VERSION ""

NS_ :

BS_:

BU_: MPAD CVADAS ADCAM ORC EVCU2 EPS ECM CVPAM CADM BSM2 BSM

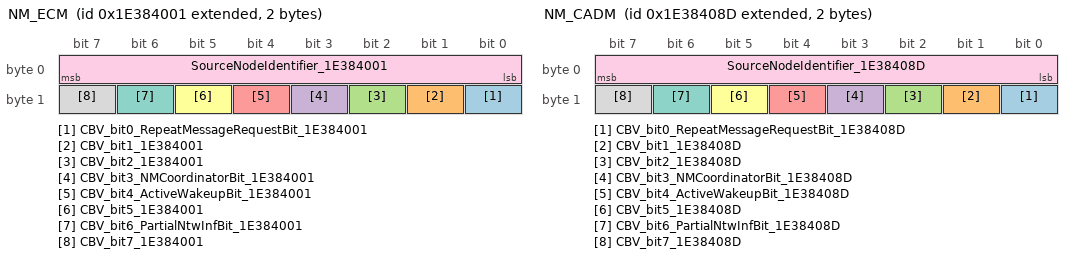
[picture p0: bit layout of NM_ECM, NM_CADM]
BO_ 2654486529 NM_ECM: 2 ECM
 SG_ CBV_bit0_RepeatMessageRequestBit_1E384001 : 8|1@0+ (1,0) [0|1] "" CVADAS,ADCAM,EVCU2,BSM2,CVPAM,CADM,BSM,ORC,EPS
 SG_ CBV_bit1_1E384001 : 9|1@0+ (1,0) [0|1] "" CVADAS,ADCAM,EVCU2,BSM2,CVPAM,CADM,BSM,ORC,EPS
 SG_ CBV_bit2_1E384001 : 10|1@0+ (1,0) [0|1] "" CVADAS,ADCAM,EVCU2,BSM2,CVPAM,CADM,BSM,ORC,EPS
 SG_ CBV_bit3_NMCoordinatorBit_1E384001 : 11|1@0+ (1,0) [0|1] "" CVADAS,ADCAM,EVCU2,BSM2,CVPAM,CADM,BSM,ORC,EPS
 SG_ CBV_bit4_ActiveWakeupBit_1E384001 : 12|1@0+ (1,0) [0|1] "" CVADAS,ADCAM,EVCU2,BSM2,CVPAM,CADM,BSM,ORC,EPS
 SG_ CBV_bit5_1E384001 : 13|1@0+ (1,0) [0|1] "" CVADAS,ADCAM,EVCU2,BSM2,CVPAM,CADM,BSM,ORC,EPS
 SG_ CBV_bit6_PartialNtwInfBit_1E384001 : 14|1@0+ (1,0) [0|1] "" CVADAS,ADCAM,EVCU2,BSM2,CVPAM,CADM,BSM,ORC,EPS
 SG_ CBV_bit7_1E384001 : 15|1@0+ (1,0) [0|1] "" CVADAS,ADCAM,EVCU2,BSM2,CVPAM,CADM,BSM,ORC,EPS
 SG_ SourceNodeIdentifier_1E384001 : 7|8@0+ (1,0) [0|255] "-"  CVADAS,ADCAM,EVCU2,BSM2,CVPAM,CADM,BSM,ORC,EPS

BO_ 2654486669 NM_CADM: 2 CADM
 SG_ CBV_bit0_RepeatMessageRequestBit_1E38408D : 8|1@0+ (1,0) [0|1] "" CVADAS,EVCU2,BSM2,CVPAM,BSM,ORC,EPS,ECM
 SG_ CBV_bit1_1E38408D : 9|1@0+ (1,0) [0|1] "" CVADAS,EVCU2,BSM2,CVPAM,BSM,ORC,EPS,ECM
 SG_ CBV_bit2_1E38408D : 10|1@0+ (1,0) [0|1] "" CVADAS,EVCU2,BSM2,CVPAM,BSM,ORC,EPS,ECM
 SG_ CBV_bit3_NMCoordinatorBit_1E38408D : 11|1@0+ (1,0) [0|1] "" CVADAS,EVCU2,BSM2,CVPAM,BSM,ORC,EPS,ECM
 SG_ CBV_bit4_ActiveWakeupBit_1E38408D : 12|1@0+ (1,0) [0|1] "" CVADAS,EVCU2,BSM2,CVPAM,BSM,ORC,EPS,ECM
 SG_ CBV_bit5_1E38408D : 13|1@0+ (1,0) [0|1] "" CVADAS,EVCU2,BSM2,CVPAM,BSM,ORC,EPS,ECM
 SG_ CBV_bit6_PartialNtwInfBit_1E38408D : 14|1@0+ (1,0) [0|1] "" CVADAS,EVCU2,BSM2,CVPAM,BSM,ORC,EPS,ECM
 SG_ CBV_bit7_1E38408D : 15|1@0+ (1,0) [0|1] "" CVADAS,EVCU2,BSM2,CVPAM,BSM,ORC,EPS,ECM
 SG_ SourceNodeIdentifier_1E38408D : 7|8@0+ (1,0) [0|255] "-"  CVADAS,EVCU2,BSM2,CVPAM,BSM,ORC,EPS,ECM

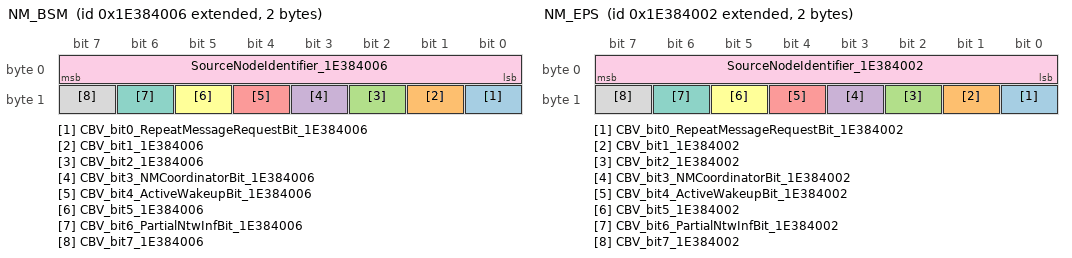
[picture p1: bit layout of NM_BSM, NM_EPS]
BO_ 2654486534 NM_BSM: 2 BSM
 SG_ CBV_bit0_RepeatMessageRequestBit_1E384006 : 8|1@0+ (1,0) [0|1] "" CVADAS,ADCAM,MPAD,EVCU2,BSM2,CVPAM,CADM,ORC,EPS,ECM
 SG_ CBV_bit1_1E384006 : 9|1@0+ (1,0) [0|1] "" CVADAS,ADCAM,MPAD,EVCU2,BSM2,CVPAM,CADM,ORC,EPS,ECM
 SG_ CBV_bit2_1E384006 : 10|1@0+ (1,0) [0|1] "" CVADAS,ADCAM,MPAD,EVCU2,BSM2,CVPAM,CADM,ORC,EPS,ECM
 SG_ CBV_bit3_NMCoordinatorBit_1E384006 : 11|1@0+ (1,0) [0|1] "" CVADAS,ADCAM,MPAD,EVCU2,BSM2,CVPAM,CADM,ORC,EPS,ECM
 SG_ CBV_bit4_ActiveWakeupBit_1E384006 : 12|1@0+ (1,0) [0|1] "" CVADAS,ADCAM,MPAD,EVCU2,BSM2,CVPAM,CADM,ORC,EPS,ECM
 SG_ CBV_bit5_1E384006 : 13|1@0+ (1,0) [0|1] "" CVADAS,ADCAM,MPAD,EVCU2,BSM2,CVPAM,CADM,ORC,EPS,ECM
 SG_ CBV_bit6_PartialNtwInfBit_1E384006 : 14|1@0+ (1,0) [0|1] "" CVADAS,ADCAM,MPAD,EVCU2,BSM2,CVPAM,CADM,ORC,EPS,ECM
 SG_ CBV_bit7_1E384006 : 15|1@0+ (1,0) [0|1] "" CVADAS,ADCAM,MPAD,EVCU2,BSM2,CVPAM,CADM,ORC,EPS,ECM
 SG_ SourceNodeIdentifier_1E384006 : 7|8@0+ (1,0) [0|255] "-"  CVADAS,ADCAM,MPAD,EVCU2,BSM2,CVPAM,CADM,ORC,EPS,ECM

BO_ 262 ENGINE_FD_2: 64 ECM
 SG_ PowertrainPrplsnActv : 181|1@0+ (1,0) [0|1] "" ADCAM,CADM,BSM
 SG_ MessageCounter_ENGINE2 : 435|4@0+ (1,0) [0|15] "-"  CVADAS,ADCAM,CVPAM,CADM,BSM,EPS
 SG_ LV12PwrFreeRq_W : 176|1@0+ (1,0) [0|1] "-"  Vector__XXX
 SG_ GasPedalPositionFailSts_W : 169|1@0+ (1,0) [0|1] "-"  ADCAM,CADM,BSM
 SG_ GasPedalPosition_W : 143|8@0+ (0.392,0) [0|99.568] "%"  ADCAM,BSM
 SG_ ESS_ENG_ST_W : 175|4@0+ (1,0) [0|15] "-"  CVADAS,ADCAM,CADM,BSM,EPS
 SG_ EngineSts_W : 87|2@0+ (1,0) [0|3] "-"  CVADAS,ADCAM,CVPAM,CADM,BSM,EPS
 SG_ EngineSpeed_W : 21|14@0+ (1,0) [0|16382] "1/min"  ADCAM,CADM,BSM,EPS
 SG_ ECM_LHOM_W : 188|1@0+ (1,0) [0|1] "-"  ADCAM,CADM
 SG_ CRC_ENGINE2 : 447|8@0+ (1,0) [0|255] "-"  CVADAS,ADCAM,CVPAM,CADM,BSM,EPS

BO_ 258 BRAKE_FD_2: 64 BSM
 SG_ YawRateFailSts_BSM : 87|1@0+ (1,0) [0|1] "-"  CVADAS,ADCAM,MPAD,CVPAM,CADM,EPS
 SG_ YawRate_BSM : 67|12@0+ (0.08,-163.84) [-163.84|163.68] "deg/s"  CVADAS,ADCAM,MPAD,CVPAM,CADM,EPS
 SG_ VehicleSpeedVSOSig : 4|13@0+ (0.0625,0) [0|511.875] "Km/h"  CVADAS,ADCAM,MPAD,EVCU2,BSM2,CVPAM,CADM,EPS,ECM
 SG_ TorqueRequest : 98|11@0+ (1,-500) [-500|1546] "-"  Vector__XXX
 SG_ TorqueReduct : 158|1@0+ (1,0) [0|1] "-"  Vector__XXX
 SG_ TorqueIncrease : 175|1@0+ (1,0) [0|1] "-"  Vector__XXX
 SG_ Slope : 135|8@0+ (1,-100) [-100|154] "%"  CVADAS,CVPAM,CADM
 SG_ PrefillActive : 86|1@0+ (1,0) [0|1] "-"  ADCAM,MPAD,CADM
 SG_ MessageCounter_BRAKE2 : 435|4@0+ (1,0) [0|15] "-"  CVADAS,ADCAM,EVCU2,BSM2,CVPAM,CADM,EPS,ECM
 SG_ LongAccelerationFailSts_BSM : 69|1@0+ (1,0) [0|1] "-"  CVADAS,ADCAM,MPAD,CVPAM,CADM
 SG_ LongAcceleration_BSM : 35|12@0+ (0.02,-40.96) [-40.96|40.92] "m/s^2"  CVADAS,ADCAM,MPAD,CVPAM,CADM,EPS
 SG_ LatAccelerationFailSts_BSM : 68|1@0+ (1,0) [0|1] "-"  CVADAS,ADCAM,MPAD,CVPAM,CADM
 SG_ LatAcceleration_BSM : 19|12@0+ (0.02,-40.96) [-40.96|40.92] "m/s^2"  CVADAS,ADCAM,MPAD,CVPAM,CADM,EPS
 SG_ InternalError_BSM : 191|1@0+ (1,0) [0|1] "-"  ADCAM,MPAD,CADM
 SG_ ESP_Sys_Stat : 71|2@0+ (1,0) [0|3] "-"  Vector__XXX
 SG_ ESCActive : 84|1@0+ (1,0) [0|1] "-"  MPAD,EVCU2,CVPAM,CADM
 SG_ CRC_BRAKE2 : 447|8@0+ (1,0) [0|255] "-"  CVADAS,ADCAM,EVCU2,BSM2,CVPAM,CADM,EPS,ECM
 SG_ BrakePedalPressure : 386|11@0+ (0.1,0) [0|200] "bar"  EVCU2,ECM
 SG_ BrakeInterventionSts : 103|1@0+ (1,0) [0|1] "-"  ADCAM,MPAD,BSM2,CADM
 SG_ BrakeBoostStat : 439|4@0+ (1,0) [0|14] "-"  Vector__XXX
 SG_ BrakeBoostPressure : 370|11@0+ (0.1,0) [0|200] "bar"  EVCU2,ECM
 SG_ Brake_MaxRegen_Ready : 359|2@0+ (1,0) [0|2] "-"  EVCU2
 SG_ ABSActive : 83|1@0+ (1,0) [0|1] "-"  MPAD,EVCU2,CVPAM,CADM,ECM
 SG_ WheelRPM_FR : 295|16@0+ (0.001953125,0) [0|127.9961] "Rev/s"  EVCU2,EPS
 SG_ WheelRPM_FL : 279|16@0+ (0.001953125,0) [0|127.9961] "Rev/s"  EVCU2,EPS
 SG_ Brk_Stat : 343|2@0+ (1,0) [0|2] "-"  CVADAS,ADCAM,MPAD,EVCU2,CVPAM,CADM,ECM
 SG_ PPPA_Engine_Torque_Enabled_BSM : 5|1@0+ (1,0) [0|1] "" Vector__XXX
 SG_ ParkingGearShiftReq_BSM : 22|3@0+ (1,0) [0|6] "" CVADAS,CVPAM
 SG_ ParkingInterventionSts : 7|2@0+ (1,0) [0|3] "" CVADAS,CVPAM
 SG_ BSM_ESASystemSts : 239|3@0+ (1,0) [0|6] "" CADM,EPS

BO_ 2654486530 NM_EPS: 2 EPS
 SG_ CBV_bit0_RepeatMessageRequestBit_1E384002 : 8|1@0+ (1,0) [0|1] "" CVADAS,ADCAM,MPAD,EVCU2,BSM2,CVPAM,CADM,BSM,ORC,ECM
 SG_ CBV_bit1_1E384002 : 9|1@0+ (1,0) [0|1] "" CVADAS,ADCAM,MPAD,EVCU2,BSM2,CVPAM,CADM,BSM,ORC,ECM
 SG_ CBV_bit2_1E384002 : 10|1@0+ (1,0) [0|1] "" CVADAS,ADCAM,MPAD,EVCU2,BSM2,CVPAM,CADM,BSM,ORC,ECM
 SG_ CBV_bit3_NMCoordinatorBit_1E384002 : 11|1@0+ (1,0) [0|1] "" CVADAS,ADCAM,MPAD,EVCU2,BSM2,CVPAM,CADM,BSM,ORC,ECM
 SG_ CBV_bit4_ActiveWakeupBit_1E384002 : 12|1@0+ (1,0) [0|1] "" CVADAS,ADCAM,MPAD,EVCU2,BSM2,CVPAM,CADM,BSM,ORC,ECM
 SG_ CBV_bit5_1E384002 : 13|1@0+ (1,0) [0|1] "" CVADAS,ADCAM,MPAD,EVCU2,BSM2,CVPAM,CADM,BSM,ORC,ECM
 SG_ CBV_bit6_PartialNtwInfBit_1E384002 : 14|1@0+ (1,0) [0|1] "" CVADAS,ADCAM,MPAD,EVCU2,BSM2,CVPAM,CADM,BSM,ORC,ECM
 SG_ CBV_bit7_1E384002 : 15|1@0+ (1,0) [0|1] "" CVADAS,ADCAM,MPAD,EVCU2,BSM2,CVPAM,CADM,BSM,ORC,ECM
 SG_ SourceNodeIdentifier_1E384002 : 7|8@0+ (1,0) [0|255] "-"  CVADAS,ADCAM,MPAD,EVCU2,BSM2,CVPAM,CADM,BSM,ORC,ECM

BO_ 524 BRAKE2_FD_2: 32 BSM2
 SG_ VehicleStandStillSts_B2 : 47|2@0+ (1,0) [0|2] "" MPAD,CADM,BSM
 SG_ BSM2_OpStat : 50|3@0+ (1,0) [0|5] "" MPAD,CADM,BSM
 SG_ Brake_OpStat_Sec : 53|3@0+ (1,0) [0|5] "" MPAD,CADM
 SG_ MessageCounter_BRAKE2_2 : 179|4@0+ (1,0) [0|15] "-"  MPAD,CADM,BSM,ORC
 SG_ CRC_BRAKE2_2 : 191|8@0+ (1,0) [0|255] "-"  MPAD,CADM,BSM,ORC
 SG_ BrkTrq_B2 : 6|15@0+ (3,0) [0|98301] "Nm"  MPAD,CADM
 SG_ BSM2_HEALTH_CHECK : 63|8@0+ (1,0) [0|255] "" BSM
 SG_ AEB_Type_Brk_B2 : 43|4@0+ (1,0) [0|15] "" MPAD,CADM

BO_ 257 BRAKE2_FD_1: 64 BSM2
 SG_ VehicleSpeedVSOSig_B2 : 36|13@0+ (0.0625,0) [0|511.875] "Km/h"  CVADAS,MPAD,CVPAM,CADM,EPS
 SG_ RHFWheelSpeed_B2 : 68|13@0+ (0.0625,0) [0|511.875] "Km/h"  MPAD,CADM
 SG_ RHF_FastPulseCounter_B2 : 95|8@0+ (1,0) [0|255] "pulse"  MPAD,CADM
 SG_ LHFWheelSpeed_B2 : 52|13@0+ (0.0625,0) [0|511.875] "Km/h"  MPAD,CADM
 SG_ LHF_FastPulseCounter_B2 : 87|8@0+ (1,0) [0|255] "pulse"  MPAD,CADM
 SG_ RHF_WheelSensorFailSts_B2 : 69|1@0+ (1,0) [0|1] "" MPAD,CADM
 SG_ RHF_Spin_B2 : 55|2@0+ (1,0) [0|3] "" MPAD,CADM
 SG_ MessageCounter_BRAKE2_1 : 435|4@0+ (1,0) [0|15] "-"  CVADAS,CADM,ORC,EPS
 SG_ LHF_WheelSensorFailSts_B2 : 53|1@0+ (1,0) [0|1] "" MPAD,CADM
 SG_ LHF_Spin_B2 : 39|2@0+ (1,0) [0|3] "" MPAD,CADM
 SG_ Inlet_Pressure_Pos : 98|2@0+ (1,0) [0|2] "" MPAD,CADM
 SG_ CRC_BRAKE2_1 : 447|8@0+ (1,0) [0|255] "-"  CVADAS,CADM,ORC,EPS
 SG_ Brk_Stat_B2 : 71|2@0+ (1,0) [0|2] "" MPAD,CADM
 SG_ ABSActive_B2 : 37|1@0+ (1,0) [0|1] "" MPAD,CADM
 SG_ Rear_Diff_BSM_RQ_B2 : 156|2@0+ (1,0) [0|2] "-"  Vector__XXX
 SG_ R_DIFF_TRQ_RQ_B2 : 151|9@0+ (10,0) [0|5100] "Nm"  Vector__XXX
 SG_ Ft_RrTrqCoupling_ModeRq_B2 : 158|2@0+ (1,0) [0|3] "-"  Vector__XXX
 SG_ Ft_RrAxleCoupling_TrqRq_B2 : 143|8@0+ (12,0) [0|3060] "Nm"  Vector__XXX

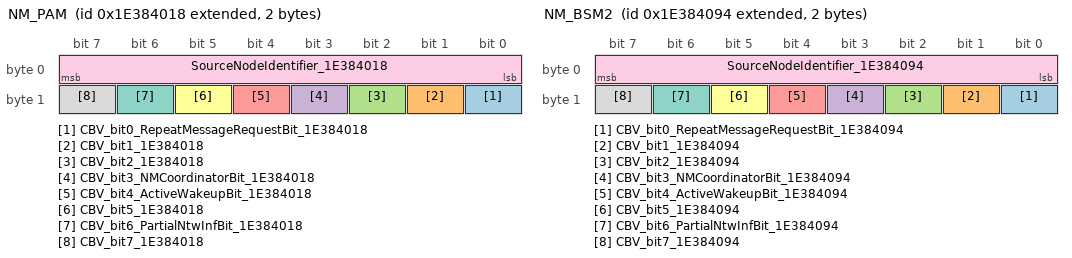
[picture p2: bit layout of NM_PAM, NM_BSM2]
BO_ 2654486552 NM_PAM: 2 CVADAS
 SG_ CBV_bit0_RepeatMessageRequestBit_1E384018 : 8|1@0+ (1,0) [0|1] "" ADCAM,MPAD,EVCU2,BSM2,CADM,BSM,ORC,EPS,ECM
 SG_ CBV_bit1_1E384018 : 9|1@0+ (1,0) [0|1] "" ADCAM,MPAD,EVCU2,BSM2,CADM,BSM,ORC,EPS,ECM
 SG_ CBV_bit2_1E384018 : 10|1@0+ (1,0) [0|1] "" ADCAM,MPAD,EVCU2,BSM2,CADM,BSM,ORC,EPS,ECM
 SG_ CBV_bit3_NMCoordinatorBit_1E384018 : 11|1@0+ (1,0) [0|1] "" ADCAM,MPAD,EVCU2,BSM2,CADM,BSM,ORC,EPS,ECM
 SG_ CBV_bit4_ActiveWakeupBit_1E384018 : 12|1@0+ (1,0) [0|1] "" ADCAM,MPAD,EVCU2,BSM2,CADM,BSM,ORC,EPS,ECM
 SG_ CBV_bit5_1E384018 : 13|1@0+ (1,0) [0|1] "" ADCAM,MPAD,EVCU2,BSM2,CADM,BSM,ORC,EPS,ECM
 SG_ CBV_bit6_PartialNtwInfBit_1E384018 : 14|1@0+ (1,0) [0|1] "" ADCAM,MPAD,EVCU2,BSM2,CADM,BSM,ORC,EPS,ECM
 SG_ CBV_bit7_1E384018 : 15|1@0+ (1,0) [0|1] "" ADCAM,MPAD,EVCU2,BSM2,CADM,BSM,ORC,EPS,ECM
 SG_ SourceNodeIdentifier_1E384018 : 7|8@0+ (1,0) [0|255] "-"  ADCAM,MPAD,EVCU2,BSM2,CADM,BSM,ORC,EPS,ECM

BO_ 2654486676 NM_BSM2: 2 BSM2
 SG_ CBV_bit0_RepeatMessageRequestBit_1E384094 : 8|1@0+ (1,0) [0|1] "" CVADAS,ADCAM,MPAD,EVCU2,CVPAM,CADM,BSM,ORC,EPS,ECM
 SG_ CBV_bit1_1E384094 : 9|1@0+ (1,0) [0|1] "" CVADAS,ADCAM,MPAD,EVCU2,CVPAM,CADM,BSM,ORC,EPS,ECM
 SG_ CBV_bit2_1E384094 : 10|1@0+ (1,0) [0|1] "" CVADAS,ADCAM,MPAD,EVCU2,CVPAM,CADM,BSM,ORC,EPS,ECM
 SG_ CBV_bit3_NMCoordinatorBit_1E384094 : 11|1@0+ (1,0) [0|1] "" CVADAS,ADCAM,MPAD,EVCU2,CVPAM,CADM,BSM,ORC,EPS,ECM
 SG_ CBV_bit4_ActiveWakeupBit_1E384094 : 12|1@0+ (1,0) [0|1] "" CVADAS,ADCAM,MPAD,EVCU2,CVPAM,CADM,BSM,ORC,EPS,ECM
 SG_ CBV_bit5_1E384094 : 13|1@0+ (1,0) [0|1] "" CVADAS,ADCAM,MPAD,EVCU2,CVPAM,CADM,BSM,ORC,EPS,ECM
 SG_ CBV_bit6_PartialNtwInfBit_1E384094 : 14|1@0+ (1,0) [0|1] "" CVADAS,ADCAM,MPAD,EVCU2,CVPAM,CADM,BSM,ORC,EPS,ECM
 SG_ CBV_bit7_1E384094 : 15|1@0+ (1,0) [0|1] "" CVADAS,ADCAM,MPAD,EVCU2,CVPAM,CADM,BSM,ORC,EPS,ECM
 SG_ SourceNodeIdentifier_1E384094 : 7|8@0+ (1,0) [0|255] "-"  CVADAS,ADCAM,MPAD,EVCU2,CVPAM,CADM,BSM,ORC,EPS,ECM

BO_ 727 CVPAM_FD_Data2: 64 CVADAS
 SG_ PA_SideSensor_RearRight_Dist : 49|10@0+ (1,0) [0|1022] "cm"  MPAD,CADM
 SG_ PA_SideSensor_RearRight_Conf : 102|2@0+ (1,0) [0|3] "" MPAD,CADM
 SG_ PA_SideSensor_RearLeft_Dist : 33|10@0+ (1,0) [0|1022] "cm"  MPAD,CADM
 SG_ PA_SideSensor_RearLeft_Conf : 100|2@0+ (1,0) [0|3] "" MPAD,CADM
 SG_ PA_SideSensor_FrontRight_Dist : 1|10@0+ (1,0) [0|1022] "cm"  MPAD,CADM
 SG_ PA_SideSensor_FrontRight_Conf : 55|2@0+ (1,0) [0|3] "" MPAD,CADM
 SG_ PA_SideSensor_FrontLeft_Dist : 17|10@0+ (1,0) [0|1022] "cm"  MPAD,CADM
 SG_ PA_SideSensor_FrontLeft_Conf : 98|2@0+ (1,0) [0|3] "" MPAD,CADM
 SG_ PA_Right_Sensor_Det_Health : 23|2@0+ (1,0) [0|2] "" MPAD,CADM
 SG_ PA_Line_RM_Style : 68|4@0+ (1,0) [0|7] "" MPAD,CADM
 SG_ PA_Line_RM_Heading : 96|9@0+ (0.5,-128) [-128|127.5] "deg"  MPAD,CADM
 SG_ PA_Line_RM_Color : 87|3@0+ (1,0) [0|4] "" MPAD,CADM
 SG_ PA_Line_LM_Style : 84|4@0+ (1,0) [0|7] "" MPAD,CADM
 SG_ PA_Line_LM_Heading : 112|9@0+ (0.5,-128) [-128|127.5] "deg"  MPAD,CADM
 SG_ PA_Line_LM_Color : 71|3@0+ (1,0) [0|4] "" MPAD,CADM
 SG_ PA_Left_Sensor_Det_Health : 7|2@0+ (1,0) [0|2] "" MPAD,CADM
 SG_ PA_Lane_Dection_Health : 39|2@0+ (1,0) [0|2] "" MPAD,CADM
 SG_ MessageCounter_CVPAM_FD_Data2 : 435|4@0+ (1,0) [0|15] "-"  MPAD,CADM
 SG_ MAC_CVPAM_FD_Data2 : 471|48@0+ (1,0) [0|0] "-"  MPAD,CADM
 SG_ CRC_CVPAM_FD_Data2 : 447|8@0+ (1,0) [0|255] "-"  MPAD,CADM
 SG_ Cntr_CVPAM_FD_Data2 : 455|16@0+ (1,0) [0|65535] "-"  MPAD,CADM
 SG_ PA_Line_RM_Heading_Conf : 37|4@0+ (1,0) [0|15] "" MPAD,CADM
 SG_ PA_Line_RM_Distance_Conf : 5|4@0+ (1,0) [0|15] "" MPAD,CADM
 SG_ PA_Line_RM_Distance : 64|9@0+ (1,0) [0|511] "cm"  MPAD,CADM
 SG_ PA_Line_LM_Heading_Conf : 53|4@0+ (1,0) [0|15] "" MPAD,CADM
 SG_ PA_Line_LM_Distance_Conf : 21|4@0+ (1,0) [0|15] "" MPAD,CADM
 SG_ PA_Line_LM_Distance : 80|9@0+ (1,0) [0|511] "cm"  MPAD,CADM
 SG_ Reserved_for_Functional_Safety_ : 431|12@0+ (0,0) [0|0] "" MPAD,CADM

BO_ 726 CVPAM_FD_Data: 64 CVADAS
 SG_ PA_Obj6_Type : 372|3@0+ (1,0) [0|7] "" MPAD,CADM
 SG_ PA_Obj6_Range_2 : 401|10@0+ (1,0) [0|1023] "cm"  MPAD,CADM
 SG_ PA_Obj6_Range : 81|10@0+ (1,0) [0|1023] "cm"  MPAD,CADM
 SG_ PA_Obj6_Conf : 115|2@0+ (1,0) [0|3] "" MPAD,CADM
 SG_ PA_Obj6_Angle_2 : 208|9@0+ (1,0) [0|511] "deg"  MPAD,CADM
 SG_ PA_Obj6_Angle : 304|9@0+ (1,0) [0|511] "deg"  MPAD,CADM
 SG_ PA_Obj5_Type : 375|3@0+ (1,0) [0|7] "" MPAD,CADM
 SG_ PA_Obj5_Range_2 : 385|10@0+ (1,0) [0|1023] "cm"  MPAD,CADM
 SG_ PA_Obj5_Range : 65|10@0+ (1,0) [0|1023] "cm"  MPAD,CADM
 SG_ PA_Obj5_Conf : 117|2@0+ (1,0) [0|3] "" MPAD,CADM
 SG_ PA_Obj5_Angle_2 : 192|9@0+ (1,0) [0|511] "deg"  MPAD,CADM
 SG_ PA_Obj5_Angle : 288|9@0+ (1,0) [0|511] "deg"  MPAD,CADM
 SG_ PA_Obj4_Type : 391|3@0+ (1,0) [0|7] "" MPAD,CADM
 SG_ PA_Obj4_Range_2 : 369|10@0+ (1,0) [0|1023] "cm"  MPAD,CADM
 SG_ PA_Obj4_Range : 49|10@0+ (1,0) [0|1023] "cm"  MPAD,CADM
 SG_ PA_Obj4_Conf : 119|2@0+ (1,0) [0|3] "" MPAD,CADM
 SG_ PA_Obj4_Angle_2 : 176|9@0+ (1,0) [0|511] "deg"  MPAD,CADM
 SG_ PA_Obj4_Angle : 272|9@0+ (1,0) [0|511] "deg"  MPAD,CADM
 SG_ PA_Obj3_Type : 388|3@0+ (1,0) [0|7] "" MPAD,CADM
 SG_ PA_Obj3_Range_2 : 353|10@0+ (1,0) [0|1023] "cm"  MPAD,CADM
 SG_ PA_Obj3_Range : 33|10@0+ (1,0) [0|1023] "cm"  MPAD,CADM
 SG_ PA_Obj3_Conf : 87|2@0+ (1,0) [0|3] "" MPAD,CADM
 SG_ PA_Obj3_Angle_2 : 160|9@0+ (1,0) [0|511] "deg"  MPAD,CADM
 SG_ PA_Obj3_Angle : 256|9@0+ (1,0) [0|511] "deg"  MPAD,CADM
 SG_ PA_Obj2_Type : 404|3@0+ (1,0) [0|7] "" MPAD,CADM
 SG_ PA_Obj2_Range_2 : 337|10@0+ (1,0) [0|1023] "cm"  MPAD,CADM
 SG_ PA_Obj2_Range : 17|10@0+ (1,0) [0|1023] "cm"  MPAD,CADM
 SG_ PA_Obj2_Conf : 71|2@0+ (1,0) [0|3] "" MPAD,CADM
 SG_ PA_Obj2_Angle_2 : 144|9@0+ (1,0) [0|511] "deg"  MPAD,CADM
 SG_ PA_Obj2_Angle : 240|9@0+ (1,0) [0|511] "deg"  MPAD,CADM
 SG_ PA_Obj1_Type : 407|3@0+ (1,0) [0|7] "" MPAD,CADM
 SG_ PA_Obj1_Range_2 : 321|10@0+ (1,0) [0|1023] "cm"  MPAD,CADM
 SG_ PA_Obj1_Range : 1|10@0+ (1,0) [0|1023] "cm"  MPAD,CADM
 SG_ PA_Obj1_Conf : 55|2@0+ (1,0) [0|3] "" MPAD,CADM
 SG_ PA_Obj1_Angle_2 : 128|9@0+ (1,0) [0|511] "deg"  MPAD,CADM
 SG_ PA_Obj1_Angle : 224|9@0+ (1,0) [0|511] "deg"  MPAD,CADM
 SG_ PA_Front_Sensor_Det_Health : 437|2@0+ (1,0) [0|2] "" MPAD,CADM
 SG_ MessageCounter_CVPAM_FD_Data : 435|4@0+ (1,0) [0|15] "-"  MPAD,CADM,EPS
 SG_ MAC_CVPAM_FD_Data : 471|48@0+ (1,0) [0|0] "-"  MPAD,CADM
 SG_ CRC_CVPAM_FD_Data : 447|8@0+ (1,0) [0|255] "-"  MPAD,CADM,EPS
 SG_ Cntr_CVPAM_FD_Data : 455|16@0+ (1,0) [0|65535] "-"  MPAD,CADM
 SG_ Reserved_for_functional_safety_2D6 : 417|12@0+ (0,0) [0|0] "" MPAD,CADM

BO_ 1156 BRAKE2_FD_3: 32 BSM2
 SG_ RollsModeAct_B2 : 6|1@0+ (1,0) [0|1] "" MPAD,CADM
 SG_ MessageCounter_BRAKE2_3 : 179|4@0+ (1,0) [0|15] "-"  CADM,ORC
 SG_ CRC_BRAKE2_3 : 191|8@0+ (1,0) [0|255] "-"  CADM,ORC
 SG_ BSM2_FaultSts : 5|1@0+ (1,0) [0|1] "" CADM
 SG_ ABSFailSts_B2 : 7|1@0+ (1,0) [0|1] "" MPAD,CADM

BO_ 280 ADAS_FD_INFO: 32 ADCAM
 SG_ Object_Dist : 127|8@0+ (1,0) [0|255] "m"  EVCU2,BSM,ORC,ECM
 SG_ MessageCounter_ADAS_FD_INFO : 179|4@0+ (1,0) [0|15] "-"  CVADAS,EVCU2,BSM2,CVPAM,BSM,ORC,EPS,ECM
 SG_ CRC_ADAS_FD_INFO : 191|8@0+ (1,0) [0|255] "-"  CVADAS,EVCU2,BSM2,CVPAM,BSM,ORC,EPS,ECM
 SG_ ACC_DsrSpeedKPH : 119|8@0+ (1,0) [0|255] "km/h"  EVCU2,ECM
 SG_ Intervention : 163|12@0+ (0.01,-16) [-16|24.95] "m/s2"  BSM2,BSM,ORC
 SG_ HIS_Req : 89|1@0+ (1,0) [0|1] "-"  BSM2,BSM,ORC
 SG_ GrMax_Rq_ACC : 150|4@0+ (1,0) [0|15] "-"  BSM
 SG_ CIPV_Fused : 101|1@0+ (1,0) [0|1] "-"  ORC
 SG_ Brake_Jerk_Req : 100|1@0+ (1,0) [0|1] "-"  BSM2,BSM
 SG_ ACC_Engine_Torque_Enabled : 111|1@0+ (1,0) [0|1] "-"  BSM
 SG_ ACC_Drive_Cmd : 151|1@0+ (1,0) [0|1] "-"  BSM
 SG_ Prefill_Req : 91|1@0+ (1,0) [0|1] "-"  BSM2,BSM
 SG_ PEB_SystemSts : 90|1@0+ (1,0) [0|1] "-"  ORC
 SG_ MRM_STATUS : 23|3@0+ (1,0) [0|6] "" EVCU2,BSM,ORC
 SG_ LANE_CHANGE_SIDE : 95|2@0+ (1,0) [0|2] "" ORC
 SG_ HAS_Status : 106|2@0+ (1,0) [0|3] "" CVADAS,BSM2,CVPAM,BSM,EPS
 SG_ HAS_OpStat_Prim : 4|3@0+ (1,0) [0|5] "" ORC
 SG_ HAS_LAT_CTRL_RequestSts : 110|2@0+ (1,0) [0|3] "-"  EPS
 SG_ ESCALATION_TYPE : 12|3@0+ (1,0) [0|4] "" ORC
 SG_ DDD_SystemSts : 103|1@0+ (1,0) [0|1] "-"  ORC
 SG_ DDD_Setting_Avail : 102|1@0+ (1,0) [0|1] "-"  Vector__XXX
 SG_ CADM_OpStat : 7|3@0+ (1,0) [0|5] "" Vector__XXX
 SG_ AEB_Type : 167|4@0+ (1,0) [0|14] "-"  BSM2,BSM,ORC
 SG_ AEB_Systemsts : 99|2@0+ (1,0) [0|2] "-"  ORC
 SG_ AEB_Sensitivity_Setting : 1|2@0+ (1,0) [0|2] "" Vector__XXX
 SG_ ACC_Systemsts : 183|4@0+ (1,0) [0|14] "-"  CVADAS,EVCU2,BSM2,CVPAM,BSM,ORC
 SG_ ACC_StopStart : 97|2@0+ (1,0) [0|2] "-"  ECM
 SG_ SteeringVibration_Type : 67|4@0+ (1,0) [0|14] "-"  EPS
 SG_ SteeringVibration_Rq : 135|1@0+ (1,0) [0|1] "-"  EPS
 SG_ LKA_LAT_CTRL_RequestSts : 108|2@0+ (1,0) [0|3] "-"  EPS
 SG_ LANE_CHANGE_STATUS : 71|4@0+ (1,0) [0|14] "" ORC
 SG_ LC_Jerk : 104|1@0+ (1,0) [0|1] "-"  BSM
 SG_ CADM2_EPSSEC_FAIL : 8|1@0+ (1,0) [0|1] "" EPS
 SG_ TorqueOverlaySteeringReq : 130|11@0+ (0.0048828125,-5) [-5|4.995117188] "-"  ORC,EPS
 SG_ ESASystemSts : 31|3@0+ (1,0) [0|6] "-"  BSM,EPS
 SG_ ESA_TorqueOverlaySteeringReq : 39|32@0+ (0.0048828125,-5) [-5|20971514.9951172] "-"  EPS
 SG_ ESA_LAT_CTRL_RequestSts : 28|2@0+ (1,0) [0|2] "-"  EPS
 SG_ ESA_LaneClear_Status : 26|3@0+ (1,0) [0|6] "-"  BSM
 SG_ ESA_FailSts : 17|1@0+ (1,0) [0|1] "-"  BSM,EPS

BO_TX_BU_ 2654486552 : CVADAS,CVPAM;
BO_TX_BU_ 727 : CVADAS,CVPAM;
BO_TX_BU_ 726 : CVADAS,CVPAM;
BO_TX_BU_ 280 : ADCAM,MPAD,CADM;
CM_ SG_ 280 Object_Dist "It indicates the distance to the recognized object";
CM_ SG_ 280 MessageCounter_ADAS_FD_INFO "This signal is a counter used for safety checks strategies. This counter is incremented of 1 (one) unit at each frame transmission.";
CM_ SG_ 280 CRC_ADAS_FD_INFO "CRC according to SAE J1850 standard at each frame transmission.";
CM_ SG_ 280 ACC_DsrSpeedKPH "Desired speed in kilometers per hour";
CM_ SG_ 262 PowertrainPrplsnActv "Powertrain Propulsion Status.";
CM_ SG_ 262 MessageCounter_ENGINE2 "This signal is a counter used for safety checks strategies. This counter is incremented of 1 (one) unit at each frame transmission.";
CM_ SG_ 262 LV12PwrFreeRq_W "-";
CM_ SG_ 262 GasPedalPositionFailSts_W "-";
CM_ SG_ 262 GasPedalPosition_W "-";
CM_ SG_ 262 ESS_ENG_ST_W "ESS Engine State";
CM_ SG_ 262 EngineSts_W "-";
CM_ SG_ 262 EngineSpeed_W "It gives information on C-CAN network about  engine speed";
CM_ SG_ 262 ECM_LHOM_W "-";
CM_ SG_ 262 CRC_ENGINE2 "CRC according to SAE J1850 standard at each frame transmission.";
CM_ SG_ 258 YawRateFailSts_BSM "This signal indicates the Status of Yaw Rate Signal";
CM_ SG_ 258 YawRate_BSM "This signal indicates the Yaw Rate Value";
CM_ SG_ 258 VehicleSpeedVSOSig "It is the average vehicle speed calculated.";
CM_ SG_ 258 TorqueRequest "[NOTE FOR MASERATI PROGRAMS ONLY] ICE & MHEV BSG: signal is referred to flywheel torque - Unit: Nm; MHEV P1R & BEV: signal is referred to wheel torque - Unit: daNm";
CM_ SG_ 258 TorqueReduct "0";
CM_ SG_ 258 TorqueIncrease "0";
CM_ SG_ 258 Slope "Slope value detected by BSM";
CM_ SG_ 258 PrefillActive "This signal indicates the prefill function status.";
CM_ SG_ 258 MessageCounter_BRAKE2 "This signal is a counter used for safety checks strategies. This counter is incremented of 1 (one) unit at each frame transmission.";
CM_ SG_ 258 LongAccelerationFailSts_BSM "This signal indicates the status of Longitudinal acceleration signal";
CM_ SG_ 258 LongAcceleration_BSM "This signal indicates the Longitudinal Acceleration Value";
CM_ SG_ 258 LatAccelerationFailSts_BSM "This signal indicates the status of Lateral Acceleration Signal";
CM_ SG_ 258 LatAcceleration_BSM "This signal indicates the Lateral Acceleration Value";
CM_ SG_ 258 InternalError_BSM "This signal indicates if an internal error has been processed";
CM_ SG_ 258 ESP_Sys_Stat "0";
CM_ SG_ 258 ESCActive "This signal is set to Active when the brake intervention by ESC is active.";
CM_ SG_ 258 CRC_BRAKE2 "CRC according to SAE J1850 standard at each frame transmission.";
CM_ SG_ 258 BrakePedalPressure "Pressure Information from Brake Pedal Simulator Pressure Sensor";
CM_ SG_ 258 BrakeInterventionSts "This signal is ?active? when the brake intervention is due to BSM events and ?not active? when the brake intervention is due to the driver";
CM_ SG_ 258 BrakeBoostStat "eBoost System Status INIT, eBOOST, PUSH-THROUGH, SNA";
CM_ SG_ 258 BrakeBoostPressure "Pressure Information from Brake Booster Pressure Sensor";
CM_ SG_ 258 Brake_MaxRegen_Ready "maximum Brake regen ready";
CM_ SG_ 258 ABSActive "This signal is set to Active when the ABS functionality is active.";
CM_ SG_ 280 Intervention "Request to set target acceleration/deceleration for any feature";
CM_ SG_ 280 HIS_Req "Used to command Stop during Stop and Go ACC and FSFCW+";
CM_ SG_ 280 GrMax_Rq_ACC "Used to request Max Gear from TCM";
CM_ SG_ 280 CIPV_Fused "Closest in-path vehicle is fused True = 1";
CM_ SG_ 280 Brake_Jerk_Req "Request from DASM to perform Jerk Warning";
CM_ SG_ 280 ACC_Engine_Torque_Enabled "An enable bit that Torque commands should be followed";
CM_ SG_ 280 ACC_Drive_Cmd "ACC Drive Command";
CM_ SG_ 524 VehicleStandStillSts_B2 "VehicleStandStillSts_B2";
CM_ SG_ 524 BSM2_OpStat "Capability of the secondary brake control module to provide deceleration and/or stability control";
CM_ SG_ 524 Brake_OpStat_Sec "Capability of the Braking system to perform deceleration and/or stability control as reported by the secondary actuator.";
CM_ SG_ 257 VehicleSpeedVSOSig_B2 "VehicleSpeedVSOSig_B2";
CM_ SG_ 257 RHFWheelSpeed_B2 "RHFWheelSpeed_B2";
CM_ SG_ 257 RHF_FastPulseCounter_B2 "RHF_FastPulseCounter_B2";
CM_ SG_ 257 LHFWheelSpeed_B2 "LHFWheelSpeed_B2";
CM_ SG_ 257 LHF_FastPulseCounter_B2 "LHF_FastPulseCounter_B2";
CM_ SG_ 258 WheelRPM_FR "Wheel RPM front right";
CM_ SG_ 258 WheelRPM_FL "Wheel RPM front left";
CM_ SG_ 258 Brk_Stat "Brake state";
CM_ SG_ 280 Prefill_Req "Prefill command of Brake System by DASM";
CM_ SG_ 280 PEB_SystemSts "PEB System Status";
CM_ SG_ 280 MRM_STATUS "Status of the minimum risk maneuver to handle system faults or driver abuse as understood by primary controller";
CM_ SG_ 280 LANE_CHANGE_SIDE "Direction of the currently in-progress lane change from a vehicle perspective";
CM_ SG_ 280 HAS_Status "Highway Assist System Status as reported by the main controller";
CM_ SG_ 280 HAS_OpStat_Prim "Capability of the primary controller to perform sensing, computing, and actuation";
CM_ SG_ 280 HAS_LAT_CTRL_RequestSts "HAS_LAT_CTRL_RequestSts";
CM_ SG_ 280 ESCALATION_TYPE "Type of HMI escalation to be provided to driver from primary controller";
CM_ SG_ 280 DDD_SystemSts "DDD System Status";
CM_ SG_ 280 DDD_Setting_Avail "DDD_Setting Av Status";
CM_ SG_ 280 CADM_OpStat "Capability of primary controller to sense and compute a valid trajectory path based on external data dependencies and internal failures";
CM_ SG_ 280 AEB_Type "AEB Type";
CM_ SG_ 280 AEB_Systemsts "AEB System Status";
CM_ SG_ 280 AEB_Sensitivity_Setting "AEB sensitivity status";
CM_ SG_ 280 ACC_Systemsts "ACC System Status";
CM_ SG_ 280 ACC_StopStart "Allows StopStart when ACC is engaged";
CM_ SG_ 258 PPPA_Engine_Torque_Enabled_BSM "Whether or not PPPA is requesting engine torque";
CM_ SG_ 258 ParkingGearShiftReq_BSM "CVPAM Request to autonomously shift gears";
CM_ SG_ 727 PA_SideSensor_RearRight_Dist "PA SideSensor RearRight Dist";
CM_ SG_ 727 PA_SideSensor_RearRight_Conf "PA SideSensor RearRight Conf";
CM_ SG_ 727 PA_SideSensor_RearLeft_Dist "PA SideSensor RearLeft Dist";
CM_ SG_ 727 PA_SideSensor_RearLeft_Conf "PA SideSensor RearLeft Conf";
CM_ SG_ 727 PA_SideSensor_FrontRight_Dist "PA SideSensor FrontRight Dist";
CM_ SG_ 727 PA_SideSensor_FrontRight_Conf "PA SideSensor FrontRight Conf";
CM_ SG_ 727 PA_SideSensor_FrontLeft_Dist "PA SideSensor FrontLeft Dist";
CM_ SG_ 727 PA_SideSensor_FrontLeft_Conf "PA SideSensor FrontLeft Conf";
CM_ SG_ 727 PA_Right_Sensor_Det_Health "PA Right Sensor Det Health";
CM_ SG_ 727 PA_Line_RM_Style "PA Line RM Style";
CM_ SG_ 727 PA_Line_RM_Heading "PA Line RM Heading";
CM_ SG_ 727 PA_Line_RM_Color "PA Line RM Color";
CM_ SG_ 727 PA_Line_LM_Style "PA Line LM Style";
CM_ SG_ 727 PA_Line_LM_Heading "PA Line LM Heading";
CM_ SG_ 727 PA_Line_LM_Color "PA Line LM Color";
CM_ SG_ 727 PA_Left_Sensor_Det_Health "PA Left Sensor Det Health";
CM_ SG_ 727 PA_Lane_Dection_Health "PA Lane Dection Health";
CM_ SG_ 727 MessageCounter_CVPAM_FD_Data2 "This signal is a counter used for safety checks strategies. This counter is incremented of 1 (one) unit at each frame transmission.";
CM_ SG_ 727 MAC_CVPAM_FD_Data2 "-";
CM_ SG_ 727 CRC_CVPAM_FD_Data2 "CRC according to SAE J1850 standard at each frame transmission.";
CM_ SG_ 726 PA_Obj6_Type "PA Obj5 Type";
CM_ SG_ 726 PA_Obj6_Range_2 "PA Obj6 Range_2";
CM_ SG_ 726 PA_Obj6_Range "PA Obj6 Range";
CM_ SG_ 726 PA_Obj6_Conf "PA Obj6 Conf";
CM_ SG_ 726 PA_Obj6_Angle_2 "PA Obj6 Angle_2";
CM_ SG_ 726 PA_Obj6_Angle "PA Obj6 Angle";
CM_ SG_ 726 PA_Obj5_Type "PA Obj5 Type";
CM_ SG_ 726 PA_Obj5_Range_2 "PA Obj5 Range_2";
CM_ SG_ 726 PA_Obj5_Range "PA Obj5 Range";
CM_ SG_ 726 PA_Obj5_Conf "PA Obj5 Conf";
CM_ SG_ 726 PA_Obj5_Angle_2 "PA Obj5 Angle_2";
CM_ SG_ 726 PA_Obj5_Angle "PA Obj5 Angle";
CM_ SG_ 726 PA_Obj4_Type "PA Obj4 Type";
CM_ SG_ 726 PA_Obj4_Range_2 "PA Obj4 Range_2";
CM_ SG_ 726 PA_Obj4_Range "PA Obj4 Range";
CM_ SG_ 726 PA_Obj4_Conf "PA Obj4 Conf";
CM_ SG_ 726 PA_Obj4_Angle_2 "PA Obj4 Angle_2";
CM_ SG_ 726 PA_Obj4_Angle "PA Obj4 Angle";
CM_ SG_ 726 PA_Obj3_Type "PA Obj3 Type";
CM_ SG_ 726 PA_Obj3_Range_2 "PA Obj3 Range_2";
CM_ SG_ 726 PA_Obj3_Range "PA Obj3 Range";
CM_ SG_ 726 PA_Obj3_Conf "PA Obj3 Conf";
CM_ SG_ 726 PA_Obj3_Angle_2 "PA Obj3 Angle_2";
CM_ SG_ 726 PA_Obj3_Angle "PA Obj3 Angle";
CM_ SG_ 726 PA_Obj2_Type "PA Obj2 Type";
CM_ SG_ 726 PA_Obj2_Range_2 "PA Obj2 Range_2";
CM_ SG_ 726 PA_Obj2_Range "PA Obj2 Range";
CM_ SG_ 726 PA_Obj2_Conf "PA Obj2 Conf";
CM_ SG_ 726 PA_Obj2_Angle_2 "PA Obj2 Angle_2";
CM_ SG_ 726 PA_Obj2_Angle "PA Obj2 Angle";
CM_ SG_ 726 PA_Obj1_Type "PA Obj1 Type";
CM_ SG_ 726 PA_Obj1_Range_2 "PA Obj1 Range_2";
CM_ SG_ 726 PA_Obj1_Range "PA Obj1 Range";
CM_ SG_ 726 PA_Obj1_Conf "PA Obj1 Conf";
CM_ SG_ 726 PA_Obj1_Angle_2 "PA Obj1 Angle_2";
CM_ SG_ 726 PA_Obj1_Angle "PA Obj1 Angle";
CM_ SG_ 726 PA_Front_Sensor_Det_Health "PA Front Sensor Det Health";
CM_ SG_ 726 MessageCounter_CVPAM_FD_Data "This signal is a counter used for safety checks strategies. This counter is incremented of 1 (one) unit at each frame transmission.";
CM_ SG_ 726 MAC_CVPAM_FD_Data "-";
CM_ SG_ 726 CRC_CVPAM_FD_Data "CRC according to SAE J1850 standard at each frame transmission.";
CM_ SG_ 1156 RollsModeAct_B2 "RollsModeAct_B2";
CM_ SG_ 1156 MessageCounter_BRAKE2_3 "This signal is a counter used for safety checks strategies. This counter is incremented of 1 (one) unit at each frame transmission.";
CM_ SG_ 1156 CRC_BRAKE2_3 "CRC according to SAE J1850 standard at each frame transmission.";
CM_ SG_ 1156 BSM2_FaultSts "BSM2 FaultSts";
CM_ SG_ 1156 ABSFailSts_B2 "ABSFailSts_B2";
CM_ SG_ 524 MessageCounter_BRAKE2_2 "This signal is a counter used for safety checks strategies. This counter is incremented of 1 (one) unit at each frame transmission.";
CM_ SG_ 524 CRC_BRAKE2_2 "CRC according to SAE J1850 standard at each frame transmission.";
CM_ SG_ 524 BrkTrq_B2 "BrkTrq_B2";
CM_ SG_ 257 RHF_WheelSensorFailSts_B2 "RHF_WheelSensorFailSts_B2";
CM_ SG_ 257 RHF_Spin_B2 "RHF_Spin_B2";
CM_ SG_ 257 MessageCounter_BRAKE2_1 "This signal is a counter used for safety checks strategies. This counter is incremented of 1 (one) unit at each frame transmission.";
CM_ SG_ 257 LHF_WheelSensorFailSts_B2 "LHF_WheelSensorFailSts_B2";
CM_ SG_ 257 LHF_Spin_B2 "LHF_Spin_B2";
CM_ SG_ 257 Inlet_Pressure_Pos "Inlet Pressure Pos Indicates if the secondary brake control module detects upstream brake pressure";
CM_ SG_ 257 CRC_BRAKE2_1 "CRC according to SAE J1850 standard at each frame transmission.";
CM_ SG_ 257 Brk_Stat_B2 "Signifies a general braking event (both autonomous and driver requested) with the secondary brake control module";
CM_ SG_ 257 ABSActive_B2 "ABSActive_B2";
CM_ SG_ 280 SteeringVibration_Type "Type of Steering Wheel Vibration Request";
CM_ SG_ 280 SteeringVibration_Rq "Request to activate Steering Wheel Vibration";
CM_ SG_ 280 LKA_LAT_CTRL_RequestSts "LKA_LAT_CTRL_RequestSts";
CM_ SG_ 280 LANE_CHANGE_STATUS "Status of assisted lane change maneuver";
CM_ SG_ 280 LC_Jerk "Lane Centering request for brake jerk";
CM_ SG_ 524 BSM2_HEALTH_CHECK "BSM2_HEALTH_CHECK";
CM_ SG_ 258 ParkingInterventionSts "Current status of BSM during Autonomous Parking Maneuver";
CM_ SG_ 524 AEB_Type_Brk_B2 "AEB_Type_Brk_B2";
CM_ SG_ 280 CADM2_EPSSEC_FAIL "CADM2 detection of failure to communicate to EPS";
CM_ SG_ 257 Rear_Diff_BSM_RQ_B2 "ESP Requested Rear Differential State";
CM_ SG_ 257 R_DIFF_TRQ_RQ_B2 "Desired Torque for Rear Diff.";
CM_ SG_ 257 Ft_RrTrqCoupling_ModeRq_B2 "ESP Requested Center Differential State";
CM_ SG_ 257 Ft_RrAxleCoupling_TrqRq_B2 "Desired Torque for Center Diff";
CM_ SG_ 280 TorqueOverlaySteeringReq "TorqueOverlaySteeringReq";
CM_ SG_ 258 BSM_ESASystemSts "Brake System ESA Status";
CM_ SG_ 280 ESASystemSts "ESA System Status";
CM_ SG_ 280 ESA_TorqueOverlaySteeringReq "ESA Steering Torque Overlay Request";
CM_ SG_ 280 ESA_LAT_CTRL_RequestSts "ESA Lateral Control Request Status";
CM_ SG_ 280 ESA_LaneClear_Status "Lane Clear Information";
CM_ SG_ 280 ESA_FailSts "ESA Failure Status";
CM_ SG_ 727 PA_Line_RM_Heading_Conf "PA Line RM Heading Conf";
CM_ SG_ 727 PA_Line_RM_Distance_Conf "PA Line RM Distance Conf";
CM_ SG_ 727 PA_Line_RM_Distance "PA Line RM Distance";
CM_ SG_ 727 PA_Line_LM_Heading_Conf "PA Line LM Heading Conf";
CM_ SG_ 727 PA_Line_LM_Distance_Conf "PA Line LM Distance Conf";
CM_ SG_ 727 PA_Line_LM_Distance "PA Line LM Distance";
CM_ SG_ 2654486529 CBV_bit0_RepeatMessageRequestBit_1E384001 "Repeat Message Request Bit";
CM_ SG_ 2654486529 CBV_bit3_NMCoordinatorBit_1E384001 "NM Coordinator Sleep Bit";
CM_ SG_ 2654486529 CBV_bit4_ActiveWakeupBit_1E384001 "Active Wakeup Bit";
CM_ SG_ 2654486529 CBV_bit6_PartialNtwInfBit_1E384001 "Partial Network Information Bit (PNI)";
CM_ SG_ 2654486529 SourceNodeIdentifier_1E384001 "Source Node Identifier";
CM_ SG_ 2654486552 CBV_bit0_RepeatMessageRequestBit_1E384018 "Repeat Message Request Bit";
CM_ SG_ 2654486552 CBV_bit3_NMCoordinatorBit_1E384018 "NM Coordinator Sleep Bit";
CM_ SG_ 2654486552 CBV_bit4_ActiveWakeupBit_1E384018 "Active Wakeup Bit";
CM_ SG_ 2654486552 CBV_bit6_PartialNtwInfBit_1E384018 "Partial Network Information Bit (PNI)";
CM_ SG_ 2654486552 SourceNodeIdentifier_1E384018 "Source Node Identifier";
CM_ SG_ 2654486530 CBV_bit0_RepeatMessageRequestBit_1E384002 "Repeat Message Request Bit";
CM_ SG_ 2654486530 CBV_bit3_NMCoordinatorBit_1E384002 "NM Coordinator Sleep Bit";
CM_ SG_ 2654486530 CBV_bit4_ActiveWakeupBit_1E384002 "Active Wakeup Bit";
CM_ SG_ 2654486530 CBV_bit6_PartialNtwInfBit_1E384002 "Partial Network Information Bit (PNI)";
CM_ SG_ 2654486530 SourceNodeIdentifier_1E384002 "Source Node Identifier";
CM_ SG_ 2654486669 CBV_bit0_RepeatMessageRequestBit_1E38408D "Repeat Message Request Bit";
CM_ SG_ 2654486669 CBV_bit3_NMCoordinatorBit_1E38408D "NM Coordinator Sleep Bit";
CM_ SG_ 2654486669 CBV_bit4_ActiveWakeupBit_1E38408D "Active Wakeup Bit";
CM_ SG_ 2654486669 CBV_bit6_PartialNtwInfBit_1E38408D "Partial Network Information Bit (PNI)";
CM_ SG_ 2654486669 SourceNodeIdentifier_1E38408D "Source Node Identifier";
CM_ SG_ 2654486676 CBV_bit0_RepeatMessageRequestBit_1E384094 "Repeat Message Request Bit";
CM_ SG_ 2654486676 CBV_bit3_NMCoordinatorBit_1E384094 "NM Coordinator Sleep Bit";
CM_ SG_ 2654486676 CBV_bit4_ActiveWakeupBit_1E384094 "Active Wakeup Bit";
CM_ SG_ 2654486676 CBV_bit6_PartialNtwInfBit_1E384094 "Partial Network Information Bit (PNI)";
CM_ SG_ 2654486676 SourceNodeIdentifier_1E384094 "Source Node Identifier";
CM_ SG_ 2654486534 CBV_bit0_RepeatMessageRequestBit_1E384006 "Repeat Message Request Bit";
CM_ SG_ 2654486534 CBV_bit3_NMCoordinatorBit_1E384006 "NM Coordinator Sleep Bit";
CM_ SG_ 2654486534 CBV_bit4_ActiveWakeupBit_1E384006 "Active Wakeup Bit";
CM_ SG_ 2654486534 CBV_bit6_PartialNtwInfBit_1E384006 "Partial Network Information Bit (PNI)";
CM_ SG_ 2654486534 SourceNodeIdentifier_1E384006 "Source Node Identifier";
BA_DEF_ SG_ "GenSigTimeoutTime_MPAD" INT 0 65535;
BA_DEF_ SG_ "GenSigTimeoutTime_ADCAM" INT 0 65535;
BA_DEF_ SG_ "GenSigTimeoutTime_CVADAS" INT 0 65535;
BA_DEF_ SG_ "GenSigStartValue" INT 0 2147483647;
BA_DEF_ SG_ "GenSigInactiveValue" INT 0 2147483647;
BA_DEF_ SG_ "GenSigSendType" ENUM "NotUsed","OnWrite","OnWriteWithRepetition","OnChange","OnChangeWithRepetition","IfActive","IfActiveWithRepetition","NoSigSendType";
BA_DEF_ SG_ "SystemSignalLongSymbol" STRING ;
BA_DEF_ SG_ "GenSigTimeoutTime_BSM" INT 0 65535;
BA_DEF_ SG_ "GenSigTimeoutTime_BSM2" INT 0 65535;
BA_DEF_ SG_ "GenSigTimeoutTime_CADM" INT 0 65535;
BA_DEF_ SG_ "GenSigTimeoutTime_CVPAM" INT 0 65535;
BA_DEF_ SG_ "GenSigTimeoutTime_ECM" INT 0 65535;
BA_DEF_ SG_ "GenSigTimeoutTime_EPS" INT 0 65535;
BA_DEF_ SG_ "GenSigTimeoutTime_EVCU2" INT 0 65535;
BA_DEF_ SG_ "GenSigTimeoutTime_ORC" INT 0 65535;
BA_DEF_ BO_ "DiagRequest" ENUM "No","Yes";
BA_DEF_ BO_ "Type" ENUM "P","C","PE","COC","PE_Cntrl","E","E_Cntrl","OC","S","BAF","DC","EM","MM","ISO-TP","-";
BA_DEF_ BO_ "DiagResponse" ENUM "No","Yes";
BA_DEF_ BO_ "NmMessage" ENUM "No","Yes";
BA_DEF_ BO_ "GenMsgSendType" ENUM "Cyclic","NotUsed","NotUsed","NotUsed","NotUsed","NotUsed","NotUsed","NotUsed","NoMsgSendType";
BA_DEF_ BO_ "GenMsgNrOfRepetition" INT 0 255;
BA_DEF_ BO_ "GenMsgILSupport" ENUM "No","Yes";
BA_DEF_ BO_ "GenMsgStartDelayTime" INT 0 65535;
BA_DEF_ BO_ "GenMsgCycleTimeFast" INT 0 65535;
BA_DEF_ BO_ "GenMsgCycleTime" INT 0 65535;
BA_DEF_ BO_ "GenMsgDelayTime" INT 0 65535;
BA_DEF_ BO_ "NmAsrMessage" ENUM "No","Yes";
BA_DEF_ BO_ "DiagState" ENUM "No","Yes";
BA_DEF_ BO_ "DiagConnection" HEX 0 65535;
BA_DEF_ BO_ "VFrameFormat" ENUM "StandardCAN","ExtendedCAN","reserved","reserved","reserved","reserved","reserved","reserved","reserved","reserved","reserved","reserved","reserved","reserved","StandardCAN_FD","ExtendedCAN_FD";
BA_DEF_ BO_ "CANFD_BRS" ENUM "0","1";
BA_DEF_DEF_ "GenSigTimeoutTime_MPAD" 2500;
BA_DEF_DEF_ "GenSigTimeoutTime_ADCAM" 2500;
BA_DEF_DEF_ "GenSigTimeoutTime_CVADAS" 2500;
BA_DEF_DEF_ "GenSigStartValue" 0;
BA_DEF_DEF_ "GenSigInactiveValue" 0;
BA_DEF_DEF_ "GenSigSendType" "NoSigSendType";
BA_DEF_DEF_ "SystemSignalLongSymbol" "";
BA_DEF_DEF_ "GenSigTimeoutTime_BSM" 2500;
BA_DEF_DEF_ "GenSigTimeoutTime_BSM2" 2500;
BA_DEF_DEF_ "GenSigTimeoutTime_CADM" 2500;
BA_DEF_DEF_ "GenSigTimeoutTime_CVPAM" 2500;
BA_DEF_DEF_ "GenSigTimeoutTime_ECM" 2500;
BA_DEF_DEF_ "GenSigTimeoutTime_EPS" 2500;
BA_DEF_DEF_ "GenSigTimeoutTime_EVCU2" 2500;
BA_DEF_DEF_ "GenSigTimeoutTime_ORC" 2500;
BA_DEF_DEF_ "DiagRequest" "No";
BA_DEF_DEF_ "Type" "-";
BA_DEF_DEF_ "DiagResponse" "No";
BA_DEF_DEF_ "NmMessage" "No";
BA_DEF_DEF_ "GenMsgSendType" "NoMsgSendType";
BA_DEF_DEF_ "GenMsgNrOfRepetition" 0;
BA_DEF_DEF_ "GenMsgILSupport" "No";
BA_DEF_DEF_ "GenMsgStartDelayTime" 0;
BA_DEF_DEF_ "GenMsgCycleTimeFast" 0;
BA_DEF_DEF_ "GenMsgCycleTime" 0;
BA_DEF_DEF_ "GenMsgDelayTime" 0;
BA_DEF_DEF_ "NmAsrMessage" "No";
BA_DEF_DEF_ "DiagState" "No";
BA_DEF_DEF_ "DiagConnection" 0;
BA_DEF_DEF_ "VFrameFormat" "StandardCAN_FD";
BA_DEF_DEF_ "CANFD_BRS" "0";
BA_ "CANFD_BRS" BO_ 727 1;
BA_ "Type" BO_ 2654486552 8;
BA_ "NmMessage" BO_ 2654486552 1;
BA_ "NmAsrMessage" BO_ 2654486552 1;
BA_ "VFrameFormat" BO_ 2654486552 15;
BA_ "CANFD_BRS" BO_ 2654486552 1;
BA_ "Type" BO_ 2654486530 8;
BA_ "NmMessage" BO_ 2654486530 1;
BA_ "NmAsrMessage" BO_ 2654486530 1;
BA_ "VFrameFormat" BO_ 2654486530 15;
BA_ "CANFD_BRS" BO_ 2654486530 1;
BA_ "Type" BO_ 1156 3;
BA_ "GenMsgSendType" BO_ 1156 0;
BA_ "GenMsgNrOfRepetition" BO_ 1156 2;
BA_ "GenMsgILSupport" BO_ 1156 1;
BA_ "GenMsgCycleTimeFast" BO_ 1156 20;
BA_ "GenMsgCycleTime" BO_ 1156 500;
BA_ "GenMsgDelayTime" BO_ 1156 20;
BA_ "CANFD_BRS" BO_ 1156 1;
BA_ "Type" BO_ 2654486676 8;
BA_ "NmMessage" BO_ 2654486676 1;
BA_ "NmAsrMessage" BO_ 2654486676 1;
BA_ "VFrameFormat" BO_ 2654486676 15;
BA_ "CANFD_BRS" BO_ 2654486676 1;
BA_ "Type" BO_ 257 1;
BA_ "GenMsgSendType" BO_ 257 0;
BA_ "GenMsgILSupport" BO_ 257 1;
BA_ "GenMsgCycleTime" BO_ 257 10;
BA_ "CANFD_BRS" BO_ 257 1;
BA_ "Type" BO_ 524 1;
BA_ "GenMsgSendType" BO_ 524 0;
BA_ "GenMsgILSupport" BO_ 524 1;
BA_ "GenMsgCycleTime" BO_ 524 20;
BA_ "CANFD_BRS" BO_ 524 1;
BA_ "Type" BO_ 2654486534 8;
BA_ "NmMessage" BO_ 2654486534 1;
BA_ "NmAsrMessage" BO_ 2654486534 1;
BA_ "VFrameFormat" BO_ 2654486534 15;
BA_ "CANFD_BRS" BO_ 2654486534 1;
BA_ "Type" BO_ 258 1;
BA_ "GenMsgSendType" BO_ 258 0;
BA_ "GenMsgILSupport" BO_ 258 1;
BA_ "GenMsgCycleTime" BO_ 258 10;
BA_ "CANFD_BRS" BO_ 258 1;
BA_ "Type" BO_ 262 1;
BA_ "GenMsgSendType" BO_ 262 0;
BA_ "GenMsgILSupport" BO_ 262 1;
BA_ "GenMsgCycleTime" BO_ 262 10;
BA_ "CANFD_BRS" BO_ 262 1;
BA_ "Type" BO_ 2654486529 8;
BA_ "NmMessage" BO_ 2654486529 1;
BA_ "NmAsrMessage" BO_ 2654486529 1;
BA_ "VFrameFormat" BO_ 2654486529 15;
BA_ "CANFD_BRS" BO_ 2654486529 1;
BA_ "Type" BO_ 280 1;
BA_ "GenMsgSendType" BO_ 280 0;
BA_ "GenMsgILSupport" BO_ 280 1;
BA_ "GenMsgCycleTime" BO_ 280 10;
BA_ "CANFD_BRS" BO_ 280 1;
BA_ "Type" BO_ 2654486669 8;
BA_ "NmMessage" BO_ 2654486669 1;
BA_ "NmAsrMessage" BO_ 2654486669 1;
BA_ "VFrameFormat" BO_ 2654486669 15;
BA_ "CANFD_BRS" BO_ 2654486669 1;
BA_ "Type" BO_ 726 1;
BA_ "GenMsgSendType" BO_ 726 0;
BA_ "GenMsgILSupport" BO_ 726 1;
BA_ "GenMsgCycleTime" BO_ 726 40;
BA_ "CANFD_BRS" BO_ 726 1;
BA_ "Type" BO_ 727 1;
BA_ "GenMsgSendType" BO_ 727 0;
BA_ "GenMsgILSupport" BO_ 727 1;
BA_ "GenMsgCycleTime" BO_ 727 40;
BA_ "GenSigTimeoutTime_MPAD" SG_ 2654486534 CBV_bit0_RepeatMessageRequestBit_1E384006 0;
BA_ "GenSigTimeoutTime_ADCAM" SG_ 2654486534 CBV_bit0_RepeatMessageRequestBit_1E384006 0;
BA_ "GenSigTimeoutTime_CVADAS" SG_ 2654486534 CBV_bit0_RepeatMessageRequestBit_1E384006 0;
BA_ "GenSigTimeoutTime_MPAD" SG_ 2654486534 CBV_bit1_1E384006 0;
BA_ "GenSigTimeoutTime_ADCAM" SG_ 2654486534 CBV_bit1_1E384006 0;
BA_ "GenSigTimeoutTime_CVADAS" SG_ 2654486534 CBV_bit1_1E384006 0;
BA_ "GenSigTimeoutTime_MPAD" SG_ 2654486534 CBV_bit2_1E384006 0;
BA_ "GenSigTimeoutTime_ADCAM" SG_ 2654486534 CBV_bit2_1E384006 0;
BA_ "GenSigTimeoutTime_CVADAS" SG_ 2654486534 CBV_bit2_1E384006 0;
BA_ "GenSigTimeoutTime_MPAD" SG_ 2654486534 CBV_bit3_NMCoordinatorBit_1E384006 0;
BA_ "GenSigTimeoutTime_ADCAM" SG_ 2654486534 CBV_bit3_NMCoordinatorBit_1E384006 0;
BA_ "GenSigTimeoutTime_CVADAS" SG_ 2654486534 CBV_bit3_NMCoordinatorBit_1E384006 0;
BA_ "GenSigTimeoutTime_MPAD" SG_ 2654486534 CBV_bit4_ActiveWakeupBit_1E384006 0;
BA_ "GenSigTimeoutTime_ADCAM" SG_ 2654486534 CBV_bit4_ActiveWakeupBit_1E384006 0;
BA_ "GenSigTimeoutTime_CVADAS" SG_ 2654486534 CBV_bit4_ActiveWakeupBit_1E384006 0;
BA_ "GenSigTimeoutTime_MPAD" SG_ 2654486534 CBV_bit5_1E384006 0;
BA_ "GenSigTimeoutTime_ADCAM" SG_ 2654486534 CBV_bit5_1E384006 0;
BA_ "GenSigTimeoutTime_CVADAS" SG_ 2654486534 CBV_bit5_1E384006 0;
BA_ "GenSigTimeoutTime_MPAD" SG_ 2654486534 CBV_bit6_PartialNtwInfBit_1E384006 0;
BA_ "GenSigTimeoutTime_ADCAM" SG_ 2654486534 CBV_bit6_PartialNtwInfBit_1E384006 0;
BA_ "GenSigTimeoutTime_CVADAS" SG_ 2654486534 CBV_bit6_PartialNtwInfBit_1E384006 0;
BA_ "GenSigTimeoutTime_MPAD" SG_ 2654486534 CBV_bit7_1E384006 0;
BA_ "GenSigTimeoutTime_ADCAM" SG_ 2654486534 CBV_bit7_1E384006 0;
BA_ "GenSigTimeoutTime_CVADAS" SG_ 2654486534 CBV_bit7_1E384006 0;
BA_ "GenSigTimeoutTime_MPAD" SG_ 2654486534 SourceNodeIdentifier_1E384006 0;
BA_ "GenSigTimeoutTime_ADCAM" SG_ 2654486534 SourceNodeIdentifier_1E384006 0;
BA_ "GenSigTimeoutTime_CVADAS" SG_ 2654486534 SourceNodeIdentifier_1E384006 0;
BA_ "GenSigTimeoutTime_BSM" SG_ 2654486534 CBV_bit0_RepeatMessageRequestBit_1E384006 0;
BA_ "GenSigTimeoutTime_BSM2" SG_ 2654486534 CBV_bit0_RepeatMessageRequestBit_1E384006 0;
BA_ "GenSigTimeoutTime_CADM" SG_ 2654486534 CBV_bit0_RepeatMessageRequestBit_1E384006 0;
BA_ "GenSigTimeoutTime_CVPAM" SG_ 2654486534 CBV_bit0_RepeatMessageRequestBit_1E384006 0;
BA_ "GenSigTimeoutTime_ECM" SG_ 2654486534 CBV_bit0_RepeatMessageRequestBit_1E384006 0;
BA_ "GenSigTimeoutTime_EPS" SG_ 2654486534 CBV_bit0_RepeatMessageRequestBit_1E384006 0;
BA_ "GenSigTimeoutTime_EVCU2" SG_ 2654486534 CBV_bit0_RepeatMessageRequestBit_1E384006 0;
BA_ "GenSigTimeoutTime_ORC" SG_ 2654486534 CBV_bit0_RepeatMessageRequestBit_1E384006 0;
BA_ "GenSigTimeoutTime_BSM" SG_ 2654486534 CBV_bit1_1E384006 0;
BA_ "GenSigTimeoutTime_BSM2" SG_ 2654486534 CBV_bit1_1E384006 0;
BA_ "GenSigTimeoutTime_CADM" SG_ 2654486534 CBV_bit1_1E384006 0;
BA_ "GenSigTimeoutTime_CVPAM" SG_ 2654486534 CBV_bit1_1E384006 0;
BA_ "GenSigTimeoutTime_ECM" SG_ 2654486534 CBV_bit1_1E384006 0;
BA_ "GenSigTimeoutTime_EPS" SG_ 2654486534 CBV_bit1_1E384006 0;
BA_ "GenSigTimeoutTime_EVCU2" SG_ 2654486534 CBV_bit1_1E384006 0;
BA_ "GenSigTimeoutTime_ORC" SG_ 2654486534 CBV_bit1_1E384006 0;
BA_ "GenSigTimeoutTime_BSM" SG_ 2654486534 CBV_bit2_1E384006 0;
BA_ "GenSigTimeoutTime_BSM2" SG_ 2654486534 CBV_bit2_1E384006 0;
BA_ "GenSigTimeoutTime_CADM" SG_ 2654486534 CBV_bit2_1E384006 0;
BA_ "GenSigTimeoutTime_CVPAM" SG_ 2654486534 CBV_bit2_1E384006 0;
BA_ "GenSigTimeoutTime_ECM" SG_ 2654486534 CBV_bit2_1E384006 0;
BA_ "GenSigTimeoutTime_EPS" SG_ 2654486534 CBV_bit2_1E384006 0;
BA_ "GenSigTimeoutTime_EVCU2" SG_ 2654486534 CBV_bit2_1E384006 0;
BA_ "GenSigTimeoutTime_ORC" SG_ 2654486534 CBV_bit2_1E384006 0;
BA_ "GenSigTimeoutTime_BSM" SG_ 2654486534 CBV_bit3_NMCoordinatorBit_1E384006 0;
BA_ "GenSigTimeoutTime_BSM2" SG_ 2654486534 CBV_bit3_NMCoordinatorBit_1E384006 0;
BA_ "GenSigTimeoutTime_CADM" SG_ 2654486534 CBV_bit3_NMCoordinatorBit_1E384006 0;
BA_ "GenSigTimeoutTime_CVPAM" SG_ 2654486534 CBV_bit3_NMCoordinatorBit_1E384006 0;
BA_ "GenSigTimeoutTime_ECM" SG_ 2654486534 CBV_bit3_NMCoordinatorBit_1E384006 0;
BA_ "GenSigTimeoutTime_EPS" SG_ 2654486534 CBV_bit3_NMCoordinatorBit_1E384006 0;
BA_ "GenSigTimeoutTime_EVCU2" SG_ 2654486534 CBV_bit3_NMCoordinatorBit_1E384006 0;
BA_ "GenSigTimeoutTime_ORC" SG_ 2654486534 CBV_bit3_NMCoordinatorBit_1E384006 0;
BA_ "GenSigTimeoutTime_BSM" SG_ 2654486534 CBV_bit4_ActiveWakeupBit_1E384006 0;
BA_ "GenSigTimeoutTime_BSM2" SG_ 2654486534 CBV_bit4_ActiveWakeupBit_1E384006 0;
BA_ "GenSigTimeoutTime_CADM" SG_ 2654486534 CBV_bit4_ActiveWakeupBit_1E384006 0;
BA_ "GenSigTimeoutTime_CVPAM" SG_ 2654486534 CBV_bit4_ActiveWakeupBit_1E384006 0;
BA_ "GenSigTimeoutTime_ECM" SG_ 2654486534 CBV_bit4_ActiveWakeupBit_1E384006 0;
BA_ "GenSigTimeoutTime_EPS" SG_ 2654486534 CBV_bit4_ActiveWakeupBit_1E384006 0;
BA_ "GenSigTimeoutTime_EVCU2" SG_ 2654486534 CBV_bit4_ActiveWakeupBit_1E384006 0;
BA_ "GenSigTimeoutTime_ORC" SG_ 2654486534 CBV_bit4_ActiveWakeupBit_1E384006 0;
BA_ "GenSigTimeoutTime_BSM" SG_ 2654486534 CBV_bit5_1E384006 0;
BA_ "GenSigTimeoutTime_BSM2" SG_ 2654486534 CBV_bit5_1E384006 0;
BA_ "GenSigTimeoutTime_CADM" SG_ 2654486534 CBV_bit5_1E384006 0;
BA_ "GenSigTimeoutTime_CVPAM" SG_ 2654486534 CBV_bit5_1E384006 0;
BA_ "GenSigTimeoutTime_ECM" SG_ 2654486534 CBV_bit5_1E384006 0;
BA_ "GenSigTimeoutTime_EPS" SG_ 2654486534 CBV_bit5_1E384006 0;
BA_ "GenSigTimeoutTime_EVCU2" SG_ 2654486534 CBV_bit5_1E384006 0;
BA_ "GenSigTimeoutTime_ORC" SG_ 2654486534 CBV_bit5_1E384006 0;
BA_ "GenSigTimeoutTime_BSM" SG_ 2654486534 CBV_bit6_PartialNtwInfBit_1E384006 0;
BA_ "GenSigTimeoutTime_BSM2" SG_ 2654486534 CBV_bit6_PartialNtwInfBit_1E384006 0;
BA_ "GenSigTimeoutTime_CADM" SG_ 2654486534 CBV_bit6_PartialNtwInfBit_1E384006 0;
BA_ "GenSigTimeoutTime_CVPAM" SG_ 2654486534 CBV_bit6_PartialNtwInfBit_1E384006 0;
BA_ "GenSigTimeoutTime_ECM" SG_ 2654486534 CBV_bit6_PartialNtwInfBit_1E384006 0;
BA_ "GenSigTimeoutTime_EPS" SG_ 2654486534 CBV_bit6_PartialNtwInfBit_1E384006 0;
BA_ "GenSigTimeoutTime_EVCU2" SG_ 2654486534 CBV_bit6_PartialNtwInfBit_1E384006 0;
BA_ "GenSigTimeoutTime_ORC" SG_ 2654486534 CBV_bit6_PartialNtwInfBit_1E384006 0;
BA_ "GenSigTimeoutTime_BSM" SG_ 2654486534 CBV_bit7_1E384006 0;
BA_ "GenSigTimeoutTime_BSM2" SG_ 2654486534 CBV_bit7_1E384006 0;
BA_ "GenSigTimeoutTime_CADM" SG_ 2654486534 CBV_bit7_1E384006 0;
BA_ "GenSigTimeoutTime_CVPAM" SG_ 2654486534 CBV_bit7_1E384006 0;
BA_ "GenSigTimeoutTime_ECM" SG_ 2654486534 CBV_bit7_1E384006 0;
BA_ "GenSigTimeoutTime_EPS" SG_ 2654486534 CBV_bit7_1E384006 0;
BA_ "GenSigTimeoutTime_EVCU2" SG_ 2654486534 CBV_bit7_1E384006 0;
BA_ "GenSigTimeoutTime_ORC" SG_ 2654486534 CBV_bit7_1E384006 0;
BA_ "GenSigTimeoutTime_BSM" SG_ 2654486534 SourceNodeIdentifier_1E384006 0;
BA_ "GenSigTimeoutTime_BSM2" SG_ 2654486534 SourceNodeIdentifier_1E384006 0;
BA_ "GenSigTimeoutTime_CADM" SG_ 2654486534 SourceNodeIdentifier_1E384006 0;
BA_ "GenSigTimeoutTime_CVPAM" SG_ 2654486534 SourceNodeIdentifier_1E384006 0;
BA_ "GenSigTimeoutTime_ECM" SG_ 2654486534 SourceNodeIdentifier_1E384006 0;
BA_ "GenSigTimeoutTime_EPS" SG_ 2654486534 SourceNodeIdentifier_1E384006 0;
BA_ "GenSigTimeoutTime_EVCU2" SG_ 2654486534 SourceNodeIdentifier_1E384006 0;
BA_ "GenSigTimeoutTime_ORC" SG_ 2654486534 SourceNodeIdentifier_1E384006 0;
BA_ "GenSigTimeoutTime_CVADAS" SG_ 258 BSM_ESASystemSts 0;
BA_ "GenSigTimeoutTime_BSM" SG_ 258 BSM_ESASystemSts 0;
BA_ "GenSigTimeoutTime_BSM2" SG_ 258 BSM_ESASystemSts 0;
BA_ "GenSigTimeoutTime_ECM" SG_ 258 BSM_ESASystemSts 0;
BA_ "GenSigTimeoutTime_EVCU2" SG_ 258 BSM_ESASystemSts 0;
BA_ "GenSigTimeoutTime_ORC" SG_ 258 BSM_ESASystemSts 0;
BA_ "GenSigTimeoutTime_MPAD" SG_ 258 MessageCounter_BRAKE2 0;
BA_ "GenSigTimeoutTime_CVADAS" SG_ 258 MessageCounter_BRAKE2 0;
BA_ "GenSigTimeoutTime_ECM" SG_ 258 MessageCounter_BRAKE2 0;
BA_ "GenSigTimeoutTime_CVADAS" SG_ 258 PrefillActive 0;
BA_ "GenSigTimeoutTime_MPAD" SG_ 258 Slope 0;
BA_ "GenSigTimeoutTime_ADCAM" SG_ 258 Slope 0;
BA_ "GenSigTimeoutTime_CVADAS" SG_ 258 Slope 0;
BA_ "GenSigTimeoutTime_MPAD" SG_ 258 BrakePedalPressure 0;
BA_ "GenSigTimeoutTime_ADCAM" SG_ 258 BrakePedalPressure 0;
BA_ "GenSigTimeoutTime_CVADAS" SG_ 258 BrakePedalPressure 0;
BA_ "GenSigTimeoutTime_MPAD" SG_ 258 CRC_BRAKE2 0;
BA_ "GenSigTimeoutTime_CVADAS" SG_ 258 CRC_BRAKE2 0;
BA_ "GenSigTimeoutTime_ECM" SG_ 258 CRC_BRAKE2 0;
BA_ "GenSigTimeoutTime_ADCAM" SG_ 258 ESCActive 0;
BA_ "GenSigTimeoutTime_CVADAS" SG_ 258 ESCActive 0;
BA_ "GenSigTimeoutTime_MPAD" SG_ 258 ESP_Sys_Stat 0;
BA_ "GenSigTimeoutTime_ADCAM" SG_ 258 ESP_Sys_Stat 0;
BA_ "GenSigTimeoutTime_CVADAS" SG_ 258 ESP_Sys_Stat 0;
BA_ "GenSigTimeoutTime_CVADAS" SG_ 258 InternalError_BSM 0;
BA_ "GenSigTimeoutTime_MPAD" SG_ 258 WheelRPM_FR 0;
BA_ "GenSigTimeoutTime_ADCAM" SG_ 258 WheelRPM_FR 0;
BA_ "GenSigTimeoutTime_CVADAS" SG_ 258 WheelRPM_FR 0;
BA_ "GenSigTimeoutTime_ADCAM" SG_ 258 ABSActive 0;
BA_ "GenSigTimeoutTime_CVADAS" SG_ 258 ABSActive 0;
BA_ "GenSigTimeoutTime_CVADAS" SG_ 258 Brake_MaxRegen_Ready 0;
BA_ "GenSigTimeoutTime_MPAD" SG_ 258 BrakeBoostPressure 0;
BA_ "GenSigTimeoutTime_ADCAM" SG_ 258 BrakeBoostPressure 0;
BA_ "GenSigTimeoutTime_CVADAS" SG_ 258 BrakeBoostPressure 0;
BA_ "GenSigTimeoutTime_MPAD" SG_ 258 BrakeBoostStat 0;
BA_ "GenSigTimeoutTime_ADCAM" SG_ 258 BrakeBoostStat 0;
BA_ "GenSigTimeoutTime_CVADAS" SG_ 258 BrakeBoostStat 0;
BA_ "GenSigTimeoutTime_CVADAS" SG_ 258 BrakeInterventionSts 0;
BA_ "GenSigTimeoutTime_MPAD" SG_ 258 ParkingInterventionSts 0;
BA_ "GenSigTimeoutTime_ADCAM" SG_ 258 ParkingInterventionSts 0;
BA_ "GenSigTimeoutTime_MPAD" SG_ 258 ParkingGearShiftReq_BSM 0;
BA_ "GenSigTimeoutTime_ADCAM" SG_ 258 ParkingGearShiftReq_BSM 0;
BA_ "GenSigTimeoutTime_CVADAS" SG_ 258 Brk_Stat 0;
BA_ "GenSigTimeoutTime_MPAD" SG_ 258 WheelRPM_FL 0;
BA_ "GenSigTimeoutTime_ADCAM" SG_ 258 WheelRPM_FL 0;
BA_ "GenSigTimeoutTime_CVADAS" SG_ 258 WheelRPM_FL 0;
BA_ "GenSigTimeoutTime_ECM" SG_ 258 VehicleSpeedVSOSig 0;
BA_ "GenSigTimeoutTime_BSM" SG_ 258 LatAccelerationFailSts_BSM 0;
BA_ "GenSigTimeoutTime_BSM2" SG_ 258 LatAccelerationFailSts_BSM 0;
BA_ "GenSigTimeoutTime_ECM" SG_ 258 LatAccelerationFailSts_BSM 0;
BA_ "GenSigTimeoutTime_EPS" SG_ 258 LatAccelerationFailSts_BSM 0;
BA_ "GenSigTimeoutTime_EVCU2" SG_ 258 LatAccelerationFailSts_BSM 0;
BA_ "GenSigTimeoutTime_ORC" SG_ 258 LatAccelerationFailSts_BSM 0;
BA_ "GenSigStartValue" SG_ 258 LongAcceleration_BSM 4095;
BA_ "GenSigTimeoutTime_BSM" SG_ 258 LongAcceleration_BSM 0;
BA_ "GenSigTimeoutTime_BSM2" SG_ 258 LongAcceleration_BSM 0;
BA_ "GenSigTimeoutTime_ECM" SG_ 258 LongAcceleration_BSM 0;
BA_ "GenSigTimeoutTime_EVCU2" SG_ 258 LongAcceleration_BSM 0;
BA_ "GenSigTimeoutTime_ORC" SG_ 258 LongAcceleration_BSM 0;
BA_ "GenSigTimeoutTime_BSM" SG_ 258 LongAccelerationFailSts_BSM 0;
BA_ "GenSigTimeoutTime_BSM2" SG_ 258 LongAccelerationFailSts_BSM 0;
BA_ "GenSigTimeoutTime_ECM" SG_ 258 LongAccelerationFailSts_BSM 0;
BA_ "GenSigTimeoutTime_EPS" SG_ 258 LongAccelerationFailSts_BSM 0;
BA_ "GenSigTimeoutTime_EVCU2" SG_ 258 LongAccelerationFailSts_BSM 0;
BA_ "GenSigTimeoutTime_ORC" SG_ 258 LongAccelerationFailSts_BSM 0;
BA_ "GenSigTimeoutTime_BSM" SG_ 258 MessageCounter_BRAKE2 0;
BA_ "GenSigTimeoutTime_ORC" SG_ 258 MessageCounter_BRAKE2 0;
BA_ "GenSigTimeoutTime_BSM" SG_ 258 PrefillActive 0;
BA_ "GenSigTimeoutTime_BSM2" SG_ 258 PrefillActive 0;
BA_ "GenSigTimeoutTime_CVPAM" SG_ 258 PrefillActive 0;
BA_ "GenSigTimeoutTime_ECM" SG_ 258 PrefillActive 0;
BA_ "GenSigTimeoutTime_EPS" SG_ 258 PrefillActive 0;
BA_ "GenSigTimeoutTime_EVCU2" SG_ 258 PrefillActive 0;
BA_ "GenSigTimeoutTime_ORC" SG_ 258 PrefillActive 0;
BA_ "GenSigTimeoutTime_BSM" SG_ 258 Slope 0;
BA_ "GenSigTimeoutTime_BSM2" SG_ 258 Slope 0;
BA_ "GenSigTimeoutTime_CADM" SG_ 258 Slope 0;
BA_ "GenSigTimeoutTime_ECM" SG_ 258 Slope 0;
BA_ "GenSigTimeoutTime_EPS" SG_ 258 Slope 0;
BA_ "GenSigTimeoutTime_EVCU2" SG_ 258 Slope 0;
BA_ "GenSigTimeoutTime_ORC" SG_ 258 Slope 0;
BA_ "GenSigStartValue" SG_ 258 BrakePedalPressure 2047;
BA_ "GenSigTimeoutTime_BSM" SG_ 258 BrakePedalPressure 0;
BA_ "GenSigTimeoutTime_BSM2" SG_ 258 BrakePedalPressure 0;
BA_ "GenSigTimeoutTime_CADM" SG_ 258 BrakePedalPressure 0;
BA_ "GenSigTimeoutTime_CVPAM" SG_ 258 BrakePedalPressure 0;
BA_ "GenSigTimeoutTime_ECM" SG_ 258 BrakePedalPressure 0;
BA_ "GenSigTimeoutTime_EPS" SG_ 258 BrakePedalPressure 0;
BA_ "GenSigTimeoutTime_ORC" SG_ 258 BrakePedalPressure 0;
BA_ "GenSigTimeoutTime_BSM" SG_ 258 CRC_BRAKE2 0;
BA_ "GenSigTimeoutTime_ORC" SG_ 258 CRC_BRAKE2 0;
BA_ "GenSigTimeoutTime_BSM" SG_ 258 ESCActive 0;
BA_ "GenSigTimeoutTime_BSM2" SG_ 258 ESCActive 0;
BA_ "GenSigTimeoutTime_ECM" SG_ 258 ESCActive 0;
BA_ "GenSigTimeoutTime_EPS" SG_ 258 ESCActive 0;
BA_ "GenSigTimeoutTime_ORC" SG_ 258 ESCActive 0;
BA_ "GenSigStartValue" SG_ 258 ESP_Sys_Stat 1;
BA_ "GenSigTimeoutTime_BSM" SG_ 258 ESP_Sys_Stat 0;
BA_ "GenSigTimeoutTime_BSM2" SG_ 258 ESP_Sys_Stat 0;
BA_ "GenSigTimeoutTime_CADM" SG_ 258 ESP_Sys_Stat 0;
BA_ "GenSigTimeoutTime_CVPAM" SG_ 258 ESP_Sys_Stat 0;
BA_ "GenSigTimeoutTime_ECM" SG_ 258 ESP_Sys_Stat 0;
BA_ "GenSigTimeoutTime_EPS" SG_ 258 ESP_Sys_Stat 0;
BA_ "GenSigTimeoutTime_EVCU2" SG_ 258 ESP_Sys_Stat 0;
BA_ "GenSigTimeoutTime_ORC" SG_ 258 ESP_Sys_Stat 0;
BA_ "GenSigTimeoutTime_BSM" SG_ 258 InternalError_BSM 0;
BA_ "GenSigTimeoutTime_BSM2" SG_ 258 InternalError_BSM 0;
BA_ "GenSigTimeoutTime_CVPAM" SG_ 258 InternalError_BSM 0;
BA_ "GenSigTimeoutTime_ECM" SG_ 258 InternalError_BSM 0;
BA_ "GenSigTimeoutTime_EPS" SG_ 258 InternalError_BSM 0;
BA_ "GenSigTimeoutTime_EVCU2" SG_ 258 InternalError_BSM 0;
BA_ "GenSigTimeoutTime_ORC" SG_ 258 InternalError_BSM 0;
BA_ "GenSigStartValue" SG_ 258 LatAcceleration_BSM 4095;
BA_ "GenSigTimeoutTime_BSM" SG_ 258 LatAcceleration_BSM 0;
BA_ "GenSigTimeoutTime_BSM2" SG_ 258 LatAcceleration_BSM 0;
BA_ "GenSigTimeoutTime_ECM" SG_ 258 LatAcceleration_BSM 0;
BA_ "GenSigTimeoutTime_EVCU2" SG_ 258 LatAcceleration_BSM 0;
BA_ "GenSigTimeoutTime_ORC" SG_ 258 LatAcceleration_BSM 0;
BA_ "GenSigStartValue" SG_ 258 WheelRPM_FR 65535;
BA_ "GenSigTimeoutTime_BSM" SG_ 258 WheelRPM_FR 0;
BA_ "GenSigTimeoutTime_BSM2" SG_ 258 WheelRPM_FR 0;
BA_ "GenSigTimeoutTime_CADM" SG_ 258 WheelRPM_FR 0;
BA_ "GenSigTimeoutTime_CVPAM" SG_ 258 WheelRPM_FR 0;
BA_ "GenSigTimeoutTime_ECM" SG_ 258 WheelRPM_FR 0;
BA_ "GenSigTimeoutTime_EVCU2" SG_ 258 WheelRPM_FR 0;
BA_ "GenSigTimeoutTime_ORC" SG_ 258 WheelRPM_FR 0;
BA_ "GenSigTimeoutTime_BSM" SG_ 258 ABSActive 0;
BA_ "GenSigTimeoutTime_BSM2" SG_ 258 ABSActive 0;
BA_ "GenSigTimeoutTime_ECM" SG_ 258 ABSActive 0;
BA_ "GenSigTimeoutTime_EPS" SG_ 258 ABSActive 0;
BA_ "GenSigTimeoutTime_ORC" SG_ 258 ABSActive 0;
BA_ "GenSigTimeoutTime_BSM" SG_ 258 Brake_MaxRegen_Ready 0;
BA_ "GenSigTimeoutTime_BSM2" SG_ 258 Brake_MaxRegen_Ready 0;
BA_ "GenSigTimeoutTime_CADM" SG_ 258 Brake_MaxRegen_Ready 0;
BA_ "GenSigTimeoutTime_CVPAM" SG_ 258 Brake_MaxRegen_Ready 0;
BA_ "GenSigTimeoutTime_ECM" SG_ 258 Brake_MaxRegen_Ready 0;
BA_ "GenSigTimeoutTime_EPS" SG_ 258 Brake_MaxRegen_Ready 0;
BA_ "GenSigTimeoutTime_ORC" SG_ 258 Brake_MaxRegen_Ready 0;
BA_ "GenSigStartValue" SG_ 258 BrakeBoostPressure 2047;
BA_ "GenSigTimeoutTime_BSM" SG_ 258 BrakeBoostPressure 0;
BA_ "GenSigTimeoutTime_BSM2" SG_ 258 BrakeBoostPressure 0;
BA_ "GenSigTimeoutTime_CADM" SG_ 258 BrakeBoostPressure 0;
BA_ "GenSigTimeoutTime_CVPAM" SG_ 258 BrakeBoostPressure 0;
BA_ "GenSigTimeoutTime_ECM" SG_ 258 BrakeBoostPressure 0;
BA_ "GenSigTimeoutTime_EPS" SG_ 258 BrakeBoostPressure 0;
BA_ "GenSigTimeoutTime_ORC" SG_ 258 BrakeBoostPressure 0;
BA_ "GenSigTimeoutTime_BSM" SG_ 258 BrakeBoostStat 0;
BA_ "GenSigTimeoutTime_BSM2" SG_ 258 BrakeBoostStat 0;
BA_ "GenSigTimeoutTime_CADM" SG_ 258 BrakeBoostStat 0;
BA_ "GenSigTimeoutTime_CVPAM" SG_ 258 BrakeBoostStat 0;
BA_ "GenSigTimeoutTime_ECM" SG_ 258 BrakeBoostStat 0;
BA_ "GenSigTimeoutTime_EPS" SG_ 258 BrakeBoostStat 0;
BA_ "GenSigTimeoutTime_EVCU2" SG_ 258 BrakeBoostStat 0;
BA_ "GenSigTimeoutTime_ORC" SG_ 258 BrakeBoostStat 0;
BA_ "GenSigTimeoutTime_BSM" SG_ 258 BrakeInterventionSts 0;
BA_ "GenSigTimeoutTime_CVPAM" SG_ 258 BrakeInterventionSts 0;
BA_ "GenSigTimeoutTime_ECM" SG_ 258 BrakeInterventionSts 0;
BA_ "GenSigTimeoutTime_EPS" SG_ 258 BrakeInterventionSts 0;
BA_ "GenSigTimeoutTime_EVCU2" SG_ 258 BrakeInterventionSts 0;
BA_ "GenSigTimeoutTime_ORC" SG_ 258 BrakeInterventionSts 0;
BA_ "GenSigTimeoutTime_BSM" SG_ 258 ParkingInterventionSts 0;
BA_ "GenSigTimeoutTime_BSM2" SG_ 258 ParkingInterventionSts 0;
BA_ "GenSigTimeoutTime_CADM" SG_ 258 ParkingInterventionSts 0;
BA_ "GenSigTimeoutTime_ECM" SG_ 258 ParkingInterventionSts 0;
BA_ "GenSigTimeoutTime_EPS" SG_ 258 ParkingInterventionSts 0;
BA_ "GenSigTimeoutTime_EVCU2" SG_ 258 ParkingInterventionSts 0;
BA_ "GenSigTimeoutTime_ORC" SG_ 258 ParkingInterventionSts 0;
BA_ "GenSigTimeoutTime_BSM" SG_ 258 ParkingGearShiftReq_BSM 0;
BA_ "GenSigTimeoutTime_BSM2" SG_ 258 ParkingGearShiftReq_BSM 0;
BA_ "GenSigTimeoutTime_CADM" SG_ 258 ParkingGearShiftReq_BSM 0;
BA_ "GenSigTimeoutTime_ECM" SG_ 258 ParkingGearShiftReq_BSM 0;
BA_ "GenSigTimeoutTime_EPS" SG_ 258 ParkingGearShiftReq_BSM 0;
BA_ "GenSigTimeoutTime_EVCU2" SG_ 258 ParkingGearShiftReq_BSM 0;
BA_ "GenSigTimeoutTime_ORC" SG_ 258 ParkingGearShiftReq_BSM 0;
BA_ "GenSigTimeoutTime_BSM" SG_ 258 PPPA_Engine_Torque_Enabled_BSM 0;
BA_ "GenSigTimeoutTime_BSM2" SG_ 258 PPPA_Engine_Torque_Enabled_BSM 0;
BA_ "GenSigTimeoutTime_CADM" SG_ 258 PPPA_Engine_Torque_Enabled_BSM 0;
BA_ "GenSigTimeoutTime_CVPAM" SG_ 258 PPPA_Engine_Torque_Enabled_BSM 0;
BA_ "GenSigTimeoutTime_ECM" SG_ 258 PPPA_Engine_Torque_Enabled_BSM 0;
BA_ "GenSigTimeoutTime_EPS" SG_ 258 PPPA_Engine_Torque_Enabled_BSM 0;
BA_ "GenSigTimeoutTime_EVCU2" SG_ 258 PPPA_Engine_Torque_Enabled_BSM 0;
BA_ "GenSigTimeoutTime_ORC" SG_ 258 PPPA_Engine_Torque_Enabled_BSM 0;
BA_ "GenSigTimeoutTime_BSM" SG_ 258 Brk_Stat 0;
BA_ "GenSigTimeoutTime_BSM2" SG_ 258 Brk_Stat 0;
BA_ "GenSigTimeoutTime_EPS" SG_ 258 Brk_Stat 0;
BA_ "GenSigTimeoutTime_ORC" SG_ 258 Brk_Stat 0;
BA_ "GenSigStartValue" SG_ 258 WheelRPM_FL 65535;
BA_ "GenSigTimeoutTime_BSM" SG_ 258 WheelRPM_FL 0;
BA_ "GenSigTimeoutTime_BSM2" SG_ 258 WheelRPM_FL 0;
BA_ "GenSigTimeoutTime_CADM" SG_ 258 WheelRPM_FL 0;
BA_ "GenSigTimeoutTime_CVPAM" SG_ 258 WheelRPM_FL 0;
BA_ "GenSigTimeoutTime_ECM" SG_ 258 WheelRPM_FL 0;
BA_ "GenSigTimeoutTime_EVCU2" SG_ 258 WheelRPM_FL 0;
BA_ "GenSigTimeoutTime_ORC" SG_ 258 WheelRPM_FL 0;
BA_ "GenSigTimeoutTime_BSM" SG_ 258 TorqueIncrease 0;
BA_ "GenSigTimeoutTime_BSM2" SG_ 258 TorqueIncrease 0;
BA_ "GenSigTimeoutTime_CADM" SG_ 258 TorqueIncrease 0;
BA_ "GenSigTimeoutTime_CVPAM" SG_ 258 TorqueIncrease 0;
BA_ "GenSigTimeoutTime_ECM" SG_ 258 TorqueIncrease 0;
BA_ "GenSigTimeoutTime_EPS" SG_ 258 TorqueIncrease 0;
BA_ "GenSigTimeoutTime_EVCU2" SG_ 258 TorqueIncrease 0;
BA_ "GenSigTimeoutTime_ORC" SG_ 258 TorqueIncrease 0;
BA_ "GenSigTimeoutTime_BSM" SG_ 258 TorqueReduct 0;
BA_ "GenSigTimeoutTime_BSM2" SG_ 258 TorqueReduct 0;
BA_ "GenSigTimeoutTime_CADM" SG_ 258 TorqueReduct 0;
BA_ "GenSigTimeoutTime_CVPAM" SG_ 258 TorqueReduct 0;
BA_ "GenSigTimeoutTime_ECM" SG_ 258 TorqueReduct 0;
BA_ "GenSigTimeoutTime_EPS" SG_ 258 TorqueReduct 0;
BA_ "GenSigTimeoutTime_EVCU2" SG_ 258 TorqueReduct 0;
BA_ "GenSigTimeoutTime_ORC" SG_ 258 TorqueReduct 0;
BA_ "GenSigStartValue" SG_ 258 TorqueRequest 2047;
BA_ "GenSigTimeoutTime_BSM" SG_ 258 TorqueRequest 0;
BA_ "GenSigTimeoutTime_BSM2" SG_ 258 TorqueRequest 0;
BA_ "GenSigTimeoutTime_CADM" SG_ 258 TorqueRequest 0;
BA_ "GenSigTimeoutTime_CVPAM" SG_ 258 TorqueRequest 0;
BA_ "GenSigTimeoutTime_ECM" SG_ 258 TorqueRequest 0;
BA_ "GenSigTimeoutTime_EPS" SG_ 258 TorqueRequest 0;
BA_ "GenSigTimeoutTime_EVCU2" SG_ 258 TorqueRequest 0;
BA_ "GenSigTimeoutTime_ORC" SG_ 258 TorqueRequest 0;
BA_ "GenSigTimeoutTime_BSM" SG_ 258 VehicleSpeedVSOSig 0;
BA_ "GenSigTimeoutTime_ORC" SG_ 258 VehicleSpeedVSOSig 0;
BA_ "GenSigStartValue" SG_ 258 YawRate_BSM 4095;
BA_ "GenSigTimeoutTime_BSM" SG_ 258 YawRate_BSM 0;
BA_ "GenSigTimeoutTime_BSM2" SG_ 258 YawRate_BSM 0;
BA_ "GenSigTimeoutTime_ECM" SG_ 258 YawRate_BSM 0;
BA_ "GenSigTimeoutTime_EVCU2" SG_ 258 YawRate_BSM 0;
BA_ "GenSigTimeoutTime_ORC" SG_ 258 YawRate_BSM 0;
BA_ "GenSigTimeoutTime_BSM" SG_ 258 YawRateFailSts_BSM 0;
BA_ "GenSigTimeoutTime_BSM2" SG_ 258 YawRateFailSts_BSM 0;
BA_ "GenSigTimeoutTime_ECM" SG_ 258 YawRateFailSts_BSM 0;
BA_ "GenSigTimeoutTime_EVCU2" SG_ 258 YawRateFailSts_BSM 0;
BA_ "GenSigTimeoutTime_ORC" SG_ 258 YawRateFailSts_BSM 0;
BA_ "GenSigTimeoutTime_CVADAS" SG_ 262 CRC_ENGINE2 0;
BA_ "GenSigTimeoutTime_BSM" SG_ 262 CRC_ENGINE2 0;
BA_ "GenSigTimeoutTime_EPS" SG_ 262 CRC_ENGINE2 0;
BA_ "GenSigTimeoutTime_CVADAS" SG_ 262 ECM_LHOM_W 0;
BA_ "GenSigTimeoutTime_CVADAS" SG_ 262 EngineSpeed_W 0;
BA_ "GenSigTimeoutTime_CVADAS" SG_ 262 EngineSts_W 0;
BA_ "GenSigTimeoutTime_BSM" SG_ 262 EngineSts_W 0;
BA_ "GenSigTimeoutTime_EPS" SG_ 262 EngineSts_W 0;
BA_ "GenSigTimeoutTime_CVADAS" SG_ 262 ESS_ENG_ST_W 0;
BA_ "GenSigTimeoutTime_CVADAS" SG_ 262 GasPedalPosition_W 0;
BA_ "GenSigTimeoutTime_CVADAS" SG_ 262 GasPedalPositionFailSts_W 0;
BA_ "GenSigTimeoutTime_BSM" SG_ 262 GasPedalPositionFailSts_W 0;
BA_ "GenSigTimeoutTime_ADCAM" SG_ 262 LV12PwrFreeRq_W 0;
BA_ "GenSigTimeoutTime_CVADAS" SG_ 262 LV12PwrFreeRq_W 0;
BA_ "GenSigTimeoutTime_CVADAS" SG_ 262 MessageCounter_ENGINE2 0;
BA_ "GenSigTimeoutTime_BSM" SG_ 262 MessageCounter_ENGINE2 0;
BA_ "GenSigTimeoutTime_EPS" SG_ 262 MessageCounter_ENGINE2 0;
BA_ "GenSigTimeoutTime_CVADAS" SG_ 262 PowertrainPrplsnActv 0;
BA_ "GenSigTimeoutTime_BSM2" SG_ 262 CRC_ENGINE2 0;
BA_ "GenSigTimeoutTime_ECM" SG_ 262 CRC_ENGINE2 0;
BA_ "GenSigTimeoutTime_EVCU2" SG_ 262 CRC_ENGINE2 0;
BA_ "GenSigTimeoutTime_ORC" SG_ 262 CRC_ENGINE2 0;
BA_ "GenSigTimeoutTime_BSM" SG_ 262 ECM_LHOM_W 0;
BA_ "GenSigTimeoutTime_BSM2" SG_ 262 ECM_LHOM_W 0;
BA_ "GenSigTimeoutTime_CVPAM" SG_ 262 ECM_LHOM_W 0;
BA_ "GenSigTimeoutTime_ECM" SG_ 262 ECM_LHOM_W 0;
BA_ "GenSigTimeoutTime_EPS" SG_ 262 ECM_LHOM_W 0;
BA_ "GenSigTimeoutTime_EVCU2" SG_ 262 ECM_LHOM_W 0;
BA_ "GenSigTimeoutTime_ORC" SG_ 262 ECM_LHOM_W 0;
BA_ "GenSigTimeoutTime_BSM2" SG_ 262 EngineSpeed_W 0;
BA_ "GenSigTimeoutTime_CVPAM" SG_ 262 EngineSpeed_W 0;
BA_ "GenSigTimeoutTime_ECM" SG_ 262 EngineSpeed_W 0;
BA_ "GenSigTimeoutTime_EVCU2" SG_ 262 EngineSpeed_W 0;
BA_ "GenSigTimeoutTime_ORC" SG_ 262 EngineSpeed_W 0;
BA_ "GenSigStartValue" SG_ 262 EngineSts_W 3;
BA_ "GenSigTimeoutTime_BSM2" SG_ 262 EngineSts_W 0;
BA_ "GenSigTimeoutTime_ECM" SG_ 262 EngineSts_W 0;
BA_ "GenSigTimeoutTime_EVCU2" SG_ 262 EngineSts_W 0;
BA_ "GenSigTimeoutTime_ORC" SG_ 262 EngineSts_W 0;
BA_ "GenSigStartValue" SG_ 262 ESS_ENG_ST_W 15;
BA_ "GenSigSendType" SG_ 262 ESS_ENG_ST_W 3;
BA_ "GenSigTimeoutTime_BSM2" SG_ 262 ESS_ENG_ST_W 0;
BA_ "GenSigTimeoutTime_CVPAM" SG_ 262 ESS_ENG_ST_W 0;
BA_ "GenSigTimeoutTime_ECM" SG_ 262 ESS_ENG_ST_W 0;
BA_ "GenSigTimeoutTime_EVCU2" SG_ 262 ESS_ENG_ST_W 0;
BA_ "GenSigTimeoutTime_ORC" SG_ 262 ESS_ENG_ST_W 0;
BA_ "GenSigTimeoutTime_BSM2" SG_ 262 GasPedalPosition_W 0;
BA_ "GenSigTimeoutTime_CADM" SG_ 262 GasPedalPosition_W 0;
BA_ "GenSigTimeoutTime_CVPAM" SG_ 262 GasPedalPosition_W 0;
BA_ "GenSigTimeoutTime_ECM" SG_ 262 GasPedalPosition_W 0;
BA_ "GenSigTimeoutTime_EPS" SG_ 262 GasPedalPosition_W 0;
BA_ "GenSigTimeoutTime_EVCU2" SG_ 262 GasPedalPosition_W 0;
BA_ "GenSigTimeoutTime_ORC" SG_ 262 GasPedalPosition_W 0;
BA_ "GenSigTimeoutTime_BSM2" SG_ 262 GasPedalPositionFailSts_W 0;
BA_ "GenSigTimeoutTime_CVPAM" SG_ 262 GasPedalPositionFailSts_W 0;
BA_ "GenSigTimeoutTime_ECM" SG_ 262 GasPedalPositionFailSts_W 0;
BA_ "GenSigTimeoutTime_EPS" SG_ 262 GasPedalPositionFailSts_W 0;
BA_ "GenSigTimeoutTime_EVCU2" SG_ 262 GasPedalPositionFailSts_W 0;
BA_ "GenSigTimeoutTime_ORC" SG_ 262 GasPedalPositionFailSts_W 0;
BA_ "GenSigTimeoutTime_BSM" SG_ 262 LV12PwrFreeRq_W 0;
BA_ "GenSigTimeoutTime_BSM2" SG_ 262 LV12PwrFreeRq_W 0;
BA_ "GenSigTimeoutTime_CADM" SG_ 262 LV12PwrFreeRq_W 0;
BA_ "GenSigTimeoutTime_CVPAM" SG_ 262 LV12PwrFreeRq_W 0;
BA_ "GenSigTimeoutTime_ECM" SG_ 262 LV12PwrFreeRq_W 0;
BA_ "GenSigTimeoutTime_EPS" SG_ 262 LV12PwrFreeRq_W 0;
BA_ "GenSigTimeoutTime_EVCU2" SG_ 262 LV12PwrFreeRq_W 0;
BA_ "GenSigTimeoutTime_ORC" SG_ 262 LV12PwrFreeRq_W 0;
BA_ "GenSigTimeoutTime_BSM2" SG_ 262 MessageCounter_ENGINE2 0;
BA_ "GenSigTimeoutTime_ECM" SG_ 262 MessageCounter_ENGINE2 0;
BA_ "GenSigTimeoutTime_EVCU2" SG_ 262 MessageCounter_ENGINE2 0;
BA_ "GenSigTimeoutTime_ORC" SG_ 262 MessageCounter_ENGINE2 0;
BA_ "GenSigTimeoutTime_BSM2" SG_ 262 PowertrainPrplsnActv 0;
BA_ "GenSigTimeoutTime_CVPAM" SG_ 262 PowertrainPrplsnActv 0;
BA_ "GenSigTimeoutTime_ECM" SG_ 262 PowertrainPrplsnActv 0;
BA_ "GenSigTimeoutTime_EPS" SG_ 262 PowertrainPrplsnActv 0;
BA_ "GenSigTimeoutTime_EVCU2" SG_ 262 PowertrainPrplsnActv 0;
BA_ "GenSigTimeoutTime_ORC" SG_ 262 PowertrainPrplsnActv 0;
BA_ "GenSigTimeoutTime_ADCAM" SG_ 2654486529 CBV_bit0_RepeatMessageRequestBit_1E384001 0;
BA_ "GenSigTimeoutTime_CVADAS" SG_ 2654486529 CBV_bit0_RepeatMessageRequestBit_1E384001 0;
BA_ "GenSigTimeoutTime_ADCAM" SG_ 2654486529 CBV_bit1_1E384001 0;
BA_ "GenSigTimeoutTime_CVADAS" SG_ 2654486529 CBV_bit1_1E384001 0;
BA_ "GenSigTimeoutTime_ADCAM" SG_ 2654486529 CBV_bit2_1E384001 0;
BA_ "GenSigTimeoutTime_CVADAS" SG_ 2654486529 CBV_bit2_1E384001 0;
BA_ "GenSigTimeoutTime_ADCAM" SG_ 2654486529 CBV_bit3_NMCoordinatorBit_1E384001 0;
BA_ "GenSigTimeoutTime_CVADAS" SG_ 2654486529 CBV_bit3_NMCoordinatorBit_1E384001 0;
BA_ "GenSigTimeoutTime_ADCAM" SG_ 2654486529 CBV_bit4_ActiveWakeupBit_1E384001 0;
BA_ "GenSigTimeoutTime_CVADAS" SG_ 2654486529 CBV_bit4_ActiveWakeupBit_1E384001 0;
BA_ "GenSigTimeoutTime_ADCAM" SG_ 2654486529 CBV_bit5_1E384001 0;
BA_ "GenSigTimeoutTime_CVADAS" SG_ 2654486529 CBV_bit5_1E384001 0;
BA_ "GenSigTimeoutTime_ADCAM" SG_ 2654486529 CBV_bit6_PartialNtwInfBit_1E384001 0;
BA_ "GenSigTimeoutTime_CVADAS" SG_ 2654486529 CBV_bit6_PartialNtwInfBit_1E384001 0;
BA_ "GenSigTimeoutTime_ADCAM" SG_ 2654486529 CBV_bit7_1E384001 0;
BA_ "GenSigTimeoutTime_CVADAS" SG_ 2654486529 CBV_bit7_1E384001 0;
BA_ "GenSigTimeoutTime_ADCAM" SG_ 2654486529 SourceNodeIdentifier_1E384001 0;
BA_ "GenSigTimeoutTime_CVADAS" SG_ 2654486529 SourceNodeIdentifier_1E384001 0;
BA_ "GenSigTimeoutTime_BSM" SG_ 2654486529 CBV_bit0_RepeatMessageRequestBit_1E384001 0;
BA_ "GenSigTimeoutTime_BSM2" SG_ 2654486529 CBV_bit0_RepeatMessageRequestBit_1E384001 0;
BA_ "GenSigTimeoutTime_CADM" SG_ 2654486529 CBV_bit0_RepeatMessageRequestBit_1E384001 0;
BA_ "GenSigTimeoutTime_CVPAM" SG_ 2654486529 CBV_bit0_RepeatMessageRequestBit_1E384001 0;
BA_ "GenSigTimeoutTime_ECM" SG_ 2654486529 CBV_bit0_RepeatMessageRequestBit_1E384001 0;
BA_ "GenSigTimeoutTime_EPS" SG_ 2654486529 CBV_bit0_RepeatMessageRequestBit_1E384001 0;
BA_ "GenSigTimeoutTime_EVCU2" SG_ 2654486529 CBV_bit0_RepeatMessageRequestBit_1E384001 0;
BA_ "GenSigTimeoutTime_ORC" SG_ 2654486529 CBV_bit0_RepeatMessageRequestBit_1E384001 0;
BA_ "GenSigTimeoutTime_BSM" SG_ 2654486529 CBV_bit1_1E384001 0;
BA_ "GenSigTimeoutTime_BSM2" SG_ 2654486529 CBV_bit1_1E384001 0;
BA_ "GenSigTimeoutTime_CADM" SG_ 2654486529 CBV_bit1_1E384001 0;
BA_ "GenSigTimeoutTime_CVPAM" SG_ 2654486529 CBV_bit1_1E384001 0;
BA_ "GenSigTimeoutTime_ECM" SG_ 2654486529 CBV_bit1_1E384001 0;
BA_ "GenSigTimeoutTime_EPS" SG_ 2654486529 CBV_bit1_1E384001 0;
BA_ "GenSigTimeoutTime_EVCU2" SG_ 2654486529 CBV_bit1_1E384001 0;
BA_ "GenSigTimeoutTime_ORC" SG_ 2654486529 CBV_bit1_1E384001 0;
BA_ "GenSigTimeoutTime_BSM" SG_ 2654486529 CBV_bit2_1E384001 0;
BA_ "GenSigTimeoutTime_BSM2" SG_ 2654486529 CBV_bit2_1E384001 0;
BA_ "GenSigTimeoutTime_CADM" SG_ 2654486529 CBV_bit2_1E384001 0;
BA_ "GenSigTimeoutTime_CVPAM" SG_ 2654486529 CBV_bit2_1E384001 0;
BA_ "GenSigTimeoutTime_ECM" SG_ 2654486529 CBV_bit2_1E384001 0;
BA_ "GenSigTimeoutTime_EPS" SG_ 2654486529 CBV_bit2_1E384001 0;
BA_ "GenSigTimeoutTime_EVCU2" SG_ 2654486529 CBV_bit2_1E384001 0;
BA_ "GenSigTimeoutTime_ORC" SG_ 2654486529 CBV_bit2_1E384001 0;
BA_ "GenSigTimeoutTime_BSM" SG_ 2654486529 CBV_bit3_NMCoordinatorBit_1E384001 0;
BA_ "GenSigTimeoutTime_BSM2" SG_ 2654486529 CBV_bit3_NMCoordinatorBit_1E384001 0;
BA_ "GenSigTimeoutTime_CADM" SG_ 2654486529 CBV_bit3_NMCoordinatorBit_1E384001 0;
BA_ "GenSigTimeoutTime_CVPAM" SG_ 2654486529 CBV_bit3_NMCoordinatorBit_1E384001 0;
BA_ "GenSigTimeoutTime_ECM" SG_ 2654486529 CBV_bit3_NMCoordinatorBit_1E384001 0;
BA_ "GenSigTimeoutTime_EPS" SG_ 2654486529 CBV_bit3_NMCoordinatorBit_1E384001 0;
BA_ "GenSigTimeoutTime_EVCU2" SG_ 2654486529 CBV_bit3_NMCoordinatorBit_1E384001 0;
BA_ "GenSigTimeoutTime_ORC" SG_ 2654486529 CBV_bit3_NMCoordinatorBit_1E384001 0;
BA_ "GenSigTimeoutTime_BSM" SG_ 2654486529 CBV_bit4_ActiveWakeupBit_1E384001 0;
BA_ "GenSigTimeoutTime_BSM2" SG_ 2654486529 CBV_bit4_ActiveWakeupBit_1E384001 0;
BA_ "GenSigTimeoutTime_CADM" SG_ 2654486529 CBV_bit4_ActiveWakeupBit_1E384001 0;
BA_ "GenSigTimeoutTime_CVPAM" SG_ 2654486529 CBV_bit4_ActiveWakeupBit_1E384001 0;
BA_ "GenSigTimeoutTime_ECM" SG_ 2654486529 CBV_bit4_ActiveWakeupBit_1E384001 0;
BA_ "GenSigTimeoutTime_EPS" SG_ 2654486529 CBV_bit4_ActiveWakeupBit_1E384001 0;
BA_ "GenSigTimeoutTime_EVCU2" SG_ 2654486529 CBV_bit4_ActiveWakeupBit_1E384001 0;
BA_ "GenSigTimeoutTime_ORC" SG_ 2654486529 CBV_bit4_ActiveWakeupBit_1E384001 0;
BA_ "GenSigTimeoutTime_BSM" SG_ 2654486529 CBV_bit5_1E384001 0;
BA_ "GenSigTimeoutTime_BSM2" SG_ 2654486529 CBV_bit5_1E384001 0;
BA_ "GenSigTimeoutTime_CADM" SG_ 2654486529 CBV_bit5_1E384001 0;
BA_ "GenSigTimeoutTime_CVPAM" SG_ 2654486529 CBV_bit5_1E384001 0;
BA_ "GenSigTimeoutTime_ECM" SG_ 2654486529 CBV_bit5_1E384001 0;
BA_ "GenSigTimeoutTime_EPS" SG_ 2654486529 CBV_bit5_1E384001 0;
BA_ "GenSigTimeoutTime_EVCU2" SG_ 2654486529 CBV_bit5_1E384001 0;
BA_ "GenSigTimeoutTime_ORC" SG_ 2654486529 CBV_bit5_1E384001 0;
BA_ "GenSigTimeoutTime_BSM" SG_ 2654486529 CBV_bit6_PartialNtwInfBit_1E384001 0;
BA_ "GenSigTimeoutTime_BSM2" SG_ 2654486529 CBV_bit6_PartialNtwInfBit_1E384001 0;
BA_ "GenSigTimeoutTime_CADM" SG_ 2654486529 CBV_bit6_PartialNtwInfBit_1E384001 0;
BA_ "GenSigTimeoutTime_CVPAM" SG_ 2654486529 CBV_bit6_PartialNtwInfBit_1E384001 0;
BA_ "GenSigTimeoutTime_ECM" SG_ 2654486529 CBV_bit6_PartialNtwInfBit_1E384001 0;
BA_ "GenSigTimeoutTime_EPS" SG_ 2654486529 CBV_bit6_PartialNtwInfBit_1E384001 0;
BA_ "GenSigTimeoutTime_EVCU2" SG_ 2654486529 CBV_bit6_PartialNtwInfBit_1E384001 0;
BA_ "GenSigTimeoutTime_ORC" SG_ 2654486529 CBV_bit6_PartialNtwInfBit_1E384001 0;
BA_ "GenSigTimeoutTime_BSM" SG_ 2654486529 CBV_bit7_1E384001 0;
BA_ "GenSigTimeoutTime_BSM2" SG_ 2654486529 CBV_bit7_1E384001 0;
BA_ "GenSigTimeoutTime_CADM" SG_ 2654486529 CBV_bit7_1E384001 0;
BA_ "GenSigTimeoutTime_CVPAM" SG_ 2654486529 CBV_bit7_1E384001 0;
BA_ "GenSigTimeoutTime_ECM" SG_ 2654486529 CBV_bit7_1E384001 0;
BA_ "GenSigTimeoutTime_EPS" SG_ 2654486529 CBV_bit7_1E384001 0;
BA_ "GenSigTimeoutTime_EVCU2" SG_ 2654486529 CBV_bit7_1E384001 0;
BA_ "GenSigTimeoutTime_ORC" SG_ 2654486529 CBV_bit7_1E384001 0;
BA_ "GenSigTimeoutTime_BSM" SG_ 2654486529 SourceNodeIdentifier_1E384001 0;
BA_ "GenSigTimeoutTime_BSM2" SG_ 2654486529 SourceNodeIdentifier_1E384001 0;
BA_ "GenSigTimeoutTime_CADM" SG_ 2654486529 SourceNodeIdentifier_1E384001 0;
BA_ "GenSigTimeoutTime_CVPAM" SG_ 2654486529 SourceNodeIdentifier_1E384001 0;
BA_ "GenSigTimeoutTime_ECM" SG_ 2654486529 SourceNodeIdentifier_1E384001 0;
BA_ "GenSigTimeoutTime_EPS" SG_ 2654486529 SourceNodeIdentifier_1E384001 0;
BA_ "GenSigTimeoutTime_EVCU2" SG_ 2654486529 SourceNodeIdentifier_1E384001 0;
BA_ "GenSigTimeoutTime_ORC" SG_ 2654486529 SourceNodeIdentifier_1E384001 0;
BA_ "GenSigTimeoutTime_CVADAS" SG_ 280 ESA_TorqueOverlaySteeringReq 0;
BA_ "GenSigStartValue" SG_ 280 ESA_TorqueOverlaySteeringReq 1024;
BA_ "GenSigTimeoutTime_BSM" SG_ 280 ESA_TorqueOverlaySteeringReq 0;
BA_ "GenSigTimeoutTime_BSM2" SG_ 280 ESA_TorqueOverlaySteeringReq 0;
BA_ "GenSigTimeoutTime_CADM" SG_ 280 ESA_TorqueOverlaySteeringReq 0;
BA_ "GenSigTimeoutTime_ECM" SG_ 280 ESA_TorqueOverlaySteeringReq 0;
BA_ "GenSigTimeoutTime_EVCU2" SG_ 280 ESA_TorqueOverlaySteeringReq 0;
BA_ "GenSigTimeoutTime_ORC" SG_ 280 ESA_TorqueOverlaySteeringReq 0;
BA_ "GenSigTimeoutTime_CVADAS" SG_ 280 ESASystemSts 0;
BA_ "GenSigTimeoutTime_BSM2" SG_ 280 ESASystemSts 0;
BA_ "GenSigTimeoutTime_CADM" SG_ 280 ESASystemSts 0;
BA_ "GenSigTimeoutTime_ECM" SG_ 280 ESASystemSts 0;
BA_ "GenSigTimeoutTime_EVCU2" SG_ 280 ESASystemSts 0;
BA_ "GenSigTimeoutTime_ORC" SG_ 280 ESASystemSts 0;
BA_ "GenSigTimeoutTime_CVADAS" SG_ 280 ESA_LAT_CTRL_RequestSts 0;
BA_ "GenSigTimeoutTime_BSM" SG_ 280 ESA_LAT_CTRL_RequestSts 0;
BA_ "GenSigTimeoutTime_BSM2" SG_ 280 ESA_LAT_CTRL_RequestSts 0;
BA_ "GenSigTimeoutTime_CADM" SG_ 280 ESA_LAT_CTRL_RequestSts 0;
BA_ "GenSigTimeoutTime_ECM" SG_ 280 ESA_LAT_CTRL_RequestSts 0;
BA_ "GenSigTimeoutTime_EVCU2" SG_ 280 ESA_LAT_CTRL_RequestSts 0;
BA_ "GenSigTimeoutTime_ORC" SG_ 280 ESA_LAT_CTRL_RequestSts 0;
BA_ "GenSigTimeoutTime_CVADAS" SG_ 280 ESA_LaneClear_Status 0;
BA_ "GenSigSendType" SG_ 280 ESA_LaneClear_Status 3;
BA_ "GenSigTimeoutTime_BSM2" SG_ 280 ESA_LaneClear_Status 0;
BA_ "GenSigTimeoutTime_CADM" SG_ 280 ESA_LaneClear_Status 0;
BA_ "GenSigTimeoutTime_ECM" SG_ 280 ESA_LaneClear_Status 0;
BA_ "GenSigTimeoutTime_EPS" SG_ 280 ESA_LaneClear_Status 0;
BA_ "GenSigTimeoutTime_EVCU2" SG_ 280 ESA_LaneClear_Status 0;
BA_ "GenSigTimeoutTime_ORC" SG_ 280 ESA_LaneClear_Status 0;
BA_ "GenSigTimeoutTime_CVADAS" SG_ 280 ESA_FailSts 0;
BA_ "GenSigTimeoutTime_BSM2" SG_ 280 ESA_FailSts 0;
BA_ "GenSigTimeoutTime_CADM" SG_ 280 ESA_FailSts 0;
BA_ "GenSigTimeoutTime_ECM" SG_ 280 ESA_FailSts 0;
BA_ "GenSigTimeoutTime_EVCU2" SG_ 280 ESA_FailSts 0;
BA_ "GenSigTimeoutTime_ORC" SG_ 280 ESA_FailSts 0;
BA_ "GenSigTimeoutTime_MPAD" SG_ 280 ACC_Engine_Torque_Enabled 0;
BA_ "GenSigTimeoutTime_ADCAM" SG_ 280 ACC_Engine_Torque_Enabled 0;
BA_ "GenSigTimeoutTime_CVADAS" SG_ 280 ACC_Engine_Torque_Enabled 0;
BA_ "GenSigTimeoutTime_BSM2" SG_ 280 ACC_Engine_Torque_Enabled 0;
BA_ "GenSigTimeoutTime_EPS" SG_ 280 ACC_Engine_Torque_Enabled 0;
BA_ "GenSigTimeoutTime_EVCU2" SG_ 280 ACC_Engine_Torque_Enabled 0;
BA_ "GenSigTimeoutTime_ORC" SG_ 280 ACC_Engine_Torque_Enabled 0;
BA_ "GenSigTimeoutTime_MPAD" SG_ 280 PEB_SystemSts 0;
BA_ "GenSigTimeoutTime_ADCAM" SG_ 280 PEB_SystemSts 0;
BA_ "GenSigTimeoutTime_CVADAS" SG_ 280 PEB_SystemSts 0;
BA_ "GenSigTimeoutTime_MPAD" SG_ 280 Prefill_Req 0;
BA_ "GenSigTimeoutTime_ADCAM" SG_ 280 Prefill_Req 0;
BA_ "GenSigTimeoutTime_CVADAS" SG_ 280 Prefill_Req 0;
BA_ "GenSigTimeoutTime_BSM2" SG_ 280 Prefill_Req 0;
BA_ "GenSigTimeoutTime_MPAD" SG_ 280 ACC_Drive_Cmd 0;
BA_ "GenSigTimeoutTime_ADCAM" SG_ 280 ACC_Drive_Cmd 0;
BA_ "GenSigTimeoutTime_CVADAS" SG_ 280 ACC_Drive_Cmd 0;
BA_ "GenSigTimeoutTime_MPAD" SG_ 280 Brake_Jerk_Req 0;
BA_ "GenSigTimeoutTime_ADCAM" SG_ 280 Brake_Jerk_Req 0;
BA_ "GenSigTimeoutTime_CVADAS" SG_ 280 Brake_Jerk_Req 0;
BA_ "GenSigTimeoutTime_BSM2" SG_ 280 Brake_Jerk_Req 0;
BA_ "GenSigTimeoutTime_MPAD" SG_ 280 CIPV_Fused 0;
BA_ "GenSigTimeoutTime_ADCAM" SG_ 280 CIPV_Fused 0;
BA_ "GenSigTimeoutTime_CVADAS" SG_ 280 CIPV_Fused 0;
BA_ "GenSigTimeoutTime_MPAD" SG_ 280 GrMax_Rq_ACC 0;
BA_ "GenSigTimeoutTime_ADCAM" SG_ 280 GrMax_Rq_ACC 0;
BA_ "GenSigTimeoutTime_CVADAS" SG_ 280 GrMax_Rq_ACC 0;
BA_ "GenSigTimeoutTime_MPAD" SG_ 280 ESCALATION_TYPE 0;
BA_ "GenSigTimeoutTime_ADCAM" SG_ 280 ESCALATION_TYPE 0;
BA_ "GenSigTimeoutTime_CVADAS" SG_ 280 ESCALATION_TYPE 0;
BA_ "GenSigTimeoutTime_MPAD" SG_ 280 HAS_LAT_CTRL_RequestSts 0;
BA_ "GenSigTimeoutTime_ADCAM" SG_ 280 HAS_LAT_CTRL_RequestSts 0;
BA_ "GenSigTimeoutTime_CVADAS" SG_ 280 HAS_LAT_CTRL_RequestSts 0;
BA_ "GenSigTimeoutTime_MPAD" SG_ 280 HAS_OpStat_Prim 0;
BA_ "GenSigTimeoutTime_ADCAM" SG_ 280 HAS_OpStat_Prim 0;
BA_ "GenSigTimeoutTime_CVADAS" SG_ 280 HAS_OpStat_Prim 0;
BA_ "GenSigTimeoutTime_MPAD" SG_ 280 HAS_Status 0;
BA_ "GenSigTimeoutTime_ADCAM" SG_ 280 HAS_Status 0;
BA_ "GenSigTimeoutTime_EPS" SG_ 280 HAS_Status 0;
BA_ "GenSigTimeoutTime_MPAD" SG_ 280 LANE_CHANGE_SIDE 0;
BA_ "GenSigTimeoutTime_ADCAM" SG_ 280 LANE_CHANGE_SIDE 0;
BA_ "GenSigTimeoutTime_CVADAS" SG_ 280 LANE_CHANGE_SIDE 0;
BA_ "GenSigTimeoutTime_MPAD" SG_ 280 MRM_STATUS 0;
BA_ "GenSigTimeoutTime_ADCAM" SG_ 280 MRM_STATUS 0;
BA_ "GenSigTimeoutTime_CVADAS" SG_ 280 MRM_STATUS 0;
BA_ "GenSigTimeoutTime_EVCU2" SG_ 280 MRM_STATUS 0;
BA_ "GenSigTimeoutTime_MPAD" SG_ 280 AEB_Sensitivity_Setting 0;
BA_ "GenSigTimeoutTime_ADCAM" SG_ 280 AEB_Sensitivity_Setting 0;
BA_ "GenSigTimeoutTime_CVADAS" SG_ 280 AEB_Sensitivity_Setting 0;
BA_ "GenSigTimeoutTime_MPAD" SG_ 280 AEB_Systemsts 0;
BA_ "GenSigTimeoutTime_ADCAM" SG_ 280 AEB_Systemsts 0;
BA_ "GenSigTimeoutTime_CVADAS" SG_ 280 AEB_Systemsts 0;
BA_ "GenSigTimeoutTime_MPAD" SG_ 280 AEB_Type 0;
BA_ "GenSigTimeoutTime_ADCAM" SG_ 280 AEB_Type 0;
BA_ "GenSigTimeoutTime_CVADAS" SG_ 280 AEB_Type 0;
BA_ "GenSigTimeoutTime_MPAD" SG_ 280 CADM_OpStat 0;
BA_ "GenSigTimeoutTime_ADCAM" SG_ 280 CADM_OpStat 0;
BA_ "GenSigTimeoutTime_CVADAS" SG_ 280 CADM_OpStat 0;
BA_ "GenSigTimeoutTime_MPAD" SG_ 280 DDD_Setting_Avail 0;
BA_ "GenSigTimeoutTime_ADCAM" SG_ 280 DDD_Setting_Avail 0;
BA_ "GenSigTimeoutTime_CVADAS" SG_ 280 DDD_Setting_Avail 0;
BA_ "GenSigTimeoutTime_MPAD" SG_ 280 DDD_SystemSts 0;
BA_ "GenSigTimeoutTime_ADCAM" SG_ 280 DDD_SystemSts 0;
BA_ "GenSigTimeoutTime_CVADAS" SG_ 280 DDD_SystemSts 0;
BA_ "GenSigTimeoutTime_MPAD" SG_ 280 LANE_CHANGE_STATUS 0;
BA_ "GenSigTimeoutTime_ADCAM" SG_ 280 LANE_CHANGE_STATUS 0;
BA_ "GenSigTimeoutTime_CVADAS" SG_ 280 LANE_CHANGE_STATUS 0;
BA_ "GenSigTimeoutTime_MPAD" SG_ 280 LKA_LAT_CTRL_RequestSts 0;
BA_ "GenSigTimeoutTime_ADCAM" SG_ 280 LKA_LAT_CTRL_RequestSts 0;
BA_ "GenSigTimeoutTime_CVADAS" SG_ 280 LKA_LAT_CTRL_RequestSts 0;
BA_ "GenSigTimeoutTime_MPAD" SG_ 280 SteeringVibration_Rq 0;
BA_ "GenSigTimeoutTime_ADCAM" SG_ 280 SteeringVibration_Rq 0;
BA_ "GenSigTimeoutTime_CVADAS" SG_ 280 SteeringVibration_Rq 0;
BA_ "GenSigTimeoutTime_MPAD" SG_ 280 SteeringVibration_Type 0;
BA_ "GenSigTimeoutTime_ADCAM" SG_ 280 SteeringVibration_Type 0;
BA_ "GenSigTimeoutTime_CVADAS" SG_ 280 SteeringVibration_Type 0;
BA_ "GenSigTimeoutTime_ADCAM" SG_ 280 ACC_StopStart 0;
BA_ "GenSigTimeoutTime_CVADAS" SG_ 280 ACC_StopStart 0;
BA_ "GenSigTimeoutTime_MPAD" SG_ 280 ACC_Systemsts 0;
BA_ "GenSigTimeoutTime_ADCAM" SG_ 280 ACC_Systemsts 0;
BA_ "GenSigTimeoutTime_CVADAS" SG_ 280 ACC_Systemsts 0;
BA_ "GenSigTimeoutTime_MPAD" SG_ 280 TorqueOverlaySteeringReq 0;
BA_ "GenSigTimeoutTime_ADCAM" SG_ 280 TorqueOverlaySteeringReq 0;
BA_ "GenSigTimeoutTime_CVADAS" SG_ 280 TorqueOverlaySteeringReq 0;
BA_ "GenSigTimeoutTime_MPAD" SG_ 280 CADM2_EPSSEC_FAIL 0;
BA_ "GenSigTimeoutTime_ADCAM" SG_ 280 CADM2_EPSSEC_FAIL 0;
BA_ "GenSigTimeoutTime_CVADAS" SG_ 280 CADM2_EPSSEC_FAIL 0;
BA_ "GenSigTimeoutTime_MPAD" SG_ 280 LC_Jerk 0;
BA_ "GenSigTimeoutTime_ADCAM" SG_ 280 LC_Jerk 0;
BA_ "GenSigTimeoutTime_CVADAS" SG_ 280 LC_Jerk 0;
BA_ "GenSigTimeoutTime_MPAD" SG_ 280 HIS_Req 0;
BA_ "GenSigTimeoutTime_ADCAM" SG_ 280 HIS_Req 0;
BA_ "GenSigTimeoutTime_CVADAS" SG_ 280 HIS_Req 0;
BA_ "GenSigTimeoutTime_MPAD" SG_ 280 Intervention 0;
BA_ "GenSigTimeoutTime_ADCAM" SG_ 280 Intervention 0;
BA_ "GenSigTimeoutTime_CVADAS" SG_ 280 Intervention 0;
BA_ "GenSigTimeoutTime_MPAD" SG_ 280 ACC_DsrSpeedKPH 0;
BA_ "GenSigTimeoutTime_ADCAM" SG_ 280 ACC_DsrSpeedKPH 0;
BA_ "GenSigTimeoutTime_CVADAS" SG_ 280 ACC_DsrSpeedKPH 0;
BA_ "GenSigTimeoutTime_MPAD" SG_ 280 CRC_ADAS_FD_INFO 0;
BA_ "GenSigTimeoutTime_ADCAM" SG_ 280 CRC_ADAS_FD_INFO 0;
BA_ "GenSigTimeoutTime_CVADAS" SG_ 280 CRC_ADAS_FD_INFO 0;
BA_ "GenSigTimeoutTime_ECM" SG_ 280 CRC_ADAS_FD_INFO 0;
BA_ "GenSigTimeoutTime_MPAD" SG_ 280 MessageCounter_ADAS_FD_INFO 0;
BA_ "GenSigTimeoutTime_ADCAM" SG_ 280 MessageCounter_ADAS_FD_INFO 0;
BA_ "GenSigTimeoutTime_CVADAS" SG_ 280 MessageCounter_ADAS_FD_INFO 0;
BA_ "GenSigTimeoutTime_ECM" SG_ 280 MessageCounter_ADAS_FD_INFO 0;
BA_ "GenSigTimeoutTime_MPAD" SG_ 280 Object_Dist 0;
BA_ "GenSigTimeoutTime_ADCAM" SG_ 280 Object_Dist 0;
BA_ "GenSigTimeoutTime_CVADAS" SG_ 280 Object_Dist 0;
BA_ "GenSigTimeoutTime_BSM" SG_ 280 PEB_SystemSts 0;
BA_ "GenSigTimeoutTime_BSM2" SG_ 280 PEB_SystemSts 0;
BA_ "GenSigTimeoutTime_CADM" SG_ 280 PEB_SystemSts 0;
BA_ "GenSigTimeoutTime_CVPAM" SG_ 280 PEB_SystemSts 0;
BA_ "GenSigTimeoutTime_ECM" SG_ 280 PEB_SystemSts 0;
BA_ "GenSigTimeoutTime_EPS" SG_ 280 PEB_SystemSts 0;
BA_ "GenSigTimeoutTime_EVCU2" SG_ 280 PEB_SystemSts 0;
BA_ "GenSigTimeoutTime_CADM" SG_ 280 Prefill_Req 0;
BA_ "GenSigTimeoutTime_CVPAM" SG_ 280 Prefill_Req 0;
BA_ "GenSigTimeoutTime_ECM" SG_ 280 Prefill_Req 0;
BA_ "GenSigTimeoutTime_EPS" SG_ 280 Prefill_Req 0;
BA_ "GenSigTimeoutTime_EVCU2" SG_ 280 Prefill_Req 0;
BA_ "GenSigTimeoutTime_ORC" SG_ 280 Prefill_Req 0;
BA_ "GenSigTimeoutTime_BSM2" SG_ 280 ACC_Drive_Cmd 0;
BA_ "GenSigTimeoutTime_CADM" SG_ 280 ACC_Drive_Cmd 0;
BA_ "GenSigTimeoutTime_CVPAM" SG_ 280 ACC_Drive_Cmd 0;
BA_ "GenSigTimeoutTime_ECM" SG_ 280 ACC_Drive_Cmd 0;
BA_ "GenSigTimeoutTime_EPS" SG_ 280 ACC_Drive_Cmd 0;
BA_ "GenSigTimeoutTime_EVCU2" SG_ 280 ACC_Drive_Cmd 0;
BA_ "GenSigTimeoutTime_ORC" SG_ 280 ACC_Drive_Cmd 0;
BA_ "GenSigTimeoutTime_CADM" SG_ 280 Brake_Jerk_Req 0;
BA_ "GenSigTimeoutTime_CVPAM" SG_ 280 Brake_Jerk_Req 0;
BA_ "GenSigTimeoutTime_ECM" SG_ 280 Brake_Jerk_Req 0;
BA_ "GenSigTimeoutTime_EPS" SG_ 280 Brake_Jerk_Req 0;
BA_ "GenSigTimeoutTime_EVCU2" SG_ 280 Brake_Jerk_Req 0;
BA_ "GenSigTimeoutTime_ORC" SG_ 280 Brake_Jerk_Req 0;
BA_ "GenSigTimeoutTime_BSM" SG_ 280 CIPV_Fused 0;
BA_ "GenSigTimeoutTime_BSM2" SG_ 280 CIPV_Fused 0;
BA_ "GenSigTimeoutTime_CADM" SG_ 280 CIPV_Fused 0;
BA_ "GenSigTimeoutTime_CVPAM" SG_ 280 CIPV_Fused 0;
BA_ "GenSigTimeoutTime_ECM" SG_ 280 CIPV_Fused 0;
BA_ "GenSigTimeoutTime_EPS" SG_ 280 CIPV_Fused 0;
BA_ "GenSigTimeoutTime_EVCU2" SG_ 280 CIPV_Fused 0;
BA_ "GenSigTimeoutTime_BSM2" SG_ 280 GrMax_Rq_ACC 0;
BA_ "GenSigTimeoutTime_CADM" SG_ 280 GrMax_Rq_ACC 0;
BA_ "GenSigTimeoutTime_CVPAM" SG_ 280 GrMax_Rq_ACC 0;
BA_ "GenSigTimeoutTime_ECM" SG_ 280 GrMax_Rq_ACC 0;
BA_ "GenSigTimeoutTime_EPS" SG_ 280 GrMax_Rq_ACC 0;
BA_ "GenSigTimeoutTime_EVCU2" SG_ 280 GrMax_Rq_ACC 0;
BA_ "GenSigTimeoutTime_ORC" SG_ 280 GrMax_Rq_ACC 0;
BA_ "GenSigTimeoutTime_BSM" SG_ 280 ESCALATION_TYPE 0;
BA_ "GenSigTimeoutTime_BSM2" SG_ 280 ESCALATION_TYPE 0;
BA_ "GenSigTimeoutTime_CADM" SG_ 280 ESCALATION_TYPE 0;
BA_ "GenSigTimeoutTime_CVPAM" SG_ 280 ESCALATION_TYPE 0;
BA_ "GenSigTimeoutTime_ECM" SG_ 280 ESCALATION_TYPE 0;
BA_ "GenSigTimeoutTime_EPS" SG_ 280 ESCALATION_TYPE 0;
BA_ "GenSigTimeoutTime_EVCU2" SG_ 280 ESCALATION_TYPE 0;
BA_ "GenSigTimeoutTime_BSM" SG_ 280 HAS_LAT_CTRL_RequestSts 0;
BA_ "GenSigTimeoutTime_BSM2" SG_ 280 HAS_LAT_CTRL_RequestSts 0;
BA_ "GenSigTimeoutTime_CADM" SG_ 280 HAS_LAT_CTRL_RequestSts 0;
BA_ "GenSigTimeoutTime_CVPAM" SG_ 280 HAS_LAT_CTRL_RequestSts 0;
BA_ "GenSigTimeoutTime_ECM" SG_ 280 HAS_LAT_CTRL_RequestSts 0;
BA_ "GenSigTimeoutTime_EVCU2" SG_ 280 HAS_LAT_CTRL_RequestSts 0;
BA_ "GenSigTimeoutTime_ORC" SG_ 280 HAS_LAT_CTRL_RequestSts 0;
BA_ "GenSigTimeoutTime_BSM" SG_ 280 HAS_OpStat_Prim 0;
BA_ "GenSigTimeoutTime_BSM2" SG_ 280 HAS_OpStat_Prim 0;
BA_ "GenSigTimeoutTime_CADM" SG_ 280 HAS_OpStat_Prim 0;
BA_ "GenSigTimeoutTime_CVPAM" SG_ 280 HAS_OpStat_Prim 0;
BA_ "GenSigTimeoutTime_ECM" SG_ 280 HAS_OpStat_Prim 0;
BA_ "GenSigTimeoutTime_EPS" SG_ 280 HAS_OpStat_Prim 0;
BA_ "GenSigTimeoutTime_EVCU2" SG_ 280 HAS_OpStat_Prim 0;
BA_ "GenSigTimeoutTime_CADM" SG_ 280 HAS_Status 0;
BA_ "GenSigTimeoutTime_ECM" SG_ 280 HAS_Status 0;
BA_ "GenSigTimeoutTime_EVCU2" SG_ 280 HAS_Status 0;
BA_ "GenSigTimeoutTime_ORC" SG_ 280 HAS_Status 0;
BA_ "GenSigTimeoutTime_BSM" SG_ 280 LANE_CHANGE_SIDE 0;
BA_ "GenSigTimeoutTime_BSM2" SG_ 280 LANE_CHANGE_SIDE 0;
BA_ "GenSigTimeoutTime_CADM" SG_ 280 LANE_CHANGE_SIDE 0;
BA_ "GenSigTimeoutTime_CVPAM" SG_ 280 LANE_CHANGE_SIDE 0;
BA_ "GenSigTimeoutTime_ECM" SG_ 280 LANE_CHANGE_SIDE 0;
BA_ "GenSigTimeoutTime_EPS" SG_ 280 LANE_CHANGE_SIDE 0;
BA_ "GenSigTimeoutTime_EVCU2" SG_ 280 LANE_CHANGE_SIDE 0;
BA_ "GenSigTimeoutTime_BSM" SG_ 280 MRM_STATUS 0;
BA_ "GenSigTimeoutTime_BSM2" SG_ 280 MRM_STATUS 0;
BA_ "GenSigTimeoutTime_CADM" SG_ 280 MRM_STATUS 0;
BA_ "GenSigTimeoutTime_CVPAM" SG_ 280 MRM_STATUS 0;
BA_ "GenSigTimeoutTime_ECM" SG_ 280 MRM_STATUS 0;
BA_ "GenSigTimeoutTime_EPS" SG_ 280 MRM_STATUS 0;
BA_ "GenSigTimeoutTime_BSM" SG_ 280 AEB_Sensitivity_Setting 0;
BA_ "GenSigTimeoutTime_BSM2" SG_ 280 AEB_Sensitivity_Setting 0;
BA_ "GenSigTimeoutTime_CADM" SG_ 280 AEB_Sensitivity_Setting 0;
BA_ "GenSigTimeoutTime_CVPAM" SG_ 280 AEB_Sensitivity_Setting 0;
BA_ "GenSigTimeoutTime_ECM" SG_ 280 AEB_Sensitivity_Setting 0;
BA_ "GenSigTimeoutTime_EPS" SG_ 280 AEB_Sensitivity_Setting 0;
BA_ "GenSigTimeoutTime_EVCU2" SG_ 280 AEB_Sensitivity_Setting 0;
BA_ "GenSigTimeoutTime_ORC" SG_ 280 AEB_Sensitivity_Setting 0;
BA_ "GenSigTimeoutTime_BSM" SG_ 280 AEB_Systemsts 0;
BA_ "GenSigTimeoutTime_BSM2" SG_ 280 AEB_Systemsts 0;
BA_ "GenSigTimeoutTime_CADM" SG_ 280 AEB_Systemsts 0;
BA_ "GenSigTimeoutTime_CVPAM" SG_ 280 AEB_Systemsts 0;
BA_ "GenSigTimeoutTime_ECM" SG_ 280 AEB_Systemsts 0;
BA_ "GenSigTimeoutTime_EPS" SG_ 280 AEB_Systemsts 0;
BA_ "GenSigTimeoutTime_EVCU2" SG_ 280 AEB_Systemsts 0;
BA_ "GenSigTimeoutTime_CADM" SG_ 280 AEB_Type 0;
BA_ "GenSigTimeoutTime_CVPAM" SG_ 280 AEB_Type 0;
BA_ "GenSigTimeoutTime_ECM" SG_ 280 AEB_Type 0;
BA_ "GenSigTimeoutTime_EPS" SG_ 280 AEB_Type 0;
BA_ "GenSigTimeoutTime_EVCU2" SG_ 280 AEB_Type 0;
BA_ "GenSigTimeoutTime_BSM" SG_ 280 CADM_OpStat 0;
BA_ "GenSigTimeoutTime_BSM2" SG_ 280 CADM_OpStat 0;
BA_ "GenSigTimeoutTime_CADM" SG_ 280 CADM_OpStat 0;
BA_ "GenSigTimeoutTime_CVPAM" SG_ 280 CADM_OpStat 0;
BA_ "GenSigTimeoutTime_ECM" SG_ 280 CADM_OpStat 0;
BA_ "GenSigTimeoutTime_EPS" SG_ 280 CADM_OpStat 0;
BA_ "GenSigTimeoutTime_EVCU2" SG_ 280 CADM_OpStat 0;
BA_ "GenSigTimeoutTime_ORC" SG_ 280 CADM_OpStat 0;
BA_ "GenSigTimeoutTime_BSM" SG_ 280 DDD_Setting_Avail 0;
BA_ "GenSigTimeoutTime_BSM2" SG_ 280 DDD_Setting_Avail 0;
BA_ "GenSigTimeoutTime_CADM" SG_ 280 DDD_Setting_Avail 0;
BA_ "GenSigTimeoutTime_CVPAM" SG_ 280 DDD_Setting_Avail 0;
BA_ "GenSigTimeoutTime_ECM" SG_ 280 DDD_Setting_Avail 0;
BA_ "GenSigTimeoutTime_EPS" SG_ 280 DDD_Setting_Avail 0;
BA_ "GenSigTimeoutTime_EVCU2" SG_ 280 DDD_Setting_Avail 0;
BA_ "GenSigTimeoutTime_ORC" SG_ 280 DDD_Setting_Avail 0;
BA_ "GenSigTimeoutTime_BSM" SG_ 280 DDD_SystemSts 0;
BA_ "GenSigTimeoutTime_BSM2" SG_ 280 DDD_SystemSts 0;
BA_ "GenSigTimeoutTime_CADM" SG_ 280 DDD_SystemSts 0;
BA_ "GenSigTimeoutTime_CVPAM" SG_ 280 DDD_SystemSts 0;
BA_ "GenSigTimeoutTime_ECM" SG_ 280 DDD_SystemSts 0;
BA_ "GenSigTimeoutTime_EPS" SG_ 280 DDD_SystemSts 0;
BA_ "GenSigTimeoutTime_EVCU2" SG_ 280 DDD_SystemSts 0;
BA_ "GenSigTimeoutTime_BSM" SG_ 280 LANE_CHANGE_STATUS 0;
BA_ "GenSigTimeoutTime_BSM2" SG_ 280 LANE_CHANGE_STATUS 0;
BA_ "GenSigTimeoutTime_CADM" SG_ 280 LANE_CHANGE_STATUS 0;
BA_ "GenSigTimeoutTime_CVPAM" SG_ 280 LANE_CHANGE_STATUS 0;
BA_ "GenSigTimeoutTime_ECM" SG_ 280 LANE_CHANGE_STATUS 0;
BA_ "GenSigTimeoutTime_EPS" SG_ 280 LANE_CHANGE_STATUS 0;
BA_ "GenSigTimeoutTime_EVCU2" SG_ 280 LANE_CHANGE_STATUS 0;
BA_ "GenSigTimeoutTime_BSM" SG_ 280 LKA_LAT_CTRL_RequestSts 0;
BA_ "GenSigTimeoutTime_BSM2" SG_ 280 LKA_LAT_CTRL_RequestSts 0;
BA_ "GenSigTimeoutTime_CADM" SG_ 280 LKA_LAT_CTRL_RequestSts 0;
BA_ "GenSigTimeoutTime_CVPAM" SG_ 280 LKA_LAT_CTRL_RequestSts 0;
BA_ "GenSigTimeoutTime_ECM" SG_ 280 LKA_LAT_CTRL_RequestSts 0;
BA_ "GenSigTimeoutTime_EVCU2" SG_ 280 LKA_LAT_CTRL_RequestSts 0;
BA_ "GenSigTimeoutTime_ORC" SG_ 280 LKA_LAT_CTRL_RequestSts 0;
BA_ "GenSigTimeoutTime_BSM" SG_ 280 SteeringVibration_Rq 0;
BA_ "GenSigTimeoutTime_BSM2" SG_ 280 SteeringVibration_Rq 0;
BA_ "GenSigTimeoutTime_CADM" SG_ 280 SteeringVibration_Rq 0;
BA_ "GenSigTimeoutTime_CVPAM" SG_ 280 SteeringVibration_Rq 0;
BA_ "GenSigTimeoutTime_ECM" SG_ 280 SteeringVibration_Rq 0;
BA_ "GenSigTimeoutTime_EVCU2" SG_ 280 SteeringVibration_Rq 0;
BA_ "GenSigTimeoutTime_ORC" SG_ 280 SteeringVibration_Rq 0;
BA_ "GenSigTimeoutTime_BSM" SG_ 280 SteeringVibration_Type 0;
BA_ "GenSigTimeoutTime_BSM2" SG_ 280 SteeringVibration_Type 0;
BA_ "GenSigTimeoutTime_CADM" SG_ 280 SteeringVibration_Type 0;
BA_ "GenSigTimeoutTime_CVPAM" SG_ 280 SteeringVibration_Type 0;
BA_ "GenSigTimeoutTime_ECM" SG_ 280 SteeringVibration_Type 0;
BA_ "GenSigTimeoutTime_EVCU2" SG_ 280 SteeringVibration_Type 0;
BA_ "GenSigTimeoutTime_ORC" SG_ 280 SteeringVibration_Type 0;
BA_ "GenSigTimeoutTime_BSM" SG_ 280 ACC_StopStart 0;
BA_ "GenSigTimeoutTime_BSM2" SG_ 280 ACC_StopStart 0;
BA_ "GenSigTimeoutTime_CADM" SG_ 280 ACC_StopStart 0;
BA_ "GenSigTimeoutTime_CVPAM" SG_ 280 ACC_StopStart 0;
BA_ "GenSigTimeoutTime_EPS" SG_ 280 ACC_StopStart 0;
BA_ "GenSigTimeoutTime_EVCU2" SG_ 280 ACC_StopStart 0;
BA_ "GenSigTimeoutTime_ORC" SG_ 280 ACC_StopStart 0;
BA_ "GenSigTimeoutTime_CADM" SG_ 280 ACC_Systemsts 0;
BA_ "GenSigTimeoutTime_ECM" SG_ 280 ACC_Systemsts 0;
BA_ "GenSigTimeoutTime_EPS" SG_ 280 ACC_Systemsts 0;
BA_ "GenSigTimeoutTime_EVCU2" SG_ 280 ACC_Systemsts 0;
BA_ "GenSigStartValue" SG_ 280 TorqueOverlaySteeringReq 1024;
BA_ "GenSigTimeoutTime_BSM" SG_ 280 TorqueOverlaySteeringReq 0;
BA_ "GenSigTimeoutTime_BSM2" SG_ 280 TorqueOverlaySteeringReq 0;
BA_ "GenSigTimeoutTime_CADM" SG_ 280 TorqueOverlaySteeringReq 0;
BA_ "GenSigTimeoutTime_CVPAM" SG_ 280 TorqueOverlaySteeringReq 0;
BA_ "GenSigTimeoutTime_ECM" SG_ 280 TorqueOverlaySteeringReq 0;
BA_ "GenSigTimeoutTime_EVCU2" SG_ 280 TorqueOverlaySteeringReq 0;
BA_ "GenSigTimeoutTime_BSM" SG_ 280 CADM2_EPSSEC_FAIL 0;
BA_ "GenSigTimeoutTime_BSM2" SG_ 280 CADM2_EPSSEC_FAIL 0;
BA_ "GenSigTimeoutTime_CADM" SG_ 280 CADM2_EPSSEC_FAIL 0;
BA_ "GenSigTimeoutTime_CVPAM" SG_ 280 CADM2_EPSSEC_FAIL 0;
BA_ "GenSigTimeoutTime_ECM" SG_ 280 CADM2_EPSSEC_FAIL 0;
BA_ "GenSigTimeoutTime_EVCU2" SG_ 280 CADM2_EPSSEC_FAIL 0;
BA_ "GenSigTimeoutTime_ORC" SG_ 280 CADM2_EPSSEC_FAIL 0;
BA_ "GenSigTimeoutTime_BSM2" SG_ 280 LC_Jerk 0;
BA_ "GenSigTimeoutTime_CADM" SG_ 280 LC_Jerk 0;
BA_ "GenSigTimeoutTime_CVPAM" SG_ 280 LC_Jerk 0;
BA_ "GenSigTimeoutTime_ECM" SG_ 280 LC_Jerk 0;
BA_ "GenSigTimeoutTime_EPS" SG_ 280 LC_Jerk 0;
BA_ "GenSigTimeoutTime_EVCU2" SG_ 280 LC_Jerk 0;
BA_ "GenSigTimeoutTime_ORC" SG_ 280 LC_Jerk 0;
BA_ "GenSigTimeoutTime_CADM" SG_ 280 HIS_Req 0;
BA_ "GenSigTimeoutTime_CVPAM" SG_ 280 HIS_Req 0;
BA_ "GenSigTimeoutTime_ECM" SG_ 280 HIS_Req 0;
BA_ "GenSigTimeoutTime_EPS" SG_ 280 HIS_Req 0;
BA_ "GenSigTimeoutTime_EVCU2" SG_ 280 HIS_Req 0;
BA_ "GenSigStartValue" SG_ 280 Intervention 4095;
BA_ "GenSigTimeoutTime_CADM" SG_ 280 Intervention 0;
BA_ "GenSigTimeoutTime_CVPAM" SG_ 280 Intervention 0;
BA_ "GenSigTimeoutTime_ECM" SG_ 280 Intervention 0;
BA_ "GenSigTimeoutTime_EPS" SG_ 280 Intervention 0;
BA_ "GenSigTimeoutTime_EVCU2" SG_ 280 Intervention 0;
BA_ "GenSigStartValue" SG_ 280 ACC_DsrSpeedKPH 255;
BA_ "GenSigTimeoutTime_BSM" SG_ 280 ACC_DsrSpeedKPH 0;
BA_ "GenSigTimeoutTime_BSM2" SG_ 280 ACC_DsrSpeedKPH 0;
BA_ "GenSigTimeoutTime_CADM" SG_ 280 ACC_DsrSpeedKPH 0;
BA_ "GenSigTimeoutTime_CVPAM" SG_ 280 ACC_DsrSpeedKPH 0;
BA_ "GenSigTimeoutTime_ECM" SG_ 280 ACC_DsrSpeedKPH 0;
BA_ "GenSigTimeoutTime_EPS" SG_ 280 ACC_DsrSpeedKPH 0;
BA_ "GenSigTimeoutTime_ORC" SG_ 280 ACC_DsrSpeedKPH 0;
BA_ "GenSigTimeoutTime_CADM" SG_ 280 CRC_ADAS_FD_INFO 0;
BA_ "GenSigTimeoutTime_EVCU2" SG_ 280 CRC_ADAS_FD_INFO 0;
BA_ "GenSigTimeoutTime_ORC" SG_ 280 CRC_ADAS_FD_INFO 0;
BA_ "GenSigTimeoutTime_CADM" SG_ 280 MessageCounter_ADAS_FD_INFO 0;
BA_ "GenSigTimeoutTime_EVCU2" SG_ 280 MessageCounter_ADAS_FD_INFO 0;
BA_ "GenSigTimeoutTime_ORC" SG_ 280 MessageCounter_ADAS_FD_INFO 0;
BA_ "GenSigStartValue" SG_ 280 Object_Dist 255;
BA_ "GenSigTimeoutTime_BSM2" SG_ 280 Object_Dist 0;
BA_ "GenSigTimeoutTime_CADM" SG_ 280 Object_Dist 0;
BA_ "GenSigTimeoutTime_CVPAM" SG_ 280 Object_Dist 0;
BA_ "GenSigTimeoutTime_ECM" SG_ 280 Object_Dist 0;
BA_ "GenSigTimeoutTime_EPS" SG_ 280 Object_Dist 0;
BA_ "GenSigTimeoutTime_CVADAS" SG_ 2654486669 CBV_bit0_RepeatMessageRequestBit_1E38408D 0;
BA_ "GenSigTimeoutTime_CVADAS" SG_ 2654486669 CBV_bit1_1E38408D 0;
BA_ "GenSigTimeoutTime_CVADAS" SG_ 2654486669 CBV_bit2_1E38408D 0;
BA_ "GenSigTimeoutTime_CVADAS" SG_ 2654486669 CBV_bit3_NMCoordinatorBit_1E38408D 0;
BA_ "GenSigTimeoutTime_CVADAS" SG_ 2654486669 CBV_bit4_ActiveWakeupBit_1E38408D 0;
BA_ "GenSigTimeoutTime_CVADAS" SG_ 2654486669 CBV_bit5_1E38408D 0;
BA_ "GenSigTimeoutTime_CVADAS" SG_ 2654486669 CBV_bit6_PartialNtwInfBit_1E38408D 0;
BA_ "GenSigTimeoutTime_CVADAS" SG_ 2654486669 CBV_bit7_1E38408D 0;
BA_ "GenSigTimeoutTime_CVADAS" SG_ 2654486669 SourceNodeIdentifier_1E38408D 0;
BA_ "GenSigTimeoutTime_BSM" SG_ 2654486669 CBV_bit0_RepeatMessageRequestBit_1E38408D 0;
BA_ "GenSigTimeoutTime_BSM2" SG_ 2654486669 CBV_bit0_RepeatMessageRequestBit_1E38408D 0;
BA_ "GenSigTimeoutTime_CADM" SG_ 2654486669 CBV_bit0_RepeatMessageRequestBit_1E38408D 0;
BA_ "GenSigTimeoutTime_CVPAM" SG_ 2654486669 CBV_bit0_RepeatMessageRequestBit_1E38408D 0;
BA_ "GenSigTimeoutTime_ECM" SG_ 2654486669 CBV_bit0_RepeatMessageRequestBit_1E38408D 0;
BA_ "GenSigTimeoutTime_EPS" SG_ 2654486669 CBV_bit0_RepeatMessageRequestBit_1E38408D 0;
BA_ "GenSigTimeoutTime_EVCU2" SG_ 2654486669 CBV_bit0_RepeatMessageRequestBit_1E38408D 0;
BA_ "GenSigTimeoutTime_ORC" SG_ 2654486669 CBV_bit0_RepeatMessageRequestBit_1E38408D 0;
BA_ "GenSigTimeoutTime_BSM" SG_ 2654486669 CBV_bit1_1E38408D 0;
BA_ "GenSigTimeoutTime_BSM2" SG_ 2654486669 CBV_bit1_1E38408D 0;
BA_ "GenSigTimeoutTime_CADM" SG_ 2654486669 CBV_bit1_1E38408D 0;
BA_ "GenSigTimeoutTime_CVPAM" SG_ 2654486669 CBV_bit1_1E38408D 0;
BA_ "GenSigTimeoutTime_ECM" SG_ 2654486669 CBV_bit1_1E38408D 0;
BA_ "GenSigTimeoutTime_EPS" SG_ 2654486669 CBV_bit1_1E38408D 0;
BA_ "GenSigTimeoutTime_EVCU2" SG_ 2654486669 CBV_bit1_1E38408D 0;
BA_ "GenSigTimeoutTime_ORC" SG_ 2654486669 CBV_bit1_1E38408D 0;
BA_ "GenSigTimeoutTime_BSM" SG_ 2654486669 CBV_bit2_1E38408D 0;
BA_ "GenSigTimeoutTime_BSM2" SG_ 2654486669 CBV_bit2_1E38408D 0;
BA_ "GenSigTimeoutTime_CADM" SG_ 2654486669 CBV_bit2_1E38408D 0;
BA_ "GenSigTimeoutTime_CVPAM" SG_ 2654486669 CBV_bit2_1E38408D 0;
BA_ "GenSigTimeoutTime_ECM" SG_ 2654486669 CBV_bit2_1E38408D 0;
BA_ "GenSigTimeoutTime_EPS" SG_ 2654486669 CBV_bit2_1E38408D 0;
BA_ "GenSigTimeoutTime_EVCU2" SG_ 2654486669 CBV_bit2_1E38408D 0;
BA_ "GenSigTimeoutTime_ORC" SG_ 2654486669 CBV_bit2_1E38408D 0;
BA_ "GenSigTimeoutTime_BSM" SG_ 2654486669 CBV_bit3_NMCoordinatorBit_1E38408D 0;
BA_ "GenSigTimeoutTime_BSM2" SG_ 2654486669 CBV_bit3_NMCoordinatorBit_1E38408D 0;
BA_ "GenSigTimeoutTime_CADM" SG_ 2654486669 CBV_bit3_NMCoordinatorBit_1E38408D 0;
BA_ "GenSigTimeoutTime_CVPAM" SG_ 2654486669 CBV_bit3_NMCoordinatorBit_1E38408D 0;
BA_ "GenSigTimeoutTime_ECM" SG_ 2654486669 CBV_bit3_NMCoordinatorBit_1E38408D 0;
BA_ "GenSigTimeoutTime_EPS" SG_ 2654486669 CBV_bit3_NMCoordinatorBit_1E38408D 0;
BA_ "GenSigTimeoutTime_EVCU2" SG_ 2654486669 CBV_bit3_NMCoordinatorBit_1E38408D 0;
BA_ "GenSigTimeoutTime_ORC" SG_ 2654486669 CBV_bit3_NMCoordinatorBit_1E38408D 0;
BA_ "GenSigTimeoutTime_BSM" SG_ 2654486669 CBV_bit4_ActiveWakeupBit_1E38408D 0;
BA_ "GenSigTimeoutTime_BSM2" SG_ 2654486669 CBV_bit4_ActiveWakeupBit_1E38408D 0;
BA_ "GenSigTimeoutTime_CADM" SG_ 2654486669 CBV_bit4_ActiveWakeupBit_1E38408D 0;
BA_ "GenSigTimeoutTime_CVPAM" SG_ 2654486669 CBV_bit4_ActiveWakeupBit_1E38408D 0;
BA_ "GenSigTimeoutTime_ECM" SG_ 2654486669 CBV_bit4_ActiveWakeupBit_1E38408D 0;
BA_ "GenSigTimeoutTime_EPS" SG_ 2654486669 CBV_bit4_ActiveWakeupBit_1E38408D 0;
BA_ "GenSigTimeoutTime_EVCU2" SG_ 2654486669 CBV_bit4_ActiveWakeupBit_1E38408D 0;
BA_ "GenSigTimeoutTime_ORC" SG_ 2654486669 CBV_bit4_ActiveWakeupBit_1E38408D 0;
BA_ "GenSigTimeoutTime_BSM" SG_ 2654486669 CBV_bit5_1E38408D 0;
BA_ "GenSigTimeoutTime_BSM2" SG_ 2654486669 CBV_bit5_1E38408D 0;
BA_ "GenSigTimeoutTime_CADM" SG_ 2654486669 CBV_bit5_1E38408D 0;
BA_ "GenSigTimeoutTime_CVPAM" SG_ 2654486669 CBV_bit5_1E38408D 0;
BA_ "GenSigTimeoutTime_ECM" SG_ 2654486669 CBV_bit5_1E38408D 0;
BA_ "GenSigTimeoutTime_EPS" SG_ 2654486669 CBV_bit5_1E38408D 0;
BA_ "GenSigTimeoutTime_EVCU2" SG_ 2654486669 CBV_bit5_1E38408D 0;
BA_ "GenSigTimeoutTime_ORC" SG_ 2654486669 CBV_bit5_1E38408D 0;
BA_ "GenSigTimeoutTime_BSM" SG_ 2654486669 CBV_bit6_PartialNtwInfBit_1E38408D 0;
BA_ "GenSigTimeoutTime_BSM2" SG_ 2654486669 CBV_bit6_PartialNtwInfBit_1E38408D 0;
BA_ "GenSigTimeoutTime_CADM" SG_ 2654486669 CBV_bit6_PartialNtwInfBit_1E38408D 0;
BA_ "GenSigTimeoutTime_CVPAM" SG_ 2654486669 CBV_bit6_PartialNtwInfBit_1E38408D 0;
BA_ "GenSigTimeoutTime_ECM" SG_ 2654486669 CBV_bit6_PartialNtwInfBit_1E38408D 0;
BA_ "GenSigTimeoutTime_EPS" SG_ 2654486669 CBV_bit6_PartialNtwInfBit_1E38408D 0;
BA_ "GenSigTimeoutTime_EVCU2" SG_ 2654486669 CBV_bit6_PartialNtwInfBit_1E38408D 0;
BA_ "GenSigTimeoutTime_ORC" SG_ 2654486669 CBV_bit6_PartialNtwInfBit_1E38408D 0;
BA_ "GenSigTimeoutTime_BSM" SG_ 2654486669 CBV_bit7_1E38408D 0;
BA_ "GenSigTimeoutTime_BSM2" SG_ 2654486669 CBV_bit7_1E38408D 0;
BA_ "GenSigTimeoutTime_CADM" SG_ 2654486669 CBV_bit7_1E38408D 0;
BA_ "GenSigTimeoutTime_CVPAM" SG_ 2654486669 CBV_bit7_1E38408D 0;
BA_ "GenSigTimeoutTime_ECM" SG_ 2654486669 CBV_bit7_1E38408D 0;
BA_ "GenSigTimeoutTime_EPS" SG_ 2654486669 CBV_bit7_1E38408D 0;
BA_ "GenSigTimeoutTime_EVCU2" SG_ 2654486669 CBV_bit7_1E38408D 0;
BA_ "GenSigTimeoutTime_ORC" SG_ 2654486669 CBV_bit7_1E38408D 0;
BA_ "GenSigTimeoutTime_BSM" SG_ 2654486669 SourceNodeIdentifier_1E38408D 0;
BA_ "GenSigTimeoutTime_BSM2" SG_ 2654486669 SourceNodeIdentifier_1E38408D 0;
BA_ "GenSigTimeoutTime_CADM" SG_ 2654486669 SourceNodeIdentifier_1E38408D 0;
BA_ "GenSigTimeoutTime_CVPAM" SG_ 2654486669 SourceNodeIdentifier_1E38408D 0;
BA_ "GenSigTimeoutTime_ECM" SG_ 2654486669 SourceNodeIdentifier_1E38408D 0;
BA_ "GenSigTimeoutTime_EPS" SG_ 2654486669 SourceNodeIdentifier_1E38408D 0;
BA_ "GenSigTimeoutTime_EVCU2" SG_ 2654486669 SourceNodeIdentifier_1E38408D 0;
BA_ "GenSigTimeoutTime_ORC" SG_ 2654486669 SourceNodeIdentifier_1E38408D 0;
BA_ "GenSigTimeoutTime_ADCAM" SG_ 726 PA_Obj5_Angle 0;
BA_ "GenSigTimeoutTime_CVADAS" SG_ 726 PA_Obj5_Angle 0;
BA_ "GenSigTimeoutTime_ADCAM" SG_ 726 PA_Obj5_Angle_2 0;
BA_ "GenSigTimeoutTime_CVADAS" SG_ 726 PA_Obj5_Angle_2 0;
BA_ "GenSigTimeoutTime_ADCAM" SG_ 726 PA_Obj5_Conf 0;
BA_ "GenSigTimeoutTime_CVADAS" SG_ 726 PA_Obj5_Conf 0;
BA_ "GenSigTimeoutTime_ADCAM" SG_ 726 PA_Obj5_Range 0;
BA_ "GenSigTimeoutTime_CVADAS" SG_ 726 PA_Obj5_Range 0;
BA_ "GenSigTimeoutTime_ADCAM" SG_ 726 PA_Obj5_Range_2 0;
BA_ "GenSigTimeoutTime_CVADAS" SG_ 726 PA_Obj5_Range_2 0;
BA_ "GenSigTimeoutTime_ADCAM" SG_ 726 PA_Obj5_Type 0;
BA_ "GenSigTimeoutTime_CVADAS" SG_ 726 PA_Obj5_Type 0;
BA_ "GenSigTimeoutTime_ADCAM" SG_ 726 PA_Obj4_Angle 0;
BA_ "GenSigTimeoutTime_CVADAS" SG_ 726 PA_Obj4_Angle 0;
BA_ "GenSigTimeoutTime_ADCAM" SG_ 726 PA_Obj4_Angle_2 0;
BA_ "GenSigTimeoutTime_CVADAS" SG_ 726 PA_Obj4_Angle_2 0;
BA_ "GenSigTimeoutTime_ADCAM" SG_ 726 PA_Obj4_Conf 0;
BA_ "GenSigTimeoutTime_CVADAS" SG_ 726 PA_Obj4_Conf 0;
BA_ "GenSigTimeoutTime_ADCAM" SG_ 726 PA_Obj4_Range 0;
BA_ "GenSigTimeoutTime_CVADAS" SG_ 726 PA_Obj4_Range 0;
BA_ "GenSigTimeoutTime_ADCAM" SG_ 726 PA_Obj4_Range_2 0;
BA_ "GenSigTimeoutTime_CVADAS" SG_ 726 PA_Obj4_Range_2 0;
BA_ "GenSigTimeoutTime_ADCAM" SG_ 726 PA_Obj4_Type 0;
BA_ "GenSigTimeoutTime_CVADAS" SG_ 726 PA_Obj4_Type 0;
BA_ "GenSigTimeoutTime_ADCAM" SG_ 726 PA_Obj3_Angle 0;
BA_ "GenSigTimeoutTime_CVADAS" SG_ 726 PA_Obj3_Angle 0;
BA_ "GenSigTimeoutTime_ADCAM" SG_ 726 PA_Obj3_Angle_2 0;
BA_ "GenSigTimeoutTime_CVADAS" SG_ 726 PA_Obj3_Angle_2 0;
BA_ "GenSigTimeoutTime_ADCAM" SG_ 726 PA_Obj3_Conf 0;
BA_ "GenSigTimeoutTime_CVADAS" SG_ 726 PA_Obj3_Conf 0;
BA_ "GenSigTimeoutTime_ADCAM" SG_ 726 PA_Obj3_Range 0;
BA_ "GenSigTimeoutTime_CVADAS" SG_ 726 PA_Obj3_Range 0;
BA_ "GenSigTimeoutTime_ADCAM" SG_ 726 PA_Obj3_Range_2 0;
BA_ "GenSigTimeoutTime_CVADAS" SG_ 726 PA_Obj3_Range_2 0;
BA_ "GenSigTimeoutTime_ADCAM" SG_ 726 PA_Obj3_Type 0;
BA_ "GenSigTimeoutTime_CVADAS" SG_ 726 PA_Obj3_Type 0;
BA_ "GenSigTimeoutTime_ADCAM" SG_ 726 PA_Obj2_Angle 0;
BA_ "GenSigTimeoutTime_CVADAS" SG_ 726 PA_Obj2_Angle 0;
BA_ "GenSigTimeoutTime_ADCAM" SG_ 726 PA_Obj2_Angle_2 0;
BA_ "GenSigTimeoutTime_CVADAS" SG_ 726 PA_Obj2_Angle_2 0;
BA_ "GenSigTimeoutTime_ADCAM" SG_ 726 PA_Obj2_Conf 0;
BA_ "GenSigTimeoutTime_CVADAS" SG_ 726 PA_Obj2_Conf 0;
BA_ "GenSigTimeoutTime_ADCAM" SG_ 726 PA_Obj2_Range 0;
BA_ "GenSigTimeoutTime_CVADAS" SG_ 726 PA_Obj2_Range 0;
BA_ "GenSigTimeoutTime_ADCAM" SG_ 726 PA_Obj2_Range_2 0;
BA_ "GenSigTimeoutTime_CVADAS" SG_ 726 PA_Obj2_Range_2 0;
BA_ "GenSigTimeoutTime_ADCAM" SG_ 726 PA_Obj2_Type 0;
BA_ "GenSigTimeoutTime_CVADAS" SG_ 726 PA_Obj2_Type 0;
BA_ "GenSigTimeoutTime_ADCAM" SG_ 726 PA_Obj1_Angle 0;
BA_ "GenSigTimeoutTime_CVADAS" SG_ 726 PA_Obj1_Angle 0;
BA_ "GenSigTimeoutTime_ADCAM" SG_ 726 PA_Obj1_Angle_2 0;
BA_ "GenSigTimeoutTime_CVADAS" SG_ 726 PA_Obj1_Angle_2 0;
BA_ "GenSigTimeoutTime_ADCAM" SG_ 726 PA_Obj1_Conf 0;
BA_ "GenSigTimeoutTime_CVADAS" SG_ 726 PA_Obj1_Conf 0;
BA_ "GenSigTimeoutTime_ADCAM" SG_ 726 PA_Obj1_Range 0;
BA_ "GenSigTimeoutTime_CVADAS" SG_ 726 PA_Obj1_Range 0;
BA_ "GenSigTimeoutTime_ADCAM" SG_ 726 PA_Obj1_Range_2 0;
BA_ "GenSigTimeoutTime_CVADAS" SG_ 726 PA_Obj1_Range_2 0;
BA_ "GenSigTimeoutTime_ADCAM" SG_ 726 PA_Obj1_Type 0;
BA_ "GenSigTimeoutTime_CVADAS" SG_ 726 PA_Obj1_Type 0;
BA_ "GenSigTimeoutTime_ADCAM" SG_ 726 Reserved_for_functional_safety_2D6 0;
BA_ "GenSigTimeoutTime_CVADAS" SG_ 726 Reserved_for_functional_safety_2D6 0;
BA_ "GenSigTimeoutTime_ADCAM" SG_ 726 Cntr_CVPAM_FD_Data 0;
BA_ "GenSigTimeoutTime_CVADAS" SG_ 726 Cntr_CVPAM_FD_Data 0;
BA_ "GenSigTimeoutTime_ADCAM" SG_ 726 CRC_CVPAM_FD_Data 0;
BA_ "GenSigTimeoutTime_CVADAS" SG_ 726 CRC_CVPAM_FD_Data 0;
BA_ "GenSigTimeoutTime_ADCAM" SG_ 726 MAC_CVPAM_FD_Data 0;
BA_ "GenSigTimeoutTime_CVADAS" SG_ 726 MAC_CVPAM_FD_Data 0;
BA_ "GenSigTimeoutTime_ADCAM" SG_ 726 MessageCounter_CVPAM_FD_Data 0;
BA_ "GenSigTimeoutTime_CVADAS" SG_ 726 MessageCounter_CVPAM_FD_Data 0;
BA_ "GenSigTimeoutTime_ADCAM" SG_ 726 PA_Front_Sensor_Det_Health 0;
BA_ "GenSigTimeoutTime_CVADAS" SG_ 726 PA_Front_Sensor_Det_Health 0;
BA_ "GenSigTimeoutTime_ADCAM" SG_ 726 PA_Obj6_Angle 0;
BA_ "GenSigTimeoutTime_CVADAS" SG_ 726 PA_Obj6_Angle 0;
BA_ "GenSigTimeoutTime_ADCAM" SG_ 726 PA_Obj6_Angle_2 0;
BA_ "GenSigTimeoutTime_CVADAS" SG_ 726 PA_Obj6_Angle_2 0;
BA_ "GenSigTimeoutTime_ADCAM" SG_ 726 PA_Obj6_Conf 0;
BA_ "GenSigTimeoutTime_CVADAS" SG_ 726 PA_Obj6_Conf 0;
BA_ "GenSigTimeoutTime_ADCAM" SG_ 726 PA_Obj6_Range 0;
BA_ "GenSigTimeoutTime_CVADAS" SG_ 726 PA_Obj6_Range 0;
BA_ "GenSigTimeoutTime_ADCAM" SG_ 726 PA_Obj6_Range_2 0;
BA_ "GenSigTimeoutTime_CVADAS" SG_ 726 PA_Obj6_Range_2 0;
BA_ "GenSigTimeoutTime_ADCAM" SG_ 726 PA_Obj6_Type 0;
BA_ "GenSigTimeoutTime_CVADAS" SG_ 726 PA_Obj6_Type 0;
BA_ "GenSigTimeoutTime_BSM" SG_ 726 PA_Obj5_Angle 0;
BA_ "GenSigTimeoutTime_BSM2" SG_ 726 PA_Obj5_Angle 0;
BA_ "GenSigTimeoutTime_CVPAM" SG_ 726 PA_Obj5_Angle 0;
BA_ "GenSigTimeoutTime_ECM" SG_ 726 PA_Obj5_Angle 0;
BA_ "GenSigTimeoutTime_EPS" SG_ 726 PA_Obj5_Angle 0;
BA_ "GenSigTimeoutTime_EVCU2" SG_ 726 PA_Obj5_Angle 0;
BA_ "GenSigTimeoutTime_ORC" SG_ 726 PA_Obj5_Angle 0;
BA_ "GenSigTimeoutTime_BSM" SG_ 726 PA_Obj5_Angle_2 0;
BA_ "GenSigTimeoutTime_BSM2" SG_ 726 PA_Obj5_Angle_2 0;
BA_ "GenSigTimeoutTime_CVPAM" SG_ 726 PA_Obj5_Angle_2 0;
BA_ "GenSigTimeoutTime_ECM" SG_ 726 PA_Obj5_Angle_2 0;
BA_ "GenSigTimeoutTime_EPS" SG_ 726 PA_Obj5_Angle_2 0;
BA_ "GenSigTimeoutTime_EVCU2" SG_ 726 PA_Obj5_Angle_2 0;
BA_ "GenSigTimeoutTime_ORC" SG_ 726 PA_Obj5_Angle_2 0;
BA_ "GenSigTimeoutTime_BSM" SG_ 726 PA_Obj5_Conf 0;
BA_ "GenSigTimeoutTime_BSM2" SG_ 726 PA_Obj5_Conf 0;
BA_ "GenSigTimeoutTime_CVPAM" SG_ 726 PA_Obj5_Conf 0;
BA_ "GenSigTimeoutTime_ECM" SG_ 726 PA_Obj5_Conf 0;
BA_ "GenSigTimeoutTime_EPS" SG_ 726 PA_Obj5_Conf 0;
BA_ "GenSigTimeoutTime_EVCU2" SG_ 726 PA_Obj5_Conf 0;
BA_ "GenSigTimeoutTime_ORC" SG_ 726 PA_Obj5_Conf 0;
BA_ "GenSigTimeoutTime_BSM" SG_ 726 PA_Obj5_Range 0;
BA_ "GenSigTimeoutTime_BSM2" SG_ 726 PA_Obj5_Range 0;
BA_ "GenSigTimeoutTime_CVPAM" SG_ 726 PA_Obj5_Range 0;
BA_ "GenSigTimeoutTime_ECM" SG_ 726 PA_Obj5_Range 0;
BA_ "GenSigTimeoutTime_EPS" SG_ 726 PA_Obj5_Range 0;
BA_ "GenSigTimeoutTime_EVCU2" SG_ 726 PA_Obj5_Range 0;
BA_ "GenSigTimeoutTime_ORC" SG_ 726 PA_Obj5_Range 0;
BA_ "GenSigTimeoutTime_BSM" SG_ 726 PA_Obj5_Range_2 0;
BA_ "GenSigTimeoutTime_BSM2" SG_ 726 PA_Obj5_Range_2 0;
BA_ "GenSigTimeoutTime_CVPAM" SG_ 726 PA_Obj5_Range_2 0;
BA_ "GenSigTimeoutTime_ECM" SG_ 726 PA_Obj5_Range_2 0;
BA_ "GenSigTimeoutTime_EPS" SG_ 726 PA_Obj5_Range_2 0;
BA_ "GenSigTimeoutTime_EVCU2" SG_ 726 PA_Obj5_Range_2 0;
BA_ "GenSigTimeoutTime_ORC" SG_ 726 PA_Obj5_Range_2 0;
BA_ "GenSigTimeoutTime_BSM" SG_ 726 PA_Obj5_Type 0;
BA_ "GenSigTimeoutTime_BSM2" SG_ 726 PA_Obj5_Type 0;
BA_ "GenSigTimeoutTime_CVPAM" SG_ 726 PA_Obj5_Type 0;
BA_ "GenSigTimeoutTime_ECM" SG_ 726 PA_Obj5_Type 0;
BA_ "GenSigTimeoutTime_EPS" SG_ 726 PA_Obj5_Type 0;
BA_ "GenSigTimeoutTime_EVCU2" SG_ 726 PA_Obj5_Type 0;
BA_ "GenSigTimeoutTime_ORC" SG_ 726 PA_Obj5_Type 0;
BA_ "GenSigTimeoutTime_BSM" SG_ 726 PA_Obj4_Angle 0;
BA_ "GenSigTimeoutTime_BSM2" SG_ 726 PA_Obj4_Angle 0;
BA_ "GenSigTimeoutTime_CVPAM" SG_ 726 PA_Obj4_Angle 0;
BA_ "GenSigTimeoutTime_ECM" SG_ 726 PA_Obj4_Angle 0;
BA_ "GenSigTimeoutTime_EPS" SG_ 726 PA_Obj4_Angle 0;
BA_ "GenSigTimeoutTime_EVCU2" SG_ 726 PA_Obj4_Angle 0;
BA_ "GenSigTimeoutTime_ORC" SG_ 726 PA_Obj4_Angle 0;
BA_ "GenSigTimeoutTime_BSM" SG_ 726 PA_Obj4_Angle_2 0;
BA_ "GenSigTimeoutTime_BSM2" SG_ 726 PA_Obj4_Angle_2 0;
BA_ "GenSigTimeoutTime_CVPAM" SG_ 726 PA_Obj4_Angle_2 0;
BA_ "GenSigTimeoutTime_ECM" SG_ 726 PA_Obj4_Angle_2 0;
BA_ "GenSigTimeoutTime_EPS" SG_ 726 PA_Obj4_Angle_2 0;
BA_ "GenSigTimeoutTime_EVCU2" SG_ 726 PA_Obj4_Angle_2 0;
BA_ "GenSigTimeoutTime_ORC" SG_ 726 PA_Obj4_Angle_2 0;
BA_ "GenSigTimeoutTime_BSM" SG_ 726 PA_Obj4_Conf 0;
BA_ "GenSigTimeoutTime_BSM2" SG_ 726 PA_Obj4_Conf 0;
BA_ "GenSigTimeoutTime_CVPAM" SG_ 726 PA_Obj4_Conf 0;
BA_ "GenSigTimeoutTime_ECM" SG_ 726 PA_Obj4_Conf 0;
BA_ "GenSigTimeoutTime_EPS" SG_ 726 PA_Obj4_Conf 0;
BA_ "GenSigTimeoutTime_EVCU2" SG_ 726 PA_Obj4_Conf 0;
BA_ "GenSigTimeoutTime_ORC" SG_ 726 PA_Obj4_Conf 0;
BA_ "GenSigTimeoutTime_BSM" SG_ 726 PA_Obj4_Range 0;
BA_ "GenSigTimeoutTime_BSM2" SG_ 726 PA_Obj4_Range 0;
BA_ "GenSigTimeoutTime_CVPAM" SG_ 726 PA_Obj4_Range 0;
BA_ "GenSigTimeoutTime_ECM" SG_ 726 PA_Obj4_Range 0;
BA_ "GenSigTimeoutTime_EPS" SG_ 726 PA_Obj4_Range 0;
BA_ "GenSigTimeoutTime_EVCU2" SG_ 726 PA_Obj4_Range 0;
BA_ "GenSigTimeoutTime_ORC" SG_ 726 PA_Obj4_Range 0;
BA_ "GenSigTimeoutTime_BSM" SG_ 726 PA_Obj4_Range_2 0;
BA_ "GenSigTimeoutTime_BSM2" SG_ 726 PA_Obj4_Range_2 0;
BA_ "GenSigTimeoutTime_CVPAM" SG_ 726 PA_Obj4_Range_2 0;
BA_ "GenSigTimeoutTime_ECM" SG_ 726 PA_Obj4_Range_2 0;
BA_ "GenSigTimeoutTime_EPS" SG_ 726 PA_Obj4_Range_2 0;
BA_ "GenSigTimeoutTime_EVCU2" SG_ 726 PA_Obj4_Range_2 0;
BA_ "GenSigTimeoutTime_ORC" SG_ 726 PA_Obj4_Range_2 0;
BA_ "GenSigTimeoutTime_BSM" SG_ 726 PA_Obj4_Type 0;
BA_ "GenSigTimeoutTime_BSM2" SG_ 726 PA_Obj4_Type 0;
BA_ "GenSigTimeoutTime_CVPAM" SG_ 726 PA_Obj4_Type 0;
BA_ "GenSigTimeoutTime_ECM" SG_ 726 PA_Obj4_Type 0;
BA_ "GenSigTimeoutTime_EPS" SG_ 726 PA_Obj4_Type 0;
BA_ "GenSigTimeoutTime_EVCU2" SG_ 726 PA_Obj4_Type 0;
BA_ "GenSigTimeoutTime_ORC" SG_ 726 PA_Obj4_Type 0;
BA_ "GenSigTimeoutTime_BSM" SG_ 726 PA_Obj3_Angle 0;
BA_ "GenSigTimeoutTime_BSM2" SG_ 726 PA_Obj3_Angle 0;
BA_ "GenSigTimeoutTime_CVPAM" SG_ 726 PA_Obj3_Angle 0;
BA_ "GenSigTimeoutTime_ECM" SG_ 726 PA_Obj3_Angle 0;
BA_ "GenSigTimeoutTime_EPS" SG_ 726 PA_Obj3_Angle 0;
BA_ "GenSigTimeoutTime_EVCU2" SG_ 726 PA_Obj3_Angle 0;
BA_ "GenSigTimeoutTime_ORC" SG_ 726 PA_Obj3_Angle 0;
BA_ "GenSigTimeoutTime_BSM" SG_ 726 PA_Obj3_Angle_2 0;
BA_ "GenSigTimeoutTime_BSM2" SG_ 726 PA_Obj3_Angle_2 0;
BA_ "GenSigTimeoutTime_CVPAM" SG_ 726 PA_Obj3_Angle_2 0;
BA_ "GenSigTimeoutTime_ECM" SG_ 726 PA_Obj3_Angle_2 0;
BA_ "GenSigTimeoutTime_EPS" SG_ 726 PA_Obj3_Angle_2 0;
BA_ "GenSigTimeoutTime_EVCU2" SG_ 726 PA_Obj3_Angle_2 0;
BA_ "GenSigTimeoutTime_ORC" SG_ 726 PA_Obj3_Angle_2 0;
BA_ "GenSigTimeoutTime_BSM" SG_ 726 PA_Obj3_Conf 0;
BA_ "GenSigTimeoutTime_BSM2" SG_ 726 PA_Obj3_Conf 0;
BA_ "GenSigTimeoutTime_CVPAM" SG_ 726 PA_Obj3_Conf 0;
BA_ "GenSigTimeoutTime_ECM" SG_ 726 PA_Obj3_Conf 0;
BA_ "GenSigTimeoutTime_EPS" SG_ 726 PA_Obj3_Conf 0;
BA_ "GenSigTimeoutTime_EVCU2" SG_ 726 PA_Obj3_Conf 0;
BA_ "GenSigTimeoutTime_ORC" SG_ 726 PA_Obj3_Conf 0;
BA_ "GenSigTimeoutTime_BSM" SG_ 726 PA_Obj3_Range 0;
BA_ "GenSigTimeoutTime_BSM2" SG_ 726 PA_Obj3_Range 0;
BA_ "GenSigTimeoutTime_CVPAM" SG_ 726 PA_Obj3_Range 0;
BA_ "GenSigTimeoutTime_ECM" SG_ 726 PA_Obj3_Range 0;
BA_ "GenSigTimeoutTime_EPS" SG_ 726 PA_Obj3_Range 0;
BA_ "GenSigTimeoutTime_EVCU2" SG_ 726 PA_Obj3_Range 0;
BA_ "GenSigTimeoutTime_ORC" SG_ 726 PA_Obj3_Range 0;
BA_ "GenSigTimeoutTime_BSM" SG_ 726 PA_Obj3_Range_2 0;
BA_ "GenSigTimeoutTime_BSM2" SG_ 726 PA_Obj3_Range_2 0;
BA_ "GenSigTimeoutTime_CVPAM" SG_ 726 PA_Obj3_Range_2 0;
BA_ "GenSigTimeoutTime_ECM" SG_ 726 PA_Obj3_Range_2 0;
BA_ "GenSigTimeoutTime_EPS" SG_ 726 PA_Obj3_Range_2 0;
BA_ "GenSigTimeoutTime_EVCU2" SG_ 726 PA_Obj3_Range_2 0;
BA_ "GenSigTimeoutTime_ORC" SG_ 726 PA_Obj3_Range_2 0;
BA_ "GenSigTimeoutTime_BSM" SG_ 726 PA_Obj3_Type 0;
BA_ "GenSigTimeoutTime_BSM2" SG_ 726 PA_Obj3_Type 0;
BA_ "GenSigTimeoutTime_CVPAM" SG_ 726 PA_Obj3_Type 0;
BA_ "GenSigTimeoutTime_ECM" SG_ 726 PA_Obj3_Type 0;
BA_ "GenSigTimeoutTime_EPS" SG_ 726 PA_Obj3_Type 0;
BA_ "GenSigTimeoutTime_EVCU2" SG_ 726 PA_Obj3_Type 0;
BA_ "GenSigTimeoutTime_ORC" SG_ 726 PA_Obj3_Type 0;
BA_ "GenSigTimeoutTime_BSM" SG_ 726 PA_Obj2_Angle 0;
BA_ "GenSigTimeoutTime_BSM2" SG_ 726 PA_Obj2_Angle 0;
BA_ "GenSigTimeoutTime_CVPAM" SG_ 726 PA_Obj2_Angle 0;
BA_ "GenSigTimeoutTime_ECM" SG_ 726 PA_Obj2_Angle 0;
BA_ "GenSigTimeoutTime_EPS" SG_ 726 PA_Obj2_Angle 0;
BA_ "GenSigTimeoutTime_EVCU2" SG_ 726 PA_Obj2_Angle 0;
BA_ "GenSigTimeoutTime_ORC" SG_ 726 PA_Obj2_Angle 0;
BA_ "GenSigTimeoutTime_BSM" SG_ 726 PA_Obj2_Angle_2 0;
BA_ "GenSigTimeoutTime_BSM2" SG_ 726 PA_Obj2_Angle_2 0;
BA_ "GenSigTimeoutTime_CVPAM" SG_ 726 PA_Obj2_Angle_2 0;
BA_ "GenSigTimeoutTime_ECM" SG_ 726 PA_Obj2_Angle_2 0;
BA_ "GenSigTimeoutTime_EPS" SG_ 726 PA_Obj2_Angle_2 0;
BA_ "GenSigTimeoutTime_EVCU2" SG_ 726 PA_Obj2_Angle_2 0;
BA_ "GenSigTimeoutTime_ORC" SG_ 726 PA_Obj2_Angle_2 0;
BA_ "GenSigTimeoutTime_BSM" SG_ 726 PA_Obj2_Conf 0;
BA_ "GenSigTimeoutTime_BSM2" SG_ 726 PA_Obj2_Conf 0;
BA_ "GenSigTimeoutTime_CVPAM" SG_ 726 PA_Obj2_Conf 0;
BA_ "GenSigTimeoutTime_ECM" SG_ 726 PA_Obj2_Conf 0;
BA_ "GenSigTimeoutTime_EPS" SG_ 726 PA_Obj2_Conf 0;
BA_ "GenSigTimeoutTime_EVCU2" SG_ 726 PA_Obj2_Conf 0;
BA_ "GenSigTimeoutTime_ORC" SG_ 726 PA_Obj2_Conf 0;
BA_ "GenSigTimeoutTime_BSM" SG_ 726 PA_Obj2_Range 0;
BA_ "GenSigTimeoutTime_BSM2" SG_ 726 PA_Obj2_Range 0;
BA_ "GenSigTimeoutTime_CVPAM" SG_ 726 PA_Obj2_Range 0;
BA_ "GenSigTimeoutTime_ECM" SG_ 726 PA_Obj2_Range 0;
BA_ "GenSigTimeoutTime_EPS" SG_ 726 PA_Obj2_Range 0;
BA_ "GenSigTimeoutTime_EVCU2" SG_ 726 PA_Obj2_Range 0;
BA_ "GenSigTimeoutTime_ORC" SG_ 726 PA_Obj2_Range 0;
BA_ "GenSigTimeoutTime_BSM" SG_ 726 PA_Obj2_Range_2 0;
BA_ "GenSigTimeoutTime_BSM2" SG_ 726 PA_Obj2_Range_2 0;
BA_ "GenSigTimeoutTime_CVPAM" SG_ 726 PA_Obj2_Range_2 0;
BA_ "GenSigTimeoutTime_ECM" SG_ 726 PA_Obj2_Range_2 0;
BA_ "GenSigTimeoutTime_EPS" SG_ 726 PA_Obj2_Range_2 0;
BA_ "GenSigTimeoutTime_EVCU2" SG_ 726 PA_Obj2_Range_2 0;
BA_ "GenSigTimeoutTime_ORC" SG_ 726 PA_Obj2_Range_2 0;
BA_ "GenSigTimeoutTime_BSM" SG_ 726 PA_Obj2_Type 0;
BA_ "GenSigTimeoutTime_BSM2" SG_ 726 PA_Obj2_Type 0;
BA_ "GenSigTimeoutTime_CVPAM" SG_ 726 PA_Obj2_Type 0;
BA_ "GenSigTimeoutTime_ECM" SG_ 726 PA_Obj2_Type 0;
BA_ "GenSigTimeoutTime_EPS" SG_ 726 PA_Obj2_Type 0;
BA_ "GenSigTimeoutTime_EVCU2" SG_ 726 PA_Obj2_Type 0;
BA_ "GenSigTimeoutTime_ORC" SG_ 726 PA_Obj2_Type 0;
BA_ "GenSigTimeoutTime_BSM" SG_ 726 PA_Obj1_Angle 0;
BA_ "GenSigTimeoutTime_BSM2" SG_ 726 PA_Obj1_Angle 0;
BA_ "GenSigTimeoutTime_CVPAM" SG_ 726 PA_Obj1_Angle 0;
BA_ "GenSigTimeoutTime_ECM" SG_ 726 PA_Obj1_Angle 0;
BA_ "GenSigTimeoutTime_EPS" SG_ 726 PA_Obj1_Angle 0;
BA_ "GenSigTimeoutTime_EVCU2" SG_ 726 PA_Obj1_Angle 0;
BA_ "GenSigTimeoutTime_ORC" SG_ 726 PA_Obj1_Angle 0;
BA_ "GenSigTimeoutTime_BSM" SG_ 726 PA_Obj1_Angle_2 0;
BA_ "GenSigTimeoutTime_BSM2" SG_ 726 PA_Obj1_Angle_2 0;
BA_ "GenSigTimeoutTime_CVPAM" SG_ 726 PA_Obj1_Angle_2 0;
BA_ "GenSigTimeoutTime_ECM" SG_ 726 PA_Obj1_Angle_2 0;
BA_ "GenSigTimeoutTime_EPS" SG_ 726 PA_Obj1_Angle_2 0;
BA_ "GenSigTimeoutTime_EVCU2" SG_ 726 PA_Obj1_Angle_2 0;
BA_ "GenSigTimeoutTime_ORC" SG_ 726 PA_Obj1_Angle_2 0;
BA_ "GenSigTimeoutTime_BSM" SG_ 726 PA_Obj1_Conf 0;
BA_ "GenSigTimeoutTime_BSM2" SG_ 726 PA_Obj1_Conf 0;
BA_ "GenSigTimeoutTime_CVPAM" SG_ 726 PA_Obj1_Conf 0;
BA_ "GenSigTimeoutTime_ECM" SG_ 726 PA_Obj1_Conf 0;
BA_ "GenSigTimeoutTime_EPS" SG_ 726 PA_Obj1_Conf 0;
BA_ "GenSigTimeoutTime_EVCU2" SG_ 726 PA_Obj1_Conf 0;
BA_ "GenSigTimeoutTime_ORC" SG_ 726 PA_Obj1_Conf 0;
BA_ "GenSigTimeoutTime_BSM" SG_ 726 PA_Obj1_Range 0;
BA_ "GenSigTimeoutTime_BSM2" SG_ 726 PA_Obj1_Range 0;
BA_ "GenSigTimeoutTime_CVPAM" SG_ 726 PA_Obj1_Range 0;
BA_ "GenSigTimeoutTime_ECM" SG_ 726 PA_Obj1_Range 0;
BA_ "GenSigTimeoutTime_EPS" SG_ 726 PA_Obj1_Range 0;
BA_ "GenSigTimeoutTime_EVCU2" SG_ 726 PA_Obj1_Range 0;
BA_ "GenSigTimeoutTime_ORC" SG_ 726 PA_Obj1_Range 0;
BA_ "GenSigTimeoutTime_BSM" SG_ 726 PA_Obj1_Range_2 0;
BA_ "GenSigTimeoutTime_BSM2" SG_ 726 PA_Obj1_Range_2 0;
BA_ "GenSigTimeoutTime_CVPAM" SG_ 726 PA_Obj1_Range_2 0;
BA_ "GenSigTimeoutTime_ECM" SG_ 726 PA_Obj1_Range_2 0;
BA_ "GenSigTimeoutTime_EPS" SG_ 726 PA_Obj1_Range_2 0;
BA_ "GenSigTimeoutTime_EVCU2" SG_ 726 PA_Obj1_Range_2 0;
BA_ "GenSigTimeoutTime_ORC" SG_ 726 PA_Obj1_Range_2 0;
BA_ "GenSigTimeoutTime_BSM" SG_ 726 PA_Obj1_Type 0;
BA_ "GenSigTimeoutTime_BSM2" SG_ 726 PA_Obj1_Type 0;
BA_ "GenSigTimeoutTime_CVPAM" SG_ 726 PA_Obj1_Type 0;
BA_ "GenSigTimeoutTime_ECM" SG_ 726 PA_Obj1_Type 0;
BA_ "GenSigTimeoutTime_EPS" SG_ 726 PA_Obj1_Type 0;
BA_ "GenSigTimeoutTime_EVCU2" SG_ 726 PA_Obj1_Type 0;
BA_ "GenSigTimeoutTime_ORC" SG_ 726 PA_Obj1_Type 0;
BA_ "GenSigTimeoutTime_BSM" SG_ 726 Reserved_for_functional_safety_2D6 0;
BA_ "GenSigTimeoutTime_BSM2" SG_ 726 Reserved_for_functional_safety_2D6 0;
BA_ "GenSigTimeoutTime_CVPAM" SG_ 726 Reserved_for_functional_safety_2D6 0;
BA_ "GenSigTimeoutTime_ECM" SG_ 726 Reserved_for_functional_safety_2D6 0;
BA_ "GenSigTimeoutTime_EPS" SG_ 726 Reserved_for_functional_safety_2D6 0;
BA_ "GenSigTimeoutTime_EVCU2" SG_ 726 Reserved_for_functional_safety_2D6 0;
BA_ "GenSigTimeoutTime_ORC" SG_ 726 Reserved_for_functional_safety_2D6 0;
BA_ "GenSigTimeoutTime_BSM" SG_ 726 Cntr_CVPAM_FD_Data 0;
BA_ "GenSigTimeoutTime_BSM2" SG_ 726 Cntr_CVPAM_FD_Data 0;
BA_ "GenSigTimeoutTime_CVPAM" SG_ 726 Cntr_CVPAM_FD_Data 0;
BA_ "GenSigTimeoutTime_ECM" SG_ 726 Cntr_CVPAM_FD_Data 0;
BA_ "GenSigTimeoutTime_EPS" SG_ 726 Cntr_CVPAM_FD_Data 0;
BA_ "GenSigTimeoutTime_EVCU2" SG_ 726 Cntr_CVPAM_FD_Data 0;
BA_ "GenSigTimeoutTime_ORC" SG_ 726 Cntr_CVPAM_FD_Data 0;
BA_ "GenSigTimeoutTime_BSM" SG_ 726 CRC_CVPAM_FD_Data 0;
BA_ "GenSigTimeoutTime_BSM2" SG_ 726 CRC_CVPAM_FD_Data 0;
BA_ "GenSigTimeoutTime_CVPAM" SG_ 726 CRC_CVPAM_FD_Data 0;
BA_ "GenSigTimeoutTime_ECM" SG_ 726 CRC_CVPAM_FD_Data 0;
BA_ "GenSigTimeoutTime_EPS" SG_ 726 CRC_CVPAM_FD_Data 0;
BA_ "GenSigTimeoutTime_EVCU2" SG_ 726 CRC_CVPAM_FD_Data 0;
BA_ "GenSigTimeoutTime_ORC" SG_ 726 CRC_CVPAM_FD_Data 0;
BA_ "GenSigTimeoutTime_BSM" SG_ 726 MAC_CVPAM_FD_Data 0;
BA_ "GenSigTimeoutTime_BSM2" SG_ 726 MAC_CVPAM_FD_Data 0;
BA_ "GenSigTimeoutTime_CVPAM" SG_ 726 MAC_CVPAM_FD_Data 0;
BA_ "GenSigTimeoutTime_ECM" SG_ 726 MAC_CVPAM_FD_Data 0;
BA_ "GenSigTimeoutTime_EPS" SG_ 726 MAC_CVPAM_FD_Data 0;
BA_ "GenSigTimeoutTime_EVCU2" SG_ 726 MAC_CVPAM_FD_Data 0;
BA_ "GenSigTimeoutTime_ORC" SG_ 726 MAC_CVPAM_FD_Data 0;
BA_ "GenSigTimeoutTime_BSM" SG_ 726 MessageCounter_CVPAM_FD_Data 0;
BA_ "GenSigTimeoutTime_BSM2" SG_ 726 MessageCounter_CVPAM_FD_Data 0;
BA_ "GenSigTimeoutTime_CVPAM" SG_ 726 MessageCounter_CVPAM_FD_Data 0;
BA_ "GenSigTimeoutTime_ECM" SG_ 726 MessageCounter_CVPAM_FD_Data 0;
BA_ "GenSigTimeoutTime_EPS" SG_ 726 MessageCounter_CVPAM_FD_Data 0;
BA_ "GenSigTimeoutTime_EVCU2" SG_ 726 MessageCounter_CVPAM_FD_Data 0;
BA_ "GenSigTimeoutTime_ORC" SG_ 726 MessageCounter_CVPAM_FD_Data 0;
BA_ "GenSigTimeoutTime_BSM" SG_ 726 PA_Front_Sensor_Det_Health 0;
BA_ "GenSigTimeoutTime_BSM2" SG_ 726 PA_Front_Sensor_Det_Health 0;
BA_ "GenSigTimeoutTime_CVPAM" SG_ 726 PA_Front_Sensor_Det_Health 0;
BA_ "GenSigTimeoutTime_ECM" SG_ 726 PA_Front_Sensor_Det_Health 0;
BA_ "GenSigTimeoutTime_EPS" SG_ 726 PA_Front_Sensor_Det_Health 0;
BA_ "GenSigTimeoutTime_EVCU2" SG_ 726 PA_Front_Sensor_Det_Health 0;
BA_ "GenSigTimeoutTime_ORC" SG_ 726 PA_Front_Sensor_Det_Health 0;
BA_ "GenSigTimeoutTime_BSM" SG_ 726 PA_Obj6_Angle 0;
BA_ "GenSigTimeoutTime_BSM2" SG_ 726 PA_Obj6_Angle 0;
BA_ "GenSigTimeoutTime_CVPAM" SG_ 726 PA_Obj6_Angle 0;
BA_ "GenSigTimeoutTime_ECM" SG_ 726 PA_Obj6_Angle 0;
BA_ "GenSigTimeoutTime_EPS" SG_ 726 PA_Obj6_Angle 0;
BA_ "GenSigTimeoutTime_EVCU2" SG_ 726 PA_Obj6_Angle 0;
BA_ "GenSigTimeoutTime_ORC" SG_ 726 PA_Obj6_Angle 0;
BA_ "GenSigTimeoutTime_BSM" SG_ 726 PA_Obj6_Angle_2 0;
BA_ "GenSigTimeoutTime_BSM2" SG_ 726 PA_Obj6_Angle_2 0;
BA_ "GenSigTimeoutTime_CVPAM" SG_ 726 PA_Obj6_Angle_2 0;
BA_ "GenSigTimeoutTime_ECM" SG_ 726 PA_Obj6_Angle_2 0;
BA_ "GenSigTimeoutTime_EPS" SG_ 726 PA_Obj6_Angle_2 0;
BA_ "GenSigTimeoutTime_EVCU2" SG_ 726 PA_Obj6_Angle_2 0;
BA_ "GenSigTimeoutTime_ORC" SG_ 726 PA_Obj6_Angle_2 0;
BA_ "GenSigTimeoutTime_BSM" SG_ 726 PA_Obj6_Conf 0;
BA_ "GenSigTimeoutTime_BSM2" SG_ 726 PA_Obj6_Conf 0;
BA_ "GenSigTimeoutTime_CVPAM" SG_ 726 PA_Obj6_Conf 0;
BA_ "GenSigTimeoutTime_ECM" SG_ 726 PA_Obj6_Conf 0;
BA_ "GenSigTimeoutTime_EPS" SG_ 726 PA_Obj6_Conf 0;
BA_ "GenSigTimeoutTime_EVCU2" SG_ 726 PA_Obj6_Conf 0;
BA_ "GenSigTimeoutTime_ORC" SG_ 726 PA_Obj6_Conf 0;
BA_ "GenSigTimeoutTime_BSM" SG_ 726 PA_Obj6_Range 0;
BA_ "GenSigTimeoutTime_BSM2" SG_ 726 PA_Obj6_Range 0;
BA_ "GenSigTimeoutTime_CVPAM" SG_ 726 PA_Obj6_Range 0;
BA_ "GenSigTimeoutTime_ECM" SG_ 726 PA_Obj6_Range 0;
BA_ "GenSigTimeoutTime_EPS" SG_ 726 PA_Obj6_Range 0;
BA_ "GenSigTimeoutTime_EVCU2" SG_ 726 PA_Obj6_Range 0;
BA_ "GenSigTimeoutTime_ORC" SG_ 726 PA_Obj6_Range 0;
BA_ "GenSigTimeoutTime_BSM" SG_ 726 PA_Obj6_Range_2 0;
BA_ "GenSigTimeoutTime_BSM2" SG_ 726 PA_Obj6_Range_2 0;
BA_ "GenSigTimeoutTime_CVPAM" SG_ 726 PA_Obj6_Range_2 0;
BA_ "GenSigTimeoutTime_ECM" SG_ 726 PA_Obj6_Range_2 0;
BA_ "GenSigTimeoutTime_EPS" SG_ 726 PA_Obj6_Range_2 0;
BA_ "GenSigTimeoutTime_EVCU2" SG_ 726 PA_Obj6_Range_2 0;
BA_ "GenSigTimeoutTime_ORC" SG_ 726 PA_Obj6_Range_2 0;
BA_ "GenSigTimeoutTime_BSM" SG_ 726 PA_Obj6_Type 0;
BA_ "GenSigTimeoutTime_BSM2" SG_ 726 PA_Obj6_Type 0;
BA_ "GenSigTimeoutTime_CVPAM" SG_ 726 PA_Obj6_Type 0;
BA_ "GenSigTimeoutTime_ECM" SG_ 726 PA_Obj6_Type 0;
BA_ "GenSigTimeoutTime_EPS" SG_ 726 PA_Obj6_Type 0;
BA_ "GenSigTimeoutTime_EVCU2" SG_ 726 PA_Obj6_Type 0;
BA_ "GenSigTimeoutTime_ORC" SG_ 726 PA_Obj6_Type 0;
BA_ "GenSigTimeoutTime_ADCAM" SG_ 727 PA_Line_RM_Color 0;
BA_ "GenSigTimeoutTime_CVADAS" SG_ 727 PA_Line_RM_Color 0;
BA_ "GenSigTimeoutTime_ADCAM" SG_ 727 PA_Line_RM_Heading 0;
BA_ "GenSigTimeoutTime_CVADAS" SG_ 727 PA_Line_RM_Heading 0;
BA_ "GenSigTimeoutTime_ADCAM" SG_ 727 PA_Line_RM_Style 0;
BA_ "GenSigTimeoutTime_CVADAS" SG_ 727 PA_Line_RM_Style 0;
BA_ "GenSigTimeoutTime_ADCAM" SG_ 727 PA_Right_Sensor_Det_Health 0;
BA_ "GenSigTimeoutTime_CVADAS" SG_ 727 PA_Right_Sensor_Det_Health 0;
BA_ "GenSigTimeoutTime_ADCAM" SG_ 727 PA_SideSensor_FrontLeft_Conf 0;
BA_ "GenSigTimeoutTime_CVADAS" SG_ 727 PA_SideSensor_FrontLeft_Conf 0;
BA_ "GenSigTimeoutTime_ADCAM" SG_ 727 PA_SideSensor_FrontLeft_Dist 0;
BA_ "GenSigTimeoutTime_CVADAS" SG_ 727 PA_SideSensor_FrontLeft_Dist 0;
BA_ "GenSigTimeoutTime_ADCAM" SG_ 727 MessageCounter_CVPAM_FD_Data2 0;
BA_ "GenSigTimeoutTime_CVADAS" SG_ 727 MessageCounter_CVPAM_FD_Data2 0;
BA_ "GenSigTimeoutTime_ADCAM" SG_ 727 PA_Lane_Dection_Health 0;
BA_ "GenSigTimeoutTime_CVADAS" SG_ 727 PA_Lane_Dection_Health 0;
BA_ "GenSigTimeoutTime_ADCAM" SG_ 727 PA_Left_Sensor_Det_Health 0;
BA_ "GenSigTimeoutTime_CVADAS" SG_ 727 PA_Left_Sensor_Det_Health 0;
BA_ "GenSigTimeoutTime_ADCAM" SG_ 727 PA_Line_LM_Color 0;
BA_ "GenSigTimeoutTime_CVADAS" SG_ 727 PA_Line_LM_Color 0;
BA_ "GenSigTimeoutTime_ADCAM" SG_ 727 PA_Line_LM_Heading 0;
BA_ "GenSigTimeoutTime_CVADAS" SG_ 727 PA_Line_LM_Heading 0;
BA_ "GenSigTimeoutTime_ADCAM" SG_ 727 PA_Line_LM_Style 0;
BA_ "GenSigTimeoutTime_CVADAS" SG_ 727 PA_Line_LM_Style 0;
BA_ "GenSigTimeoutTime_ADCAM" SG_ 727 PA_Line_RM_Distance 0;
BA_ "GenSigTimeoutTime_CVADAS" SG_ 727 PA_Line_RM_Distance 0;
BA_ "GenSigTimeoutTime_ADCAM" SG_ 727 PA_Line_RM_Distance_Conf 0;
BA_ "GenSigTimeoutTime_CVADAS" SG_ 727 PA_Line_RM_Distance_Conf 0;
BA_ "GenSigTimeoutTime_ADCAM" SG_ 727 PA_Line_RM_Heading_Conf 0;
BA_ "GenSigTimeoutTime_CVADAS" SG_ 727 PA_Line_RM_Heading_Conf 0;
BA_ "GenSigTimeoutTime_ADCAM" SG_ 727 Cntr_CVPAM_FD_Data2 0;
BA_ "GenSigTimeoutTime_CVADAS" SG_ 727 Cntr_CVPAM_FD_Data2 0;
BA_ "GenSigTimeoutTime_ADCAM" SG_ 727 CRC_CVPAM_FD_Data2 0;
BA_ "GenSigTimeoutTime_CVADAS" SG_ 727 CRC_CVPAM_FD_Data2 0;
BA_ "GenSigTimeoutTime_ADCAM" SG_ 727 MAC_CVPAM_FD_Data2 0;
BA_ "GenSigTimeoutTime_CVADAS" SG_ 727 MAC_CVPAM_FD_Data2 0;
BA_ "GenSigTimeoutTime_ADCAM" SG_ 727 Reserved_for_Functional_Safety_ 0;
BA_ "GenSigTimeoutTime_CVADAS" SG_ 727 Reserved_for_Functional_Safety_ 0;
BA_ "GenSigTimeoutTime_ADCAM" SG_ 727 PA_Line_LM_Distance 0;
BA_ "GenSigTimeoutTime_CVADAS" SG_ 727 PA_Line_LM_Distance 0;
BA_ "GenSigTimeoutTime_ADCAM" SG_ 727 PA_Line_LM_Distance_Conf 0;
BA_ "GenSigTimeoutTime_CVADAS" SG_ 727 PA_Line_LM_Distance_Conf 0;
BA_ "GenSigTimeoutTime_ADCAM" SG_ 727 PA_Line_LM_Heading_Conf 0;
BA_ "GenSigTimeoutTime_CVADAS" SG_ 727 PA_Line_LM_Heading_Conf 0;
BA_ "GenSigTimeoutTime_ADCAM" SG_ 727 PA_SideSensor_FrontRight_Conf 0;
BA_ "GenSigTimeoutTime_CVADAS" SG_ 727 PA_SideSensor_FrontRight_Conf 0;
BA_ "GenSigTimeoutTime_ADCAM" SG_ 727 PA_SideSensor_FrontRight_Dist 0;
BA_ "GenSigTimeoutTime_CVADAS" SG_ 727 PA_SideSensor_FrontRight_Dist 0;
BA_ "GenSigTimeoutTime_ADCAM" SG_ 727 PA_SideSensor_RearLeft_Conf 0;
BA_ "GenSigTimeoutTime_CVADAS" SG_ 727 PA_SideSensor_RearLeft_Conf 0;
BA_ "GenSigTimeoutTime_ADCAM" SG_ 727 PA_SideSensor_RearLeft_Dist 0;
BA_ "GenSigTimeoutTime_CVADAS" SG_ 727 PA_SideSensor_RearLeft_Dist 0;
BA_ "GenSigTimeoutTime_ADCAM" SG_ 727 PA_SideSensor_RearRight_Conf 0;
BA_ "GenSigTimeoutTime_CVADAS" SG_ 727 PA_SideSensor_RearRight_Conf 0;
BA_ "GenSigTimeoutTime_ADCAM" SG_ 727 PA_SideSensor_RearRight_Dist 0;
BA_ "GenSigTimeoutTime_CVADAS" SG_ 727 PA_SideSensor_RearRight_Dist 0;
BA_ "GenSigTimeoutTime_BSM" SG_ 727 PA_Line_RM_Color 0;
BA_ "GenSigTimeoutTime_BSM2" SG_ 727 PA_Line_RM_Color 0;
BA_ "GenSigTimeoutTime_CVPAM" SG_ 727 PA_Line_RM_Color 0;
BA_ "GenSigTimeoutTime_ECM" SG_ 727 PA_Line_RM_Color 0;
BA_ "GenSigTimeoutTime_EPS" SG_ 727 PA_Line_RM_Color 0;
BA_ "GenSigTimeoutTime_EVCU2" SG_ 727 PA_Line_RM_Color 0;
BA_ "GenSigTimeoutTime_ORC" SG_ 727 PA_Line_RM_Color 0;
BA_ "GenSigTimeoutTime_BSM" SG_ 727 PA_Line_RM_Heading 0;
BA_ "GenSigTimeoutTime_BSM2" SG_ 727 PA_Line_RM_Heading 0;
BA_ "GenSigTimeoutTime_CVPAM" SG_ 727 PA_Line_RM_Heading 0;
BA_ "GenSigTimeoutTime_ECM" SG_ 727 PA_Line_RM_Heading 0;
BA_ "GenSigTimeoutTime_EPS" SG_ 727 PA_Line_RM_Heading 0;
BA_ "GenSigTimeoutTime_EVCU2" SG_ 727 PA_Line_RM_Heading 0;
BA_ "GenSigTimeoutTime_ORC" SG_ 727 PA_Line_RM_Heading 0;
BA_ "GenSigTimeoutTime_BSM" SG_ 727 PA_Line_RM_Style 0;
BA_ "GenSigTimeoutTime_BSM2" SG_ 727 PA_Line_RM_Style 0;
BA_ "GenSigTimeoutTime_CVPAM" SG_ 727 PA_Line_RM_Style 0;
BA_ "GenSigTimeoutTime_ECM" SG_ 727 PA_Line_RM_Style 0;
BA_ "GenSigTimeoutTime_EPS" SG_ 727 PA_Line_RM_Style 0;
BA_ "GenSigTimeoutTime_EVCU2" SG_ 727 PA_Line_RM_Style 0;
BA_ "GenSigTimeoutTime_ORC" SG_ 727 PA_Line_RM_Style 0;
BA_ "GenSigTimeoutTime_BSM" SG_ 727 PA_Right_Sensor_Det_Health 0;
BA_ "GenSigTimeoutTime_BSM2" SG_ 727 PA_Right_Sensor_Det_Health 0;
BA_ "GenSigTimeoutTime_CVPAM" SG_ 727 PA_Right_Sensor_Det_Health 0;
BA_ "GenSigTimeoutTime_ECM" SG_ 727 PA_Right_Sensor_Det_Health 0;
BA_ "GenSigTimeoutTime_EPS" SG_ 727 PA_Right_Sensor_Det_Health 0;
BA_ "GenSigTimeoutTime_EVCU2" SG_ 727 PA_Right_Sensor_Det_Health 0;
BA_ "GenSigTimeoutTime_ORC" SG_ 727 PA_Right_Sensor_Det_Health 0;
BA_ "GenSigTimeoutTime_BSM" SG_ 727 PA_SideSensor_FrontLeft_Conf 0;
BA_ "GenSigTimeoutTime_BSM2" SG_ 727 PA_SideSensor_FrontLeft_Conf 0;
BA_ "GenSigTimeoutTime_CVPAM" SG_ 727 PA_SideSensor_FrontLeft_Conf 0;
BA_ "GenSigTimeoutTime_ECM" SG_ 727 PA_SideSensor_FrontLeft_Conf 0;
BA_ "GenSigTimeoutTime_EPS" SG_ 727 PA_SideSensor_FrontLeft_Conf 0;
BA_ "GenSigTimeoutTime_EVCU2" SG_ 727 PA_SideSensor_FrontLeft_Conf 0;
BA_ "GenSigTimeoutTime_ORC" SG_ 727 PA_SideSensor_FrontLeft_Conf 0;
BA_ "GenSigStartValue" SG_ 727 PA_SideSensor_FrontLeft_Dist 1023;
BA_ "GenSigTimeoutTime_BSM" SG_ 727 PA_SideSensor_FrontLeft_Dist 0;
BA_ "GenSigTimeoutTime_BSM2" SG_ 727 PA_SideSensor_FrontLeft_Dist 0;
BA_ "GenSigTimeoutTime_CVPAM" SG_ 727 PA_SideSensor_FrontLeft_Dist 0;
BA_ "GenSigTimeoutTime_ECM" SG_ 727 PA_SideSensor_FrontLeft_Dist 0;
BA_ "GenSigTimeoutTime_EPS" SG_ 727 PA_SideSensor_FrontLeft_Dist 0;
BA_ "GenSigTimeoutTime_EVCU2" SG_ 727 PA_SideSensor_FrontLeft_Dist 0;
BA_ "GenSigTimeoutTime_ORC" SG_ 727 PA_SideSensor_FrontLeft_Dist 0;
BA_ "GenSigTimeoutTime_BSM" SG_ 727 MessageCounter_CVPAM_FD_Data2 0;
BA_ "GenSigTimeoutTime_BSM2" SG_ 727 MessageCounter_CVPAM_FD_Data2 0;
BA_ "GenSigTimeoutTime_CVPAM" SG_ 727 MessageCounter_CVPAM_FD_Data2 0;
BA_ "GenSigTimeoutTime_ECM" SG_ 727 MessageCounter_CVPAM_FD_Data2 0;
BA_ "GenSigTimeoutTime_EPS" SG_ 727 MessageCounter_CVPAM_FD_Data2 0;
BA_ "GenSigTimeoutTime_EVCU2" SG_ 727 MessageCounter_CVPAM_FD_Data2 0;
BA_ "GenSigTimeoutTime_ORC" SG_ 727 MessageCounter_CVPAM_FD_Data2 0;
BA_ "GenSigTimeoutTime_BSM" SG_ 727 PA_Lane_Dection_Health 0;
BA_ "GenSigTimeoutTime_BSM2" SG_ 727 PA_Lane_Dection_Health 0;
BA_ "GenSigTimeoutTime_CVPAM" SG_ 727 PA_Lane_Dection_Health 0;
BA_ "GenSigTimeoutTime_ECM" SG_ 727 PA_Lane_Dection_Health 0;
BA_ "GenSigTimeoutTime_EPS" SG_ 727 PA_Lane_Dection_Health 0;
BA_ "GenSigTimeoutTime_EVCU2" SG_ 727 PA_Lane_Dection_Health 0;
BA_ "GenSigTimeoutTime_ORC" SG_ 727 PA_Lane_Dection_Health 0;
BA_ "GenSigTimeoutTime_BSM" SG_ 727 PA_Left_Sensor_Det_Health 0;
BA_ "GenSigTimeoutTime_BSM2" SG_ 727 PA_Left_Sensor_Det_Health 0;
BA_ "GenSigTimeoutTime_CVPAM" SG_ 727 PA_Left_Sensor_Det_Health 0;
BA_ "GenSigTimeoutTime_ECM" SG_ 727 PA_Left_Sensor_Det_Health 0;
BA_ "GenSigTimeoutTime_EPS" SG_ 727 PA_Left_Sensor_Det_Health 0;
BA_ "GenSigTimeoutTime_EVCU2" SG_ 727 PA_Left_Sensor_Det_Health 0;
BA_ "GenSigTimeoutTime_ORC" SG_ 727 PA_Left_Sensor_Det_Health 0;
BA_ "GenSigTimeoutTime_BSM" SG_ 727 PA_Line_LM_Color 0;
BA_ "GenSigTimeoutTime_BSM2" SG_ 727 PA_Line_LM_Color 0;
BA_ "GenSigTimeoutTime_CVPAM" SG_ 727 PA_Line_LM_Color 0;
BA_ "GenSigTimeoutTime_ECM" SG_ 727 PA_Line_LM_Color 0;
BA_ "GenSigTimeoutTime_EPS" SG_ 727 PA_Line_LM_Color 0;
BA_ "GenSigTimeoutTime_EVCU2" SG_ 727 PA_Line_LM_Color 0;
BA_ "GenSigTimeoutTime_ORC" SG_ 727 PA_Line_LM_Color 0;
BA_ "GenSigTimeoutTime_BSM" SG_ 727 PA_Line_LM_Heading 0;
BA_ "GenSigTimeoutTime_BSM2" SG_ 727 PA_Line_LM_Heading 0;
BA_ "GenSigTimeoutTime_CVPAM" SG_ 727 PA_Line_LM_Heading 0;
BA_ "GenSigTimeoutTime_ECM" SG_ 727 PA_Line_LM_Heading 0;
BA_ "GenSigTimeoutTime_EPS" SG_ 727 PA_Line_LM_Heading 0;
BA_ "GenSigTimeoutTime_EVCU2" SG_ 727 PA_Line_LM_Heading 0;
BA_ "GenSigTimeoutTime_ORC" SG_ 727 PA_Line_LM_Heading 0;
BA_ "GenSigTimeoutTime_BSM" SG_ 727 PA_Line_LM_Style 0;
BA_ "GenSigTimeoutTime_BSM2" SG_ 727 PA_Line_LM_Style 0;
BA_ "GenSigTimeoutTime_CVPAM" SG_ 727 PA_Line_LM_Style 0;
BA_ "GenSigTimeoutTime_ECM" SG_ 727 PA_Line_LM_Style 0;
BA_ "GenSigTimeoutTime_EPS" SG_ 727 PA_Line_LM_Style 0;
BA_ "GenSigTimeoutTime_EVCU2" SG_ 727 PA_Line_LM_Style 0;
BA_ "GenSigTimeoutTime_ORC" SG_ 727 PA_Line_LM_Style 0;
BA_ "GenSigTimeoutTime_BSM" SG_ 727 PA_Line_RM_Distance 0;
BA_ "GenSigTimeoutTime_BSM2" SG_ 727 PA_Line_RM_Distance 0;
BA_ "GenSigTimeoutTime_CVPAM" SG_ 727 PA_Line_RM_Distance 0;
BA_ "GenSigTimeoutTime_ECM" SG_ 727 PA_Line_RM_Distance 0;
BA_ "GenSigTimeoutTime_EPS" SG_ 727 PA_Line_RM_Distance 0;
BA_ "GenSigTimeoutTime_EVCU2" SG_ 727 PA_Line_RM_Distance 0;
BA_ "GenSigTimeoutTime_ORC" SG_ 727 PA_Line_RM_Distance 0;
BA_ "GenSigTimeoutTime_BSM" SG_ 727 PA_Line_RM_Distance_Conf 0;
BA_ "GenSigTimeoutTime_BSM2" SG_ 727 PA_Line_RM_Distance_Conf 0;
BA_ "GenSigTimeoutTime_CVPAM" SG_ 727 PA_Line_RM_Distance_Conf 0;
BA_ "GenSigTimeoutTime_ECM" SG_ 727 PA_Line_RM_Distance_Conf 0;
BA_ "GenSigTimeoutTime_EPS" SG_ 727 PA_Line_RM_Distance_Conf 0;
BA_ "GenSigTimeoutTime_EVCU2" SG_ 727 PA_Line_RM_Distance_Conf 0;
BA_ "GenSigTimeoutTime_ORC" SG_ 727 PA_Line_RM_Distance_Conf 0;
BA_ "GenSigTimeoutTime_BSM" SG_ 727 PA_Line_RM_Heading_Conf 0;
BA_ "GenSigTimeoutTime_BSM2" SG_ 727 PA_Line_RM_Heading_Conf 0;
BA_ "GenSigTimeoutTime_CVPAM" SG_ 727 PA_Line_RM_Heading_Conf 0;
BA_ "GenSigTimeoutTime_ECM" SG_ 727 PA_Line_RM_Heading_Conf 0;
BA_ "GenSigTimeoutTime_EPS" SG_ 727 PA_Line_RM_Heading_Conf 0;
BA_ "GenSigTimeoutTime_EVCU2" SG_ 727 PA_Line_RM_Heading_Conf 0;
BA_ "GenSigTimeoutTime_ORC" SG_ 727 PA_Line_RM_Heading_Conf 0;
BA_ "GenSigTimeoutTime_BSM" SG_ 727 Cntr_CVPAM_FD_Data2 0;
BA_ "GenSigTimeoutTime_BSM2" SG_ 727 Cntr_CVPAM_FD_Data2 0;
BA_ "GenSigTimeoutTime_CVPAM" SG_ 727 Cntr_CVPAM_FD_Data2 0;
BA_ "GenSigTimeoutTime_ECM" SG_ 727 Cntr_CVPAM_FD_Data2 0;
BA_ "GenSigTimeoutTime_EPS" SG_ 727 Cntr_CVPAM_FD_Data2 0;
BA_ "GenSigTimeoutTime_EVCU2" SG_ 727 Cntr_CVPAM_FD_Data2 0;
BA_ "GenSigTimeoutTime_ORC" SG_ 727 Cntr_CVPAM_FD_Data2 0;
BA_ "GenSigTimeoutTime_BSM" SG_ 727 CRC_CVPAM_FD_Data2 0;
BA_ "GenSigTimeoutTime_BSM2" SG_ 727 CRC_CVPAM_FD_Data2 0;
BA_ "GenSigTimeoutTime_CVPAM" SG_ 727 CRC_CVPAM_FD_Data2 0;
BA_ "GenSigTimeoutTime_ECM" SG_ 727 CRC_CVPAM_FD_Data2 0;
BA_ "GenSigTimeoutTime_EPS" SG_ 727 CRC_CVPAM_FD_Data2 0;
BA_ "GenSigTimeoutTime_EVCU2" SG_ 727 CRC_CVPAM_FD_Data2 0;
BA_ "GenSigTimeoutTime_ORC" SG_ 727 CRC_CVPAM_FD_Data2 0;
BA_ "GenSigTimeoutTime_BSM" SG_ 727 MAC_CVPAM_FD_Data2 0;
BA_ "GenSigTimeoutTime_BSM2" SG_ 727 MAC_CVPAM_FD_Data2 0;
BA_ "GenSigTimeoutTime_CVPAM" SG_ 727 MAC_CVPAM_FD_Data2 0;
BA_ "GenSigTimeoutTime_ECM" SG_ 727 MAC_CVPAM_FD_Data2 0;
BA_ "GenSigTimeoutTime_EPS" SG_ 727 MAC_CVPAM_FD_Data2 0;
BA_ "GenSigTimeoutTime_EVCU2" SG_ 727 MAC_CVPAM_FD_Data2 0;
BA_ "GenSigTimeoutTime_ORC" SG_ 727 MAC_CVPAM_FD_Data2 0;
BA_ "SystemSignalLongSymbol" SG_ 727 Reserved_for_Functional_Safety_ "Reserved_for_Functional_Safety_CRC";
BA_ "GenSigTimeoutTime_BSM" SG_ 727 Reserved_for_Functional_Safety_ 0;
BA_ "GenSigTimeoutTime_BSM2" SG_ 727 Reserved_for_Functional_Safety_ 0;
BA_ "GenSigTimeoutTime_CVPAM" SG_ 727 Reserved_for_Functional_Safety_ 0;
BA_ "GenSigTimeoutTime_ECM" SG_ 727 Reserved_for_Functional_Safety_ 0;
BA_ "GenSigTimeoutTime_EPS" SG_ 727 Reserved_for_Functional_Safety_ 0;
BA_ "GenSigTimeoutTime_EVCU2" SG_ 727 Reserved_for_Functional_Safety_ 0;
BA_ "GenSigTimeoutTime_ORC" SG_ 727 Reserved_for_Functional_Safety_ 0;
BA_ "GenSigTimeoutTime_BSM" SG_ 727 PA_Line_LM_Distance 0;
BA_ "GenSigTimeoutTime_BSM2" SG_ 727 PA_Line_LM_Distance 0;
BA_ "GenSigTimeoutTime_CVPAM" SG_ 727 PA_Line_LM_Distance 0;
BA_ "GenSigTimeoutTime_ECM" SG_ 727 PA_Line_LM_Distance 0;
BA_ "GenSigTimeoutTime_EPS" SG_ 727 PA_Line_LM_Distance 0;
BA_ "GenSigTimeoutTime_EVCU2" SG_ 727 PA_Line_LM_Distance 0;
BA_ "GenSigTimeoutTime_ORC" SG_ 727 PA_Line_LM_Distance 0;
BA_ "GenSigTimeoutTime_BSM" SG_ 727 PA_Line_LM_Distance_Conf 0;
BA_ "GenSigTimeoutTime_BSM2" SG_ 727 PA_Line_LM_Distance_Conf 0;
BA_ "GenSigTimeoutTime_CVPAM" SG_ 727 PA_Line_LM_Distance_Conf 0;
BA_ "GenSigTimeoutTime_ECM" SG_ 727 PA_Line_LM_Distance_Conf 0;
BA_ "GenSigTimeoutTime_EPS" SG_ 727 PA_Line_LM_Distance_Conf 0;
BA_ "GenSigTimeoutTime_EVCU2" SG_ 727 PA_Line_LM_Distance_Conf 0;
BA_ "GenSigTimeoutTime_ORC" SG_ 727 PA_Line_LM_Distance_Conf 0;
BA_ "GenSigTimeoutTime_BSM" SG_ 727 PA_Line_LM_Heading_Conf 0;
BA_ "GenSigTimeoutTime_BSM2" SG_ 727 PA_Line_LM_Heading_Conf 0;
BA_ "GenSigTimeoutTime_CVPAM" SG_ 727 PA_Line_LM_Heading_Conf 0;
BA_ "GenSigTimeoutTime_ECM" SG_ 727 PA_Line_LM_Heading_Conf 0;
BA_ "GenSigTimeoutTime_EPS" SG_ 727 PA_Line_LM_Heading_Conf 0;
BA_ "GenSigTimeoutTime_EVCU2" SG_ 727 PA_Line_LM_Heading_Conf 0;
BA_ "GenSigTimeoutTime_ORC" SG_ 727 PA_Line_LM_Heading_Conf 0;
BA_ "GenSigTimeoutTime_BSM" SG_ 727 PA_SideSensor_FrontRight_Conf 0;
BA_ "GenSigTimeoutTime_BSM2" SG_ 727 PA_SideSensor_FrontRight_Conf 0;
BA_ "GenSigTimeoutTime_CVPAM" SG_ 727 PA_SideSensor_FrontRight_Conf 0;
BA_ "GenSigTimeoutTime_ECM" SG_ 727 PA_SideSensor_FrontRight_Conf 0;
BA_ "GenSigTimeoutTime_EPS" SG_ 727 PA_SideSensor_FrontRight_Conf 0;
BA_ "GenSigTimeoutTime_EVCU2" SG_ 727 PA_SideSensor_FrontRight_Conf 0;
BA_ "GenSigTimeoutTime_ORC" SG_ 727 PA_SideSensor_FrontRight_Conf 0;
BA_ "GenSigStartValue" SG_ 727 PA_SideSensor_FrontRight_Dist 1023;
BA_ "GenSigTimeoutTime_BSM" SG_ 727 PA_SideSensor_FrontRight_Dist 0;
BA_ "GenSigTimeoutTime_BSM2" SG_ 727 PA_SideSensor_FrontRight_Dist 0;
BA_ "GenSigTimeoutTime_CVPAM" SG_ 727 PA_SideSensor_FrontRight_Dist 0;
BA_ "GenSigTimeoutTime_ECM" SG_ 727 PA_SideSensor_FrontRight_Dist 0;
BA_ "GenSigTimeoutTime_EPS" SG_ 727 PA_SideSensor_FrontRight_Dist 0;
BA_ "GenSigTimeoutTime_EVCU2" SG_ 727 PA_SideSensor_FrontRight_Dist 0;
BA_ "GenSigTimeoutTime_ORC" SG_ 727 PA_SideSensor_FrontRight_Dist 0;
BA_ "GenSigTimeoutTime_BSM" SG_ 727 PA_SideSensor_RearLeft_Conf 0;
BA_ "GenSigTimeoutTime_BSM2" SG_ 727 PA_SideSensor_RearLeft_Conf 0;
BA_ "GenSigTimeoutTime_CVPAM" SG_ 727 PA_SideSensor_RearLeft_Conf 0;
BA_ "GenSigTimeoutTime_ECM" SG_ 727 PA_SideSensor_RearLeft_Conf 0;
BA_ "GenSigTimeoutTime_EPS" SG_ 727 PA_SideSensor_RearLeft_Conf 0;
BA_ "GenSigTimeoutTime_EVCU2" SG_ 727 PA_SideSensor_RearLeft_Conf 0;
BA_ "GenSigTimeoutTime_ORC" SG_ 727 PA_SideSensor_RearLeft_Conf 0;
BA_ "GenSigStartValue" SG_ 727 PA_SideSensor_RearLeft_Dist 1023;
BA_ "GenSigTimeoutTime_BSM" SG_ 727 PA_SideSensor_RearLeft_Dist 0;
BA_ "GenSigTimeoutTime_BSM2" SG_ 727 PA_SideSensor_RearLeft_Dist 0;
BA_ "GenSigTimeoutTime_CVPAM" SG_ 727 PA_SideSensor_RearLeft_Dist 0;
BA_ "GenSigTimeoutTime_ECM" SG_ 727 PA_SideSensor_RearLeft_Dist 0;
BA_ "GenSigTimeoutTime_EPS" SG_ 727 PA_SideSensor_RearLeft_Dist 0;
BA_ "GenSigTimeoutTime_EVCU2" SG_ 727 PA_SideSensor_RearLeft_Dist 0;
BA_ "GenSigTimeoutTime_ORC" SG_ 727 PA_SideSensor_RearLeft_Dist 0;
BA_ "GenSigTimeoutTime_BSM" SG_ 727 PA_SideSensor_RearRight_Conf 0;
BA_ "GenSigTimeoutTime_BSM2" SG_ 727 PA_SideSensor_RearRight_Conf 0;
BA_ "GenSigTimeoutTime_CVPAM" SG_ 727 PA_SideSensor_RearRight_Conf 0;
BA_ "GenSigTimeoutTime_ECM" SG_ 727 PA_SideSensor_RearRight_Conf 0;
BA_ "GenSigTimeoutTime_EPS" SG_ 727 PA_SideSensor_RearRight_Conf 0;
BA_ "GenSigTimeoutTime_EVCU2" SG_ 727 PA_SideSensor_RearRight_Conf 0;
BA_ "GenSigTimeoutTime_ORC" SG_ 727 PA_SideSensor_RearRight_Conf 0;
BA_ "GenSigStartValue" SG_ 727 PA_SideSensor_RearRight_Dist 1023;
BA_ "GenSigTimeoutTime_BSM" SG_ 727 PA_SideSensor_RearRight_Dist 0;
BA_ "GenSigTimeoutTime_BSM2" SG_ 727 PA_SideSensor_RearRight_Dist 0;
BA_ "GenSigTimeoutTime_CVPAM" SG_ 727 PA_SideSensor_RearRight_Dist 0;
BA_ "GenSigTimeoutTime_ECM" SG_ 727 PA_SideSensor_RearRight_Dist 0;
BA_ "GenSigTimeoutTime_EPS" SG_ 727 PA_SideSensor_RearRight_Dist 0;
BA_ "GenSigTimeoutTime_EVCU2" SG_ 727 PA_SideSensor_RearRight_Dist 0;
BA_ "GenSigTimeoutTime_ORC" SG_ 727 PA_SideSensor_RearRight_Dist 0;
BA_ "GenSigTimeoutTime_MPAD" SG_ 2654486552 CBV_bit0_RepeatMessageRequestBit_1E384018 0;
BA_ "GenSigTimeoutTime_ADCAM" SG_ 2654486552 CBV_bit0_RepeatMessageRequestBit_1E384018 0;
BA_ "GenSigTimeoutTime_CVADAS" SG_ 2654486552 CBV_bit0_RepeatMessageRequestBit_1E384018 0;
BA_ "GenSigTimeoutTime_MPAD" SG_ 2654486552 CBV_bit1_1E384018 0;
BA_ "GenSigTimeoutTime_ADCAM" SG_ 2654486552 CBV_bit1_1E384018 0;
BA_ "GenSigTimeoutTime_CVADAS" SG_ 2654486552 CBV_bit1_1E384018 0;
BA_ "GenSigTimeoutTime_MPAD" SG_ 2654486552 CBV_bit2_1E384018 0;
BA_ "GenSigTimeoutTime_ADCAM" SG_ 2654486552 CBV_bit2_1E384018 0;
BA_ "GenSigTimeoutTime_CVADAS" SG_ 2654486552 CBV_bit2_1E384018 0;
BA_ "GenSigTimeoutTime_MPAD" SG_ 2654486552 CBV_bit3_NMCoordinatorBit_1E384018 0;
BA_ "GenSigTimeoutTime_ADCAM" SG_ 2654486552 CBV_bit3_NMCoordinatorBit_1E384018 0;
BA_ "GenSigTimeoutTime_CVADAS" SG_ 2654486552 CBV_bit3_NMCoordinatorBit_1E384018 0;
BA_ "GenSigTimeoutTime_MPAD" SG_ 2654486552 CBV_bit4_ActiveWakeupBit_1E384018 0;
BA_ "GenSigTimeoutTime_ADCAM" SG_ 2654486552 CBV_bit4_ActiveWakeupBit_1E384018 0;
BA_ "GenSigTimeoutTime_CVADAS" SG_ 2654486552 CBV_bit4_ActiveWakeupBit_1E384018 0;
BA_ "GenSigTimeoutTime_MPAD" SG_ 2654486552 CBV_bit5_1E384018 0;
BA_ "GenSigTimeoutTime_ADCAM" SG_ 2654486552 CBV_bit5_1E384018 0;
BA_ "GenSigTimeoutTime_CVADAS" SG_ 2654486552 CBV_bit5_1E384018 0;
BA_ "GenSigTimeoutTime_MPAD" SG_ 2654486552 CBV_bit6_PartialNtwInfBit_1E384018 0;
BA_ "GenSigTimeoutTime_ADCAM" SG_ 2654486552 CBV_bit6_PartialNtwInfBit_1E384018 0;
BA_ "GenSigTimeoutTime_CVADAS" SG_ 2654486552 CBV_bit6_PartialNtwInfBit_1E384018 0;
BA_ "GenSigTimeoutTime_MPAD" SG_ 2654486552 CBV_bit7_1E384018 0;
BA_ "GenSigTimeoutTime_ADCAM" SG_ 2654486552 CBV_bit7_1E384018 0;
BA_ "GenSigTimeoutTime_CVADAS" SG_ 2654486552 CBV_bit7_1E384018 0;
BA_ "GenSigTimeoutTime_MPAD" SG_ 2654486552 SourceNodeIdentifier_1E384018 0;
BA_ "GenSigTimeoutTime_ADCAM" SG_ 2654486552 SourceNodeIdentifier_1E384018 0;
BA_ "GenSigTimeoutTime_CVADAS" SG_ 2654486552 SourceNodeIdentifier_1E384018 0;
BA_ "GenSigTimeoutTime_BSM" SG_ 2654486552 CBV_bit0_RepeatMessageRequestBit_1E384018 0;
BA_ "GenSigTimeoutTime_BSM2" SG_ 2654486552 CBV_bit0_RepeatMessageRequestBit_1E384018 0;
BA_ "GenSigTimeoutTime_CADM" SG_ 2654486552 CBV_bit0_RepeatMessageRequestBit_1E384018 0;
BA_ "GenSigTimeoutTime_CVPAM" SG_ 2654486552 CBV_bit0_RepeatMessageRequestBit_1E384018 0;
BA_ "GenSigTimeoutTime_ECM" SG_ 2654486552 CBV_bit0_RepeatMessageRequestBit_1E384018 0;
BA_ "GenSigTimeoutTime_EPS" SG_ 2654486552 CBV_bit0_RepeatMessageRequestBit_1E384018 0;
BA_ "GenSigTimeoutTime_EVCU2" SG_ 2654486552 CBV_bit0_RepeatMessageRequestBit_1E384018 0;
BA_ "GenSigTimeoutTime_ORC" SG_ 2654486552 CBV_bit0_RepeatMessageRequestBit_1E384018 0;
BA_ "GenSigTimeoutTime_BSM" SG_ 2654486552 CBV_bit1_1E384018 0;
BA_ "GenSigTimeoutTime_BSM2" SG_ 2654486552 CBV_bit1_1E384018 0;
BA_ "GenSigTimeoutTime_CADM" SG_ 2654486552 CBV_bit1_1E384018 0;
BA_ "GenSigTimeoutTime_CVPAM" SG_ 2654486552 CBV_bit1_1E384018 0;
BA_ "GenSigTimeoutTime_ECM" SG_ 2654486552 CBV_bit1_1E384018 0;
BA_ "GenSigTimeoutTime_EPS" SG_ 2654486552 CBV_bit1_1E384018 0;
BA_ "GenSigTimeoutTime_EVCU2" SG_ 2654486552 CBV_bit1_1E384018 0;
BA_ "GenSigTimeoutTime_ORC" SG_ 2654486552 CBV_bit1_1E384018 0;
BA_ "GenSigTimeoutTime_BSM" SG_ 2654486552 CBV_bit2_1E384018 0;
BA_ "GenSigTimeoutTime_BSM2" SG_ 2654486552 CBV_bit2_1E384018 0;
BA_ "GenSigTimeoutTime_CADM" SG_ 2654486552 CBV_bit2_1E384018 0;
BA_ "GenSigTimeoutTime_CVPAM" SG_ 2654486552 CBV_bit2_1E384018 0;
BA_ "GenSigTimeoutTime_ECM" SG_ 2654486552 CBV_bit2_1E384018 0;
BA_ "GenSigTimeoutTime_EPS" SG_ 2654486552 CBV_bit2_1E384018 0;
BA_ "GenSigTimeoutTime_EVCU2" SG_ 2654486552 CBV_bit2_1E384018 0;
BA_ "GenSigTimeoutTime_ORC" SG_ 2654486552 CBV_bit2_1E384018 0;
BA_ "GenSigTimeoutTime_BSM" SG_ 2654486552 CBV_bit3_NMCoordinatorBit_1E384018 0;
BA_ "GenSigTimeoutTime_BSM2" SG_ 2654486552 CBV_bit3_NMCoordinatorBit_1E384018 0;
BA_ "GenSigTimeoutTime_CADM" SG_ 2654486552 CBV_bit3_NMCoordinatorBit_1E384018 0;
BA_ "GenSigTimeoutTime_CVPAM" SG_ 2654486552 CBV_bit3_NMCoordinatorBit_1E384018 0;
BA_ "GenSigTimeoutTime_ECM" SG_ 2654486552 CBV_bit3_NMCoordinatorBit_1E384018 0;
BA_ "GenSigTimeoutTime_EPS" SG_ 2654486552 CBV_bit3_NMCoordinatorBit_1E384018 0;
BA_ "GenSigTimeoutTime_EVCU2" SG_ 2654486552 CBV_bit3_NMCoordinatorBit_1E384018 0;
BA_ "GenSigTimeoutTime_ORC" SG_ 2654486552 CBV_bit3_NMCoordinatorBit_1E384018 0;
BA_ "GenSigTimeoutTime_BSM" SG_ 2654486552 CBV_bit4_ActiveWakeupBit_1E384018 0;
BA_ "GenSigTimeoutTime_BSM2" SG_ 2654486552 CBV_bit4_ActiveWakeupBit_1E384018 0;
BA_ "GenSigTimeoutTime_CADM" SG_ 2654486552 CBV_bit4_ActiveWakeupBit_1E384018 0;
BA_ "GenSigTimeoutTime_CVPAM" SG_ 2654486552 CBV_bit4_ActiveWakeupBit_1E384018 0;
BA_ "GenSigTimeoutTime_ECM" SG_ 2654486552 CBV_bit4_ActiveWakeupBit_1E384018 0;
BA_ "GenSigTimeoutTime_EPS" SG_ 2654486552 CBV_bit4_ActiveWakeupBit_1E384018 0;
BA_ "GenSigTimeoutTime_EVCU2" SG_ 2654486552 CBV_bit4_ActiveWakeupBit_1E384018 0;
BA_ "GenSigTimeoutTime_ORC" SG_ 2654486552 CBV_bit4_ActiveWakeupBit_1E384018 0;
BA_ "GenSigTimeoutTime_BSM" SG_ 2654486552 CBV_bit5_1E384018 0;
BA_ "GenSigTimeoutTime_BSM2" SG_ 2654486552 CBV_bit5_1E384018 0;
BA_ "GenSigTimeoutTime_CADM" SG_ 2654486552 CBV_bit5_1E384018 0;
BA_ "GenSigTimeoutTime_CVPAM" SG_ 2654486552 CBV_bit5_1E384018 0;
BA_ "GenSigTimeoutTime_ECM" SG_ 2654486552 CBV_bit5_1E384018 0;
BA_ "GenSigTimeoutTime_EPS" SG_ 2654486552 CBV_bit5_1E384018 0;
BA_ "GenSigTimeoutTime_EVCU2" SG_ 2654486552 CBV_bit5_1E384018 0;
BA_ "GenSigTimeoutTime_ORC" SG_ 2654486552 CBV_bit5_1E384018 0;
BA_ "GenSigTimeoutTime_BSM" SG_ 2654486552 CBV_bit6_PartialNtwInfBit_1E384018 0;
BA_ "GenSigTimeoutTime_BSM2" SG_ 2654486552 CBV_bit6_PartialNtwInfBit_1E384018 0;
BA_ "GenSigTimeoutTime_CADM" SG_ 2654486552 CBV_bit6_PartialNtwInfBit_1E384018 0;
BA_ "GenSigTimeoutTime_CVPAM" SG_ 2654486552 CBV_bit6_PartialNtwInfBit_1E384018 0;
BA_ "GenSigTimeoutTime_ECM" SG_ 2654486552 CBV_bit6_PartialNtwInfBit_1E384018 0;
BA_ "GenSigTimeoutTime_EPS" SG_ 2654486552 CBV_bit6_PartialNtwInfBit_1E384018 0;
BA_ "GenSigTimeoutTime_EVCU2" SG_ 2654486552 CBV_bit6_PartialNtwInfBit_1E384018 0;
BA_ "GenSigTimeoutTime_ORC" SG_ 2654486552 CBV_bit6_PartialNtwInfBit_1E384018 0;
BA_ "GenSigTimeoutTime_BSM" SG_ 2654486552 CBV_bit7_1E384018 0;
BA_ "GenSigTimeoutTime_BSM2" SG_ 2654486552 CBV_bit7_1E384018 0;
BA_ "GenSigTimeoutTime_CADM" SG_ 2654486552 CBV_bit7_1E384018 0;
BA_ "GenSigTimeoutTime_CVPAM" SG_ 2654486552 CBV_bit7_1E384018 0;
BA_ "GenSigTimeoutTime_ECM" SG_ 2654486552 CBV_bit7_1E384018 0;
BA_ "GenSigTimeoutTime_EPS" SG_ 2654486552 CBV_bit7_1E384018 0;
BA_ "GenSigTimeoutTime_EVCU2" SG_ 2654486552 CBV_bit7_1E384018 0;
BA_ "GenSigTimeoutTime_ORC" SG_ 2654486552 CBV_bit7_1E384018 0;
BA_ "GenSigTimeoutTime_BSM" SG_ 2654486552 SourceNodeIdentifier_1E384018 0;
BA_ "GenSigTimeoutTime_BSM2" SG_ 2654486552 SourceNodeIdentifier_1E384018 0;
BA_ "GenSigTimeoutTime_CADM" SG_ 2654486552 SourceNodeIdentifier_1E384018 0;
BA_ "GenSigTimeoutTime_CVPAM" SG_ 2654486552 SourceNodeIdentifier_1E384018 0;
BA_ "GenSigTimeoutTime_ECM" SG_ 2654486552 SourceNodeIdentifier_1E384018 0;
BA_ "GenSigTimeoutTime_EPS" SG_ 2654486552 SourceNodeIdentifier_1E384018 0;
BA_ "GenSigTimeoutTime_EVCU2" SG_ 2654486552 SourceNodeIdentifier_1E384018 0;
BA_ "GenSigTimeoutTime_ORC" SG_ 2654486552 SourceNodeIdentifier_1E384018 0;
BA_ "GenSigTimeoutTime_MPAD" SG_ 2654486530 CBV_bit0_RepeatMessageRequestBit_1E384002 0;
BA_ "GenSigTimeoutTime_ADCAM" SG_ 2654486530 CBV_bit0_RepeatMessageRequestBit_1E384002 0;
BA_ "GenSigTimeoutTime_CVADAS" SG_ 2654486530 CBV_bit0_RepeatMessageRequestBit_1E384002 0;
BA_ "GenSigTimeoutTime_MPAD" SG_ 2654486530 CBV_bit1_1E384002 0;
BA_ "GenSigTimeoutTime_ADCAM" SG_ 2654486530 CBV_bit1_1E384002 0;
BA_ "GenSigTimeoutTime_CVADAS" SG_ 2654486530 CBV_bit1_1E384002 0;
BA_ "GenSigTimeoutTime_MPAD" SG_ 2654486530 CBV_bit2_1E384002 0;
BA_ "GenSigTimeoutTime_ADCAM" SG_ 2654486530 CBV_bit2_1E384002 0;
BA_ "GenSigTimeoutTime_CVADAS" SG_ 2654486530 CBV_bit2_1E384002 0;
BA_ "GenSigTimeoutTime_MPAD" SG_ 2654486530 CBV_bit3_NMCoordinatorBit_1E384002 0;
BA_ "GenSigTimeoutTime_ADCAM" SG_ 2654486530 CBV_bit3_NMCoordinatorBit_1E384002 0;
BA_ "GenSigTimeoutTime_CVADAS" SG_ 2654486530 CBV_bit3_NMCoordinatorBit_1E384002 0;
BA_ "GenSigTimeoutTime_MPAD" SG_ 2654486530 CBV_bit4_ActiveWakeupBit_1E384002 0;
BA_ "GenSigTimeoutTime_ADCAM" SG_ 2654486530 CBV_bit4_ActiveWakeupBit_1E384002 0;
BA_ "GenSigTimeoutTime_CVADAS" SG_ 2654486530 CBV_bit4_ActiveWakeupBit_1E384002 0;
BA_ "GenSigTimeoutTime_MPAD" SG_ 2654486530 CBV_bit5_1E384002 0;
BA_ "GenSigTimeoutTime_ADCAM" SG_ 2654486530 CBV_bit5_1E384002 0;
BA_ "GenSigTimeoutTime_CVADAS" SG_ 2654486530 CBV_bit5_1E384002 0;
BA_ "GenSigTimeoutTime_MPAD" SG_ 2654486530 CBV_bit6_PartialNtwInfBit_1E384002 0;
BA_ "GenSigTimeoutTime_ADCAM" SG_ 2654486530 CBV_bit6_PartialNtwInfBit_1E384002 0;
BA_ "GenSigTimeoutTime_CVADAS" SG_ 2654486530 CBV_bit6_PartialNtwInfBit_1E384002 0;
BA_ "GenSigTimeoutTime_MPAD" SG_ 2654486530 CBV_bit7_1E384002 0;
BA_ "GenSigTimeoutTime_ADCAM" SG_ 2654486530 CBV_bit7_1E384002 0;
BA_ "GenSigTimeoutTime_CVADAS" SG_ 2654486530 CBV_bit7_1E384002 0;
BA_ "GenSigTimeoutTime_MPAD" SG_ 2654486530 SourceNodeIdentifier_1E384002 0;
BA_ "GenSigTimeoutTime_ADCAM" SG_ 2654486530 SourceNodeIdentifier_1E384002 0;
BA_ "GenSigTimeoutTime_CVADAS" SG_ 2654486530 SourceNodeIdentifier_1E384002 0;
BA_ "GenSigTimeoutTime_BSM" SG_ 2654486530 CBV_bit0_RepeatMessageRequestBit_1E384002 0;
BA_ "GenSigTimeoutTime_BSM2" SG_ 2654486530 CBV_bit0_RepeatMessageRequestBit_1E384002 0;
BA_ "GenSigTimeoutTime_CADM" SG_ 2654486530 CBV_bit0_RepeatMessageRequestBit_1E384002 0;
BA_ "GenSigTimeoutTime_CVPAM" SG_ 2654486530 CBV_bit0_RepeatMessageRequestBit_1E384002 0;
BA_ "GenSigTimeoutTime_ECM" SG_ 2654486530 CBV_bit0_RepeatMessageRequestBit_1E384002 0;
BA_ "GenSigTimeoutTime_EPS" SG_ 2654486530 CBV_bit0_RepeatMessageRequestBit_1E384002 0;
BA_ "GenSigTimeoutTime_EVCU2" SG_ 2654486530 CBV_bit0_RepeatMessageRequestBit_1E384002 0;
BA_ "GenSigTimeoutTime_ORC" SG_ 2654486530 CBV_bit0_RepeatMessageRequestBit_1E384002 0;
BA_ "GenSigTimeoutTime_BSM" SG_ 2654486530 CBV_bit1_1E384002 0;
BA_ "GenSigTimeoutTime_BSM2" SG_ 2654486530 CBV_bit1_1E384002 0;
BA_ "GenSigTimeoutTime_CADM" SG_ 2654486530 CBV_bit1_1E384002 0;
BA_ "GenSigTimeoutTime_CVPAM" SG_ 2654486530 CBV_bit1_1E384002 0;
BA_ "GenSigTimeoutTime_ECM" SG_ 2654486530 CBV_bit1_1E384002 0;
BA_ "GenSigTimeoutTime_EPS" SG_ 2654486530 CBV_bit1_1E384002 0;
BA_ "GenSigTimeoutTime_EVCU2" SG_ 2654486530 CBV_bit1_1E384002 0;
BA_ "GenSigTimeoutTime_ORC" SG_ 2654486530 CBV_bit1_1E384002 0;
BA_ "GenSigTimeoutTime_BSM" SG_ 2654486530 CBV_bit2_1E384002 0;
BA_ "GenSigTimeoutTime_BSM2" SG_ 2654486530 CBV_bit2_1E384002 0;
BA_ "GenSigTimeoutTime_CADM" SG_ 2654486530 CBV_bit2_1E384002 0;
BA_ "GenSigTimeoutTime_CVPAM" SG_ 2654486530 CBV_bit2_1E384002 0;
BA_ "GenSigTimeoutTime_ECM" SG_ 2654486530 CBV_bit2_1E384002 0;
BA_ "GenSigTimeoutTime_EPS" SG_ 2654486530 CBV_bit2_1E384002 0;
BA_ "GenSigTimeoutTime_EVCU2" SG_ 2654486530 CBV_bit2_1E384002 0;
BA_ "GenSigTimeoutTime_ORC" SG_ 2654486530 CBV_bit2_1E384002 0;
BA_ "GenSigTimeoutTime_BSM" SG_ 2654486530 CBV_bit3_NMCoordinatorBit_1E384002 0;
BA_ "GenSigTimeoutTime_BSM2" SG_ 2654486530 CBV_bit3_NMCoordinatorBit_1E384002 0;
BA_ "GenSigTimeoutTime_CADM" SG_ 2654486530 CBV_bit3_NMCoordinatorBit_1E384002 0;
BA_ "GenSigTimeoutTime_CVPAM" SG_ 2654486530 CBV_bit3_NMCoordinatorBit_1E384002 0;
BA_ "GenSigTimeoutTime_ECM" SG_ 2654486530 CBV_bit3_NMCoordinatorBit_1E384002 0;
BA_ "GenSigTimeoutTime_EPS" SG_ 2654486530 CBV_bit3_NMCoordinatorBit_1E384002 0;
BA_ "GenSigTimeoutTime_EVCU2" SG_ 2654486530 CBV_bit3_NMCoordinatorBit_1E384002 0;
BA_ "GenSigTimeoutTime_ORC" SG_ 2654486530 CBV_bit3_NMCoordinatorBit_1E384002 0;
BA_ "GenSigTimeoutTime_BSM" SG_ 2654486530 CBV_bit4_ActiveWakeupBit_1E384002 0;
BA_ "GenSigTimeoutTime_BSM2" SG_ 2654486530 CBV_bit4_ActiveWakeupBit_1E384002 0;
BA_ "GenSigTimeoutTime_CADM" SG_ 2654486530 CBV_bit4_ActiveWakeupBit_1E384002 0;
BA_ "GenSigTimeoutTime_CVPAM" SG_ 2654486530 CBV_bit4_ActiveWakeupBit_1E384002 0;
BA_ "GenSigTimeoutTime_ECM" SG_ 2654486530 CBV_bit4_ActiveWakeupBit_1E384002 0;
BA_ "GenSigTimeoutTime_EPS" SG_ 2654486530 CBV_bit4_ActiveWakeupBit_1E384002 0;
BA_ "GenSigTimeoutTime_EVCU2" SG_ 2654486530 CBV_bit4_ActiveWakeupBit_1E384002 0;
BA_ "GenSigTimeoutTime_ORC" SG_ 2654486530 CBV_bit4_ActiveWakeupBit_1E384002 0;
BA_ "GenSigTimeoutTime_BSM" SG_ 2654486530 CBV_bit5_1E384002 0;
BA_ "GenSigTimeoutTime_BSM2" SG_ 2654486530 CBV_bit5_1E384002 0;
BA_ "GenSigTimeoutTime_CADM" SG_ 2654486530 CBV_bit5_1E384002 0;
BA_ "GenSigTimeoutTime_CVPAM" SG_ 2654486530 CBV_bit5_1E384002 0;
BA_ "GenSigTimeoutTime_ECM" SG_ 2654486530 CBV_bit5_1E384002 0;
BA_ "GenSigTimeoutTime_EPS" SG_ 2654486530 CBV_bit5_1E384002 0;
BA_ "GenSigTimeoutTime_EVCU2" SG_ 2654486530 CBV_bit5_1E384002 0;
BA_ "GenSigTimeoutTime_ORC" SG_ 2654486530 CBV_bit5_1E384002 0;
BA_ "GenSigTimeoutTime_BSM" SG_ 2654486530 CBV_bit6_PartialNtwInfBit_1E384002 0;
BA_ "GenSigTimeoutTime_BSM2" SG_ 2654486530 CBV_bit6_PartialNtwInfBit_1E384002 0;
BA_ "GenSigTimeoutTime_CADM" SG_ 2654486530 CBV_bit6_PartialNtwInfBit_1E384002 0;
BA_ "GenSigTimeoutTime_CVPAM" SG_ 2654486530 CBV_bit6_PartialNtwInfBit_1E384002 0;
BA_ "GenSigTimeoutTime_ECM" SG_ 2654486530 CBV_bit6_PartialNtwInfBit_1E384002 0;
BA_ "GenSigTimeoutTime_EPS" SG_ 2654486530 CBV_bit6_PartialNtwInfBit_1E384002 0;
BA_ "GenSigTimeoutTime_EVCU2" SG_ 2654486530 CBV_bit6_PartialNtwInfBit_1E384002 0;
BA_ "GenSigTimeoutTime_ORC" SG_ 2654486530 CBV_bit6_PartialNtwInfBit_1E384002 0;
BA_ "GenSigTimeoutTime_BSM" SG_ 2654486530 CBV_bit7_1E384002 0;
BA_ "GenSigTimeoutTime_BSM2" SG_ 2654486530 CBV_bit7_1E384002 0;
BA_ "GenSigTimeoutTime_CADM" SG_ 2654486530 CBV_bit7_1E384002 0;
BA_ "GenSigTimeoutTime_CVPAM" SG_ 2654486530 CBV_bit7_1E384002 0;
BA_ "GenSigTimeoutTime_ECM" SG_ 2654486530 CBV_bit7_1E384002 0;
BA_ "GenSigTimeoutTime_EPS" SG_ 2654486530 CBV_bit7_1E384002 0;
BA_ "GenSigTimeoutTime_EVCU2" SG_ 2654486530 CBV_bit7_1E384002 0;
BA_ "GenSigTimeoutTime_ORC" SG_ 2654486530 CBV_bit7_1E384002 0;
BA_ "GenSigTimeoutTime_BSM" SG_ 2654486530 SourceNodeIdentifier_1E384002 0;
BA_ "GenSigTimeoutTime_BSM2" SG_ 2654486530 SourceNodeIdentifier_1E384002 0;
BA_ "GenSigTimeoutTime_CADM" SG_ 2654486530 SourceNodeIdentifier_1E384002 0;
BA_ "GenSigTimeoutTime_CVPAM" SG_ 2654486530 SourceNodeIdentifier_1E384002 0;
BA_ "GenSigTimeoutTime_ECM" SG_ 2654486530 SourceNodeIdentifier_1E384002 0;
BA_ "GenSigTimeoutTime_EPS" SG_ 2654486530 SourceNodeIdentifier_1E384002 0;
BA_ "GenSigTimeoutTime_EVCU2" SG_ 2654486530 SourceNodeIdentifier_1E384002 0;
BA_ "GenSigTimeoutTime_ORC" SG_ 2654486530 SourceNodeIdentifier_1E384002 0;
BA_ "GenSigTimeoutTime_ADCAM" SG_ 1156 ABSFailSts_B2 0;
BA_ "GenSigTimeoutTime_CVADAS" SG_ 1156 ABSFailSts_B2 0;
BA_ "GenSigTimeoutTime_MPAD" SG_ 1156 CRC_BRAKE2_3 0;
BA_ "GenSigTimeoutTime_ADCAM" SG_ 1156 CRC_BRAKE2_3 0;
BA_ "GenSigTimeoutTime_CVADAS" SG_ 1156 CRC_BRAKE2_3 0;
BA_ "GenSigTimeoutTime_MPAD" SG_ 1156 MessageCounter_BRAKE2_3 0;
BA_ "GenSigTimeoutTime_ADCAM" SG_ 1156 MessageCounter_BRAKE2_3 0;
BA_ "GenSigTimeoutTime_CVADAS" SG_ 1156 MessageCounter_BRAKE2_3 0;
BA_ "GenSigTimeoutTime_ADCAM" SG_ 1156 RollsModeAct_B2 0;
BA_ "GenSigTimeoutTime_CVADAS" SG_ 1156 RollsModeAct_B2 0;
BA_ "GenSigSendType" SG_ 1156 ABSFailSts_B2 4;
BA_ "GenSigTimeoutTime_BSM" SG_ 1156 ABSFailSts_B2 0;
BA_ "GenSigTimeoutTime_BSM2" SG_ 1156 ABSFailSts_B2 0;
BA_ "GenSigTimeoutTime_CVPAM" SG_ 1156 ABSFailSts_B2 0;
BA_ "GenSigTimeoutTime_ECM" SG_ 1156 ABSFailSts_B2 0;
BA_ "GenSigTimeoutTime_EPS" SG_ 1156 ABSFailSts_B2 0;
BA_ "GenSigTimeoutTime_EVCU2" SG_ 1156 ABSFailSts_B2 0;
BA_ "GenSigTimeoutTime_ORC" SG_ 1156 ABSFailSts_B2 0;
BA_ "GenSigSendType" SG_ 1156 BSM2_FaultSts 4;
BA_ "GenSigTimeoutTime_BSM" SG_ 1156 BSM2_FaultSts 0;
BA_ "GenSigTimeoutTime_BSM2" SG_ 1156 BSM2_FaultSts 0;
BA_ "GenSigTimeoutTime_CVPAM" SG_ 1156 BSM2_FaultSts 0;
BA_ "GenSigTimeoutTime_ECM" SG_ 1156 BSM2_FaultSts 0;
BA_ "GenSigTimeoutTime_EPS" SG_ 1156 BSM2_FaultSts 0;
BA_ "GenSigTimeoutTime_EVCU2" SG_ 1156 BSM2_FaultSts 0;
BA_ "GenSigTimeoutTime_ORC" SG_ 1156 BSM2_FaultSts 0;
BA_ "GenSigTimeoutTime_BSM" SG_ 1156 CRC_BRAKE2_3 0;
BA_ "GenSigTimeoutTime_BSM2" SG_ 1156 CRC_BRAKE2_3 0;
BA_ "GenSigTimeoutTime_CVPAM" SG_ 1156 CRC_BRAKE2_3 0;
BA_ "GenSigTimeoutTime_ECM" SG_ 1156 CRC_BRAKE2_3 0;
BA_ "GenSigTimeoutTime_EPS" SG_ 1156 CRC_BRAKE2_3 0;
BA_ "GenSigTimeoutTime_EVCU2" SG_ 1156 CRC_BRAKE2_3 0;
BA_ "GenSigTimeoutTime_BSM" SG_ 1156 MessageCounter_BRAKE2_3 0;
BA_ "GenSigTimeoutTime_BSM2" SG_ 1156 MessageCounter_BRAKE2_3 0;
BA_ "GenSigTimeoutTime_CVPAM" SG_ 1156 MessageCounter_BRAKE2_3 0;
BA_ "GenSigTimeoutTime_ECM" SG_ 1156 MessageCounter_BRAKE2_3 0;
BA_ "GenSigTimeoutTime_EPS" SG_ 1156 MessageCounter_BRAKE2_3 0;
BA_ "GenSigTimeoutTime_EVCU2" SG_ 1156 MessageCounter_BRAKE2_3 0;
BA_ "GenSigSendType" SG_ 1156 RollsModeAct_B2 4;
BA_ "GenSigTimeoutTime_BSM" SG_ 1156 RollsModeAct_B2 0;
BA_ "GenSigTimeoutTime_BSM2" SG_ 1156 RollsModeAct_B2 0;
BA_ "GenSigTimeoutTime_CVPAM" SG_ 1156 RollsModeAct_B2 0;
BA_ "GenSigTimeoutTime_ECM" SG_ 1156 RollsModeAct_B2 0;
BA_ "GenSigTimeoutTime_EPS" SG_ 1156 RollsModeAct_B2 0;
BA_ "GenSigTimeoutTime_EVCU2" SG_ 1156 RollsModeAct_B2 0;
BA_ "GenSigTimeoutTime_ORC" SG_ 1156 RollsModeAct_B2 0;
BA_ "GenSigTimeoutTime_MPAD" SG_ 2654486676 CBV_bit0_RepeatMessageRequestBit_1E384094 0;
BA_ "GenSigTimeoutTime_ADCAM" SG_ 2654486676 CBV_bit0_RepeatMessageRequestBit_1E384094 0;
BA_ "GenSigTimeoutTime_CVADAS" SG_ 2654486676 CBV_bit0_RepeatMessageRequestBit_1E384094 0;
BA_ "GenSigTimeoutTime_MPAD" SG_ 2654486676 CBV_bit1_1E384094 0;
BA_ "GenSigTimeoutTime_ADCAM" SG_ 2654486676 CBV_bit1_1E384094 0;
BA_ "GenSigTimeoutTime_CVADAS" SG_ 2654486676 CBV_bit1_1E384094 0;
BA_ "GenSigTimeoutTime_MPAD" SG_ 2654486676 CBV_bit2_1E384094 0;
BA_ "GenSigTimeoutTime_ADCAM" SG_ 2654486676 CBV_bit2_1E384094 0;
BA_ "GenSigTimeoutTime_CVADAS" SG_ 2654486676 CBV_bit2_1E384094 0;
BA_ "GenSigTimeoutTime_MPAD" SG_ 2654486676 CBV_bit3_NMCoordinatorBit_1E384094 0;
BA_ "GenSigTimeoutTime_ADCAM" SG_ 2654486676 CBV_bit3_NMCoordinatorBit_1E384094 0;
BA_ "GenSigTimeoutTime_CVADAS" SG_ 2654486676 CBV_bit3_NMCoordinatorBit_1E384094 0;
BA_ "GenSigTimeoutTime_MPAD" SG_ 2654486676 CBV_bit4_ActiveWakeupBit_1E384094 0;
BA_ "GenSigTimeoutTime_ADCAM" SG_ 2654486676 CBV_bit4_ActiveWakeupBit_1E384094 0;
BA_ "GenSigTimeoutTime_CVADAS" SG_ 2654486676 CBV_bit4_ActiveWakeupBit_1E384094 0;
BA_ "GenSigTimeoutTime_MPAD" SG_ 2654486676 CBV_bit5_1E384094 0;
BA_ "GenSigTimeoutTime_ADCAM" SG_ 2654486676 CBV_bit5_1E384094 0;
BA_ "GenSigTimeoutTime_CVADAS" SG_ 2654486676 CBV_bit5_1E384094 0;
BA_ "GenSigTimeoutTime_MPAD" SG_ 2654486676 CBV_bit6_PartialNtwInfBit_1E384094 0;
BA_ "GenSigTimeoutTime_ADCAM" SG_ 2654486676 CBV_bit6_PartialNtwInfBit_1E384094 0;
BA_ "GenSigTimeoutTime_CVADAS" SG_ 2654486676 CBV_bit6_PartialNtwInfBit_1E384094 0;
BA_ "GenSigTimeoutTime_MPAD" SG_ 2654486676 CBV_bit7_1E384094 0;
BA_ "GenSigTimeoutTime_ADCAM" SG_ 2654486676 CBV_bit7_1E384094 0;
BA_ "GenSigTimeoutTime_CVADAS" SG_ 2654486676 CBV_bit7_1E384094 0;
BA_ "GenSigTimeoutTime_MPAD" SG_ 2654486676 SourceNodeIdentifier_1E384094 0;
BA_ "GenSigTimeoutTime_ADCAM" SG_ 2654486676 SourceNodeIdentifier_1E384094 0;
BA_ "GenSigTimeoutTime_CVADAS" SG_ 2654486676 SourceNodeIdentifier_1E384094 0;
BA_ "GenSigTimeoutTime_BSM" SG_ 2654486676 CBV_bit0_RepeatMessageRequestBit_1E384094 0;
BA_ "GenSigTimeoutTime_BSM2" SG_ 2654486676 CBV_bit0_RepeatMessageRequestBit_1E384094 0;
BA_ "GenSigTimeoutTime_CADM" SG_ 2654486676 CBV_bit0_RepeatMessageRequestBit_1E384094 0;
BA_ "GenSigTimeoutTime_CVPAM" SG_ 2654486676 CBV_bit0_RepeatMessageRequestBit_1E384094 0;
BA_ "GenSigTimeoutTime_ECM" SG_ 2654486676 CBV_bit0_RepeatMessageRequestBit_1E384094 0;
BA_ "GenSigTimeoutTime_EPS" SG_ 2654486676 CBV_bit0_RepeatMessageRequestBit_1E384094 0;
BA_ "GenSigTimeoutTime_EVCU2" SG_ 2654486676 CBV_bit0_RepeatMessageRequestBit_1E384094 0;
BA_ "GenSigTimeoutTime_ORC" SG_ 2654486676 CBV_bit0_RepeatMessageRequestBit_1E384094 0;
BA_ "GenSigTimeoutTime_BSM" SG_ 2654486676 CBV_bit1_1E384094 0;
BA_ "GenSigTimeoutTime_BSM2" SG_ 2654486676 CBV_bit1_1E384094 0;
BA_ "GenSigTimeoutTime_CADM" SG_ 2654486676 CBV_bit1_1E384094 0;
BA_ "GenSigTimeoutTime_CVPAM" SG_ 2654486676 CBV_bit1_1E384094 0;
BA_ "GenSigTimeoutTime_ECM" SG_ 2654486676 CBV_bit1_1E384094 0;
BA_ "GenSigTimeoutTime_EPS" SG_ 2654486676 CBV_bit1_1E384094 0;
BA_ "GenSigTimeoutTime_EVCU2" SG_ 2654486676 CBV_bit1_1E384094 0;
BA_ "GenSigTimeoutTime_ORC" SG_ 2654486676 CBV_bit1_1E384094 0;
BA_ "GenSigTimeoutTime_BSM" SG_ 2654486676 CBV_bit2_1E384094 0;
BA_ "GenSigTimeoutTime_BSM2" SG_ 2654486676 CBV_bit2_1E384094 0;
BA_ "GenSigTimeoutTime_CADM" SG_ 2654486676 CBV_bit2_1E384094 0;
BA_ "GenSigTimeoutTime_CVPAM" SG_ 2654486676 CBV_bit2_1E384094 0;
BA_ "GenSigTimeoutTime_ECM" SG_ 2654486676 CBV_bit2_1E384094 0;
BA_ "GenSigTimeoutTime_EPS" SG_ 2654486676 CBV_bit2_1E384094 0;
BA_ "GenSigTimeoutTime_EVCU2" SG_ 2654486676 CBV_bit2_1E384094 0;
BA_ "GenSigTimeoutTime_ORC" SG_ 2654486676 CBV_bit2_1E384094 0;
BA_ "GenSigTimeoutTime_BSM" SG_ 2654486676 CBV_bit3_NMCoordinatorBit_1E384094 0;
BA_ "GenSigTimeoutTime_BSM2" SG_ 2654486676 CBV_bit3_NMCoordinatorBit_1E384094 0;
BA_ "GenSigTimeoutTime_CADM" SG_ 2654486676 CBV_bit3_NMCoordinatorBit_1E384094 0;
BA_ "GenSigTimeoutTime_CVPAM" SG_ 2654486676 CBV_bit3_NMCoordinatorBit_1E384094 0;
BA_ "GenSigTimeoutTime_ECM" SG_ 2654486676 CBV_bit3_NMCoordinatorBit_1E384094 0;
BA_ "GenSigTimeoutTime_EPS" SG_ 2654486676 CBV_bit3_NMCoordinatorBit_1E384094 0;
BA_ "GenSigTimeoutTime_EVCU2" SG_ 2654486676 CBV_bit3_NMCoordinatorBit_1E384094 0;
BA_ "GenSigTimeoutTime_ORC" SG_ 2654486676 CBV_bit3_NMCoordinatorBit_1E384094 0;
BA_ "GenSigTimeoutTime_BSM" SG_ 2654486676 CBV_bit4_ActiveWakeupBit_1E384094 0;
BA_ "GenSigTimeoutTime_BSM2" SG_ 2654486676 CBV_bit4_ActiveWakeupBit_1E384094 0;
BA_ "GenSigTimeoutTime_CADM" SG_ 2654486676 CBV_bit4_ActiveWakeupBit_1E384094 0;
BA_ "GenSigTimeoutTime_CVPAM" SG_ 2654486676 CBV_bit4_ActiveWakeupBit_1E384094 0;
BA_ "GenSigTimeoutTime_ECM" SG_ 2654486676 CBV_bit4_ActiveWakeupBit_1E384094 0;
BA_ "GenSigTimeoutTime_EPS" SG_ 2654486676 CBV_bit4_ActiveWakeupBit_1E384094 0;
BA_ "GenSigTimeoutTime_EVCU2" SG_ 2654486676 CBV_bit4_ActiveWakeupBit_1E384094 0;
BA_ "GenSigTimeoutTime_ORC" SG_ 2654486676 CBV_bit4_ActiveWakeupBit_1E384094 0;
BA_ "GenSigTimeoutTime_BSM" SG_ 2654486676 CBV_bit5_1E384094 0;
BA_ "GenSigTimeoutTime_BSM2" SG_ 2654486676 CBV_bit5_1E384094 0;
BA_ "GenSigTimeoutTime_CADM" SG_ 2654486676 CBV_bit5_1E384094 0;
BA_ "GenSigTimeoutTime_CVPAM" SG_ 2654486676 CBV_bit5_1E384094 0;
BA_ "GenSigTimeoutTime_ECM" SG_ 2654486676 CBV_bit5_1E384094 0;
BA_ "GenSigTimeoutTime_EPS" SG_ 2654486676 CBV_bit5_1E384094 0;
BA_ "GenSigTimeoutTime_EVCU2" SG_ 2654486676 CBV_bit5_1E384094 0;
BA_ "GenSigTimeoutTime_ORC" SG_ 2654486676 CBV_bit5_1E384094 0;
BA_ "GenSigTimeoutTime_BSM" SG_ 2654486676 CBV_bit6_PartialNtwInfBit_1E384094 0;
BA_ "GenSigTimeoutTime_BSM2" SG_ 2654486676 CBV_bit6_PartialNtwInfBit_1E384094 0;
BA_ "GenSigTimeoutTime_CADM" SG_ 2654486676 CBV_bit6_PartialNtwInfBit_1E384094 0;
BA_ "GenSigTimeoutTime_CVPAM" SG_ 2654486676 CBV_bit6_PartialNtwInfBit_1E384094 0;
BA_ "GenSigTimeoutTime_ECM" SG_ 2654486676 CBV_bit6_PartialNtwInfBit_1E384094 0;
BA_ "GenSigTimeoutTime_EPS" SG_ 2654486676 CBV_bit6_PartialNtwInfBit_1E384094 0;
BA_ "GenSigTimeoutTime_EVCU2" SG_ 2654486676 CBV_bit6_PartialNtwInfBit_1E384094 0;
BA_ "GenSigTimeoutTime_ORC" SG_ 2654486676 CBV_bit6_PartialNtwInfBit_1E384094 0;
BA_ "GenSigTimeoutTime_BSM" SG_ 2654486676 CBV_bit7_1E384094 0;
BA_ "GenSigTimeoutTime_BSM2" SG_ 2654486676 CBV_bit7_1E384094 0;
BA_ "GenSigTimeoutTime_CADM" SG_ 2654486676 CBV_bit7_1E384094 0;
BA_ "GenSigTimeoutTime_CVPAM" SG_ 2654486676 CBV_bit7_1E384094 0;
BA_ "GenSigTimeoutTime_ECM" SG_ 2654486676 CBV_bit7_1E384094 0;
BA_ "GenSigTimeoutTime_EPS" SG_ 2654486676 CBV_bit7_1E384094 0;
BA_ "GenSigTimeoutTime_EVCU2" SG_ 2654486676 CBV_bit7_1E384094 0;
BA_ "GenSigTimeoutTime_ORC" SG_ 2654486676 CBV_bit7_1E384094 0;
BA_ "GenSigTimeoutTime_BSM" SG_ 2654486676 SourceNodeIdentifier_1E384094 0;
BA_ "GenSigTimeoutTime_BSM2" SG_ 2654486676 SourceNodeIdentifier_1E384094 0;
BA_ "GenSigTimeoutTime_CADM" SG_ 2654486676 SourceNodeIdentifier_1E384094 0;
BA_ "GenSigTimeoutTime_CVPAM" SG_ 2654486676 SourceNodeIdentifier_1E384094 0;
BA_ "GenSigTimeoutTime_ECM" SG_ 2654486676 SourceNodeIdentifier_1E384094 0;
BA_ "GenSigTimeoutTime_EPS" SG_ 2654486676 SourceNodeIdentifier_1E384094 0;
BA_ "GenSigTimeoutTime_EVCU2" SG_ 2654486676 SourceNodeIdentifier_1E384094 0;
BA_ "GenSigTimeoutTime_ORC" SG_ 2654486676 SourceNodeIdentifier_1E384094 0;
BA_ "GenSigTimeoutTime_MPAD" SG_ 257 CRC_BRAKE2_1 0;
BA_ "GenSigTimeoutTime_ADCAM" SG_ 257 CRC_BRAKE2_1 0;
BA_ "GenSigTimeoutTime_CVADAS" SG_ 257 CRC_BRAKE2_1 0;
BA_ "GenSigTimeoutTime_ADCAM" SG_ 257 Inlet_Pressure_Pos 0;
BA_ "GenSigTimeoutTime_CVADAS" SG_ 257 Inlet_Pressure_Pos 0;
BA_ "GenSigTimeoutTime_ADCAM" SG_ 257 LHF_Spin_B2 0;
BA_ "GenSigTimeoutTime_CVADAS" SG_ 257 LHF_Spin_B2 0;
BA_ "GenSigTimeoutTime_ADCAM" SG_ 257 LHF_WheelSensorFailSts_B2 0;
BA_ "GenSigTimeoutTime_CVADAS" SG_ 257 LHF_WheelSensorFailSts_B2 0;
BA_ "GenSigTimeoutTime_MPAD" SG_ 257 MessageCounter_BRAKE2_1 0;
BA_ "GenSigTimeoutTime_ADCAM" SG_ 257 MessageCounter_BRAKE2_1 0;
BA_ "GenSigTimeoutTime_CVADAS" SG_ 257 MessageCounter_BRAKE2_1 0;
BA_ "GenSigTimeoutTime_ADCAM" SG_ 257 RHF_Spin_B2 0;
BA_ "GenSigTimeoutTime_CVADAS" SG_ 257 RHF_Spin_B2 0;
BA_ "GenSigTimeoutTime_MPAD" SG_ 257 Ft_RrAxleCoupling_TrqRq_B2 0;
BA_ "GenSigTimeoutTime_ADCAM" SG_ 257 Ft_RrAxleCoupling_TrqRq_B2 0;
BA_ "GenSigTimeoutTime_CVADAS" SG_ 257 Ft_RrAxleCoupling_TrqRq_B2 0;
BA_ "GenSigTimeoutTime_MPAD" SG_ 257 Ft_RrTrqCoupling_ModeRq_B2 0;
BA_ "GenSigTimeoutTime_ADCAM" SG_ 257 Ft_RrTrqCoupling_ModeRq_B2 0;
BA_ "GenSigTimeoutTime_CVADAS" SG_ 257 Ft_RrTrqCoupling_ModeRq_B2 0;
BA_ "GenSigTimeoutTime_CVADAS" SG_ 257 R_DIFF_TRQ_RQ_B2 0;
BA_ "GenSigTimeoutTime_CVADAS" SG_ 257 Rear_Diff_BSM_RQ_B2 0;
BA_ "GenSigTimeoutTime_ADCAM" SG_ 257 ABSActive_B2 0;
BA_ "GenSigTimeoutTime_CVADAS" SG_ 257 ABSActive_B2 0;
BA_ "GenSigTimeoutTime_ADCAM" SG_ 257 Brk_Stat_B2 0;
BA_ "GenSigTimeoutTime_CVADAS" SG_ 257 Brk_Stat_B2 0;
BA_ "GenSigTimeoutTime_ADCAM" SG_ 257 RHF_WheelSensorFailSts_B2 0;
BA_ "GenSigTimeoutTime_CVADAS" SG_ 257 RHF_WheelSensorFailSts_B2 0;
BA_ "GenSigTimeoutTime_ADCAM" SG_ 257 LHF_FastPulseCounter_B2 0;
BA_ "GenSigTimeoutTime_CVADAS" SG_ 257 LHF_FastPulseCounter_B2 0;
BA_ "GenSigTimeoutTime_ADCAM" SG_ 257 LHFWheelSpeed_B2 0;
BA_ "GenSigTimeoutTime_CVADAS" SG_ 257 LHFWheelSpeed_B2 0;
BA_ "GenSigTimeoutTime_ADCAM" SG_ 257 RHF_FastPulseCounter_B2 0;
BA_ "GenSigTimeoutTime_CVADAS" SG_ 257 RHF_FastPulseCounter_B2 0;
BA_ "GenSigTimeoutTime_ADCAM" SG_ 257 RHFWheelSpeed_B2 0;
BA_ "GenSigTimeoutTime_CVADAS" SG_ 257 RHFWheelSpeed_B2 0;
BA_ "GenSigTimeoutTime_ADCAM" SG_ 257 VehicleSpeedVSOSig_B2 0;
BA_ "GenSigTimeoutTime_CVADAS" SG_ 257 VehicleSpeedVSOSig_B2 0;
BA_ "GenSigTimeoutTime_BSM" SG_ 257 CRC_BRAKE2_1 0;
BA_ "GenSigTimeoutTime_BSM2" SG_ 257 CRC_BRAKE2_1 0;
BA_ "GenSigTimeoutTime_CVPAM" SG_ 257 CRC_BRAKE2_1 0;
BA_ "GenSigTimeoutTime_ECM" SG_ 257 CRC_BRAKE2_1 0;
BA_ "GenSigTimeoutTime_EVCU2" SG_ 257 CRC_BRAKE2_1 0;
BA_ "GenSigTimeoutTime_BSM" SG_ 257 Inlet_Pressure_Pos 0;
BA_ "GenSigTimeoutTime_BSM2" SG_ 257 Inlet_Pressure_Pos 0;
BA_ "GenSigTimeoutTime_CVPAM" SG_ 257 Inlet_Pressure_Pos 0;
BA_ "GenSigTimeoutTime_ECM" SG_ 257 Inlet_Pressure_Pos 0;
BA_ "GenSigTimeoutTime_EPS" SG_ 257 Inlet_Pressure_Pos 0;
BA_ "GenSigTimeoutTime_EVCU2" SG_ 257 Inlet_Pressure_Pos 0;
BA_ "GenSigTimeoutTime_ORC" SG_ 257 Inlet_Pressure_Pos 0;
BA_ "GenSigTimeoutTime_BSM" SG_ 257 LHF_Spin_B2 0;
BA_ "GenSigTimeoutTime_BSM2" SG_ 257 LHF_Spin_B2 0;
BA_ "GenSigTimeoutTime_CVPAM" SG_ 257 LHF_Spin_B2 0;
BA_ "GenSigTimeoutTime_ECM" SG_ 257 LHF_Spin_B2 0;
BA_ "GenSigTimeoutTime_EPS" SG_ 257 LHF_Spin_B2 0;
BA_ "GenSigTimeoutTime_EVCU2" SG_ 257 LHF_Spin_B2 0;
BA_ "GenSigTimeoutTime_ORC" SG_ 257 LHF_Spin_B2 0;
BA_ "GenSigTimeoutTime_BSM" SG_ 257 LHF_WheelSensorFailSts_B2 0;
BA_ "GenSigTimeoutTime_BSM2" SG_ 257 LHF_WheelSensorFailSts_B2 0;
BA_ "GenSigTimeoutTime_CVPAM" SG_ 257 LHF_WheelSensorFailSts_B2 0;
BA_ "GenSigTimeoutTime_ECM" SG_ 257 LHF_WheelSensorFailSts_B2 0;
BA_ "GenSigTimeoutTime_EPS" SG_ 257 LHF_WheelSensorFailSts_B2 0;
BA_ "GenSigTimeoutTime_EVCU2" SG_ 257 LHF_WheelSensorFailSts_B2 0;
BA_ "GenSigTimeoutTime_ORC" SG_ 257 LHF_WheelSensorFailSts_B2 0;
BA_ "GenSigTimeoutTime_BSM" SG_ 257 MessageCounter_BRAKE2_1 0;
BA_ "GenSigTimeoutTime_BSM2" SG_ 257 MessageCounter_BRAKE2_1 0;
BA_ "GenSigTimeoutTime_CVPAM" SG_ 257 MessageCounter_BRAKE2_1 0;
BA_ "GenSigTimeoutTime_ECM" SG_ 257 MessageCounter_BRAKE2_1 0;
BA_ "GenSigTimeoutTime_EVCU2" SG_ 257 MessageCounter_BRAKE2_1 0;
BA_ "GenSigTimeoutTime_BSM" SG_ 257 RHF_Spin_B2 0;
BA_ "GenSigTimeoutTime_BSM2" SG_ 257 RHF_Spin_B2 0;
BA_ "GenSigTimeoutTime_CVPAM" SG_ 257 RHF_Spin_B2 0;
BA_ "GenSigTimeoutTime_ECM" SG_ 257 RHF_Spin_B2 0;
BA_ "GenSigTimeoutTime_EPS" SG_ 257 RHF_Spin_B2 0;
BA_ "GenSigTimeoutTime_EVCU2" SG_ 257 RHF_Spin_B2 0;
BA_ "GenSigTimeoutTime_ORC" SG_ 257 RHF_Spin_B2 0;
BA_ "GenSigStartValue" SG_ 257 Ft_RrAxleCoupling_TrqRq_B2 254;
BA_ "GenSigTimeoutTime_BSM" SG_ 257 Ft_RrAxleCoupling_TrqRq_B2 0;
BA_ "GenSigTimeoutTime_BSM2" SG_ 257 Ft_RrAxleCoupling_TrqRq_B2 0;
BA_ "GenSigTimeoutTime_CADM" SG_ 257 Ft_RrAxleCoupling_TrqRq_B2 0;
BA_ "GenSigTimeoutTime_CVPAM" SG_ 257 Ft_RrAxleCoupling_TrqRq_B2 0;
BA_ "GenSigTimeoutTime_ECM" SG_ 257 Ft_RrAxleCoupling_TrqRq_B2 0;
BA_ "GenSigTimeoutTime_EPS" SG_ 257 Ft_RrAxleCoupling_TrqRq_B2 0;
BA_ "GenSigTimeoutTime_EVCU2" SG_ 257 Ft_RrAxleCoupling_TrqRq_B2 0;
BA_ "GenSigTimeoutTime_ORC" SG_ 257 Ft_RrAxleCoupling_TrqRq_B2 0;
BA_ "GenSigTimeoutTime_BSM" SG_ 257 Ft_RrTrqCoupling_ModeRq_B2 0;
BA_ "GenSigTimeoutTime_BSM2" SG_ 257 Ft_RrTrqCoupling_ModeRq_B2 0;
BA_ "GenSigTimeoutTime_CADM" SG_ 257 Ft_RrTrqCoupling_ModeRq_B2 0;
BA_ "GenSigTimeoutTime_CVPAM" SG_ 257 Ft_RrTrqCoupling_ModeRq_B2 0;
BA_ "GenSigTimeoutTime_ECM" SG_ 257 Ft_RrTrqCoupling_ModeRq_B2 0;
BA_ "GenSigTimeoutTime_EPS" SG_ 257 Ft_RrTrqCoupling_ModeRq_B2 0;
BA_ "GenSigTimeoutTime_EVCU2" SG_ 257 Ft_RrTrqCoupling_ModeRq_B2 0;
BA_ "GenSigTimeoutTime_ORC" SG_ 257 Ft_RrTrqCoupling_ModeRq_B2 0;
BA_ "GenSigStartValue" SG_ 257 R_DIFF_TRQ_RQ_B2 511;
BA_ "GenSigTimeoutTime_BSM" SG_ 257 R_DIFF_TRQ_RQ_B2 0;
BA_ "GenSigTimeoutTime_BSM2" SG_ 257 R_DIFF_TRQ_RQ_B2 0;
BA_ "GenSigTimeoutTime_CADM" SG_ 257 R_DIFF_TRQ_RQ_B2 0;
BA_ "GenSigTimeoutTime_CVPAM" SG_ 257 R_DIFF_TRQ_RQ_B2 0;
BA_ "GenSigTimeoutTime_ECM" SG_ 257 R_DIFF_TRQ_RQ_B2 0;
BA_ "GenSigTimeoutTime_EPS" SG_ 257 R_DIFF_TRQ_RQ_B2 0;
BA_ "GenSigTimeoutTime_EVCU2" SG_ 257 R_DIFF_TRQ_RQ_B2 0;
BA_ "GenSigTimeoutTime_ORC" SG_ 257 R_DIFF_TRQ_RQ_B2 0;
BA_ "GenSigTimeoutTime_BSM" SG_ 257 Rear_Diff_BSM_RQ_B2 0;
BA_ "GenSigTimeoutTime_BSM2" SG_ 257 Rear_Diff_BSM_RQ_B2 0;
BA_ "GenSigTimeoutTime_CADM" SG_ 257 Rear_Diff_BSM_RQ_B2 0;
BA_ "GenSigTimeoutTime_CVPAM" SG_ 257 Rear_Diff_BSM_RQ_B2 0;
BA_ "GenSigTimeoutTime_ECM" SG_ 257 Rear_Diff_BSM_RQ_B2 0;
BA_ "GenSigTimeoutTime_EPS" SG_ 257 Rear_Diff_BSM_RQ_B2 0;
BA_ "GenSigTimeoutTime_EVCU2" SG_ 257 Rear_Diff_BSM_RQ_B2 0;
BA_ "GenSigTimeoutTime_ORC" SG_ 257 Rear_Diff_BSM_RQ_B2 0;
BA_ "GenSigTimeoutTime_BSM" SG_ 257 ABSActive_B2 0;
BA_ "GenSigTimeoutTime_BSM2" SG_ 257 ABSActive_B2 0;
BA_ "GenSigTimeoutTime_CVPAM" SG_ 257 ABSActive_B2 0;
BA_ "GenSigTimeoutTime_ECM" SG_ 257 ABSActive_B2 0;
BA_ "GenSigTimeoutTime_EPS" SG_ 257 ABSActive_B2 0;
BA_ "GenSigTimeoutTime_EVCU2" SG_ 257 ABSActive_B2 0;
BA_ "GenSigTimeoutTime_ORC" SG_ 257 ABSActive_B2 0;
BA_ "GenSigTimeoutTime_BSM" SG_ 257 Brk_Stat_B2 0;
BA_ "GenSigTimeoutTime_BSM2" SG_ 257 Brk_Stat_B2 0;
BA_ "GenSigTimeoutTime_CVPAM" SG_ 257 Brk_Stat_B2 0;
BA_ "GenSigTimeoutTime_ECM" SG_ 257 Brk_Stat_B2 0;
BA_ "GenSigTimeoutTime_EPS" SG_ 257 Brk_Stat_B2 0;
BA_ "GenSigTimeoutTime_EVCU2" SG_ 257 Brk_Stat_B2 0;
BA_ "GenSigTimeoutTime_ORC" SG_ 257 Brk_Stat_B2 0;
BA_ "GenSigTimeoutTime_BSM" SG_ 257 RHF_WheelSensorFailSts_B2 0;
BA_ "GenSigTimeoutTime_BSM2" SG_ 257 RHF_WheelSensorFailSts_B2 0;
BA_ "GenSigTimeoutTime_CVPAM" SG_ 257 RHF_WheelSensorFailSts_B2 0;
BA_ "GenSigTimeoutTime_ECM" SG_ 257 RHF_WheelSensorFailSts_B2 0;
BA_ "GenSigTimeoutTime_EPS" SG_ 257 RHF_WheelSensorFailSts_B2 0;
BA_ "GenSigTimeoutTime_EVCU2" SG_ 257 RHF_WheelSensorFailSts_B2 0;
BA_ "GenSigTimeoutTime_ORC" SG_ 257 RHF_WheelSensorFailSts_B2 0;
BA_ "GenSigTimeoutTime_BSM" SG_ 257 LHF_FastPulseCounter_B2 0;
BA_ "GenSigTimeoutTime_BSM2" SG_ 257 LHF_FastPulseCounter_B2 0;
BA_ "GenSigTimeoutTime_CVPAM" SG_ 257 LHF_FastPulseCounter_B2 0;
BA_ "GenSigTimeoutTime_ECM" SG_ 257 LHF_FastPulseCounter_B2 0;
BA_ "GenSigTimeoutTime_EPS" SG_ 257 LHF_FastPulseCounter_B2 0;
BA_ "GenSigTimeoutTime_EVCU2" SG_ 257 LHF_FastPulseCounter_B2 0;
BA_ "GenSigTimeoutTime_ORC" SG_ 257 LHF_FastPulseCounter_B2 0;
BA_ "GenSigTimeoutTime_BSM" SG_ 257 LHFWheelSpeed_B2 0;
BA_ "GenSigTimeoutTime_BSM2" SG_ 257 LHFWheelSpeed_B2 0;
BA_ "GenSigTimeoutTime_CVPAM" SG_ 257 LHFWheelSpeed_B2 0;
BA_ "GenSigTimeoutTime_ECM" SG_ 257 LHFWheelSpeed_B2 0;
BA_ "GenSigTimeoutTime_EPS" SG_ 257 LHFWheelSpeed_B2 0;
BA_ "GenSigTimeoutTime_EVCU2" SG_ 257 LHFWheelSpeed_B2 0;
BA_ "GenSigTimeoutTime_ORC" SG_ 257 LHFWheelSpeed_B2 0;
BA_ "GenSigTimeoutTime_BSM" SG_ 257 RHF_FastPulseCounter_B2 0;
BA_ "GenSigTimeoutTime_BSM2" SG_ 257 RHF_FastPulseCounter_B2 0;
BA_ "GenSigTimeoutTime_CVPAM" SG_ 257 RHF_FastPulseCounter_B2 0;
BA_ "GenSigTimeoutTime_ECM" SG_ 257 RHF_FastPulseCounter_B2 0;
BA_ "GenSigTimeoutTime_EPS" SG_ 257 RHF_FastPulseCounter_B2 0;
BA_ "GenSigTimeoutTime_EVCU2" SG_ 257 RHF_FastPulseCounter_B2 0;
BA_ "GenSigTimeoutTime_ORC" SG_ 257 RHF_FastPulseCounter_B2 0;
BA_ "GenSigTimeoutTime_BSM" SG_ 257 RHFWheelSpeed_B2 0;
BA_ "GenSigTimeoutTime_BSM2" SG_ 257 RHFWheelSpeed_B2 0;
BA_ "GenSigTimeoutTime_CVPAM" SG_ 257 RHFWheelSpeed_B2 0;
BA_ "GenSigTimeoutTime_ECM" SG_ 257 RHFWheelSpeed_B2 0;
BA_ "GenSigTimeoutTime_EPS" SG_ 257 RHFWheelSpeed_B2 0;
BA_ "GenSigTimeoutTime_EVCU2" SG_ 257 RHFWheelSpeed_B2 0;
BA_ "GenSigTimeoutTime_ORC" SG_ 257 RHFWheelSpeed_B2 0;
BA_ "GenSigTimeoutTime_BSM" SG_ 257 VehicleSpeedVSOSig_B2 0;
BA_ "GenSigTimeoutTime_BSM2" SG_ 257 VehicleSpeedVSOSig_B2 0;
BA_ "GenSigTimeoutTime_ECM" SG_ 257 VehicleSpeedVSOSig_B2 0;
BA_ "GenSigTimeoutTime_EVCU2" SG_ 257 VehicleSpeedVSOSig_B2 0;
BA_ "GenSigTimeoutTime_ORC" SG_ 257 VehicleSpeedVSOSig_B2 0;
BA_ "GenSigTimeoutTime_ADCAM" SG_ 524 AEB_Type_Brk_B2 0;
BA_ "GenSigTimeoutTime_CVADAS" SG_ 524 AEB_Type_Brk_B2 0;
BA_ "GenSigTimeoutTime_MPAD" SG_ 524 BSM2_HEALTH_CHECK 0;
BA_ "GenSigTimeoutTime_ADCAM" SG_ 524 BSM2_HEALTH_CHECK 0;
BA_ "GenSigTimeoutTime_CVADAS" SG_ 524 BSM2_HEALTH_CHECK 0;
BA_ "GenSigTimeoutTime_ADCAM" SG_ 524 BrkTrq_B2 0;
BA_ "GenSigTimeoutTime_CVADAS" SG_ 524 BrkTrq_B2 0;
BA_ "GenSigTimeoutTime_ADCAM" SG_ 524 CRC_BRAKE2_2 0;
BA_ "GenSigTimeoutTime_CVADAS" SG_ 524 CRC_BRAKE2_2 0;
BA_ "GenSigTimeoutTime_ADCAM" SG_ 524 MessageCounter_BRAKE2_2 0;
BA_ "GenSigTimeoutTime_CVADAS" SG_ 524 MessageCounter_BRAKE2_2 0;
BA_ "GenSigTimeoutTime_ADCAM" SG_ 524 Brake_OpStat_Sec 0;
BA_ "GenSigTimeoutTime_CVADAS" SG_ 524 Brake_OpStat_Sec 0;
BA_ "GenSigTimeoutTime_ADCAM" SG_ 524 BSM2_OpStat 0;
BA_ "GenSigTimeoutTime_CVADAS" SG_ 524 BSM2_OpStat 0;
BA_ "GenSigTimeoutTime_ADCAM" SG_ 524 VehicleStandStillSts_B2 0;
BA_ "GenSigTimeoutTime_CVADAS" SG_ 524 VehicleStandStillSts_B2 0;
BA_ "GenSigTimeoutTime_BSM" SG_ 524 AEB_Type_Brk_B2 0;
BA_ "GenSigTimeoutTime_BSM2" SG_ 524 AEB_Type_Brk_B2 0;
BA_ "GenSigTimeoutTime_CVPAM" SG_ 524 AEB_Type_Brk_B2 0;
BA_ "GenSigTimeoutTime_ECM" SG_ 524 AEB_Type_Brk_B2 0;
BA_ "GenSigTimeoutTime_EPS" SG_ 524 AEB_Type_Brk_B2 0;
BA_ "GenSigTimeoutTime_EVCU2" SG_ 524 AEB_Type_Brk_B2 0;
BA_ "GenSigTimeoutTime_ORC" SG_ 524 AEB_Type_Brk_B2 0;
BA_ "GenSigTimeoutTime_BSM2" SG_ 524 BSM2_HEALTH_CHECK 0;
BA_ "GenSigTimeoutTime_CADM" SG_ 524 BSM2_HEALTH_CHECK 0;
BA_ "GenSigTimeoutTime_CVPAM" SG_ 524 BSM2_HEALTH_CHECK 0;
BA_ "GenSigTimeoutTime_ECM" SG_ 524 BSM2_HEALTH_CHECK 0;
BA_ "GenSigTimeoutTime_EPS" SG_ 524 BSM2_HEALTH_CHECK 0;
BA_ "GenSigTimeoutTime_EVCU2" SG_ 524 BSM2_HEALTH_CHECK 0;
BA_ "GenSigTimeoutTime_ORC" SG_ 524 BSM2_HEALTH_CHECK 0;
BA_ "GenSigStartValue" SG_ 524 BrkTrq_B2 32767;
BA_ "GenSigTimeoutTime_BSM" SG_ 524 BrkTrq_B2 0;
BA_ "GenSigTimeoutTime_BSM2" SG_ 524 BrkTrq_B2 0;
BA_ "GenSigTimeoutTime_CVPAM" SG_ 524 BrkTrq_B2 0;
BA_ "GenSigTimeoutTime_ECM" SG_ 524 BrkTrq_B2 0;
BA_ "GenSigTimeoutTime_EPS" SG_ 524 BrkTrq_B2 0;
BA_ "GenSigTimeoutTime_EVCU2" SG_ 524 BrkTrq_B2 0;
BA_ "GenSigTimeoutTime_ORC" SG_ 524 BrkTrq_B2 0;
BA_ "GenSigTimeoutTime_BSM2" SG_ 524 CRC_BRAKE2_2 0;
BA_ "GenSigTimeoutTime_CVPAM" SG_ 524 CRC_BRAKE2_2 0;
BA_ "GenSigTimeoutTime_ECM" SG_ 524 CRC_BRAKE2_2 0;
BA_ "GenSigTimeoutTime_EPS" SG_ 524 CRC_BRAKE2_2 0;
BA_ "GenSigTimeoutTime_EVCU2" SG_ 524 CRC_BRAKE2_2 0;
BA_ "GenSigTimeoutTime_BSM2" SG_ 524 MessageCounter_BRAKE2_2 0;
BA_ "GenSigTimeoutTime_CVPAM" SG_ 524 MessageCounter_BRAKE2_2 0;
BA_ "GenSigTimeoutTime_ECM" SG_ 524 MessageCounter_BRAKE2_2 0;
BA_ "GenSigTimeoutTime_EPS" SG_ 524 MessageCounter_BRAKE2_2 0;
BA_ "GenSigTimeoutTime_EVCU2" SG_ 524 MessageCounter_BRAKE2_2 0;
BA_ "GenSigTimeoutTime_BSM" SG_ 524 Brake_OpStat_Sec 0;
BA_ "GenSigTimeoutTime_BSM2" SG_ 524 Brake_OpStat_Sec 0;
BA_ "GenSigTimeoutTime_CVPAM" SG_ 524 Brake_OpStat_Sec 0;
BA_ "GenSigTimeoutTime_ECM" SG_ 524 Brake_OpStat_Sec 0;
BA_ "GenSigTimeoutTime_EPS" SG_ 524 Brake_OpStat_Sec 0;
BA_ "GenSigTimeoutTime_EVCU2" SG_ 524 Brake_OpStat_Sec 0;
BA_ "GenSigTimeoutTime_ORC" SG_ 524 Brake_OpStat_Sec 0;
BA_ "GenSigTimeoutTime_BSM2" SG_ 524 BSM2_OpStat 0;
BA_ "GenSigTimeoutTime_CVPAM" SG_ 524 BSM2_OpStat 0;
BA_ "GenSigTimeoutTime_ECM" SG_ 524 BSM2_OpStat 0;
BA_ "GenSigTimeoutTime_EPS" SG_ 524 BSM2_OpStat 0;
BA_ "GenSigTimeoutTime_EVCU2" SG_ 524 BSM2_OpStat 0;
BA_ "GenSigTimeoutTime_ORC" SG_ 524 BSM2_OpStat 0;
BA_ "GenSigStartValue" SG_ 524 VehicleStandStillSts_B2 1;
BA_ "GenSigTimeoutTime_BSM2" SG_ 524 VehicleStandStillSts_B2 0;
BA_ "GenSigTimeoutTime_CVPAM" SG_ 524 VehicleStandStillSts_B2 0;
BA_ "GenSigTimeoutTime_ECM" SG_ 524 VehicleStandStillSts_B2 0;
BA_ "GenSigTimeoutTime_EPS" SG_ 524 VehicleStandStillSts_B2 0;
BA_ "GenSigTimeoutTime_EVCU2" SG_ 524 VehicleStandStillSts_B2 0;
BA_ "GenSigTimeoutTime_ORC" SG_ 524 VehicleStandStillSts_B2 0;
VAL_ 257 Ft_RrAxleCoupling_TrqRq_B2 255 "SNA";
VAL_ 257 RHF_FastPulseCounter_B2 255 "SNA";
VAL_ 257 LHF_FastPulseCounter_B2 255 "SNA";
VAL_ 262 GasPedalPosition_W 255 "SNA";
VAL_ 258 Slope 255 "SNA";
VAL_ 280 ACC_DsrSpeedKPH 255 "SNA";
VAL_ 280 Object_Dist 255 "SNA";
VAL_ 727 PA_SideSensor_FrontLeft_Dist 1023 "SNA";
VAL_ 727 PA_SideSensor_RearRight_Dist 1023 "SNA";
VAL_ 727 PA_SideSensor_RearLeft_Dist 1023 "SNA";
VAL_ 727 PA_SideSensor_FrontRight_Dist 1023 "SNA";
VAL_ 258 TorqueRequest 2047 "SNA";
VAL_ 258 BrakePedalPressure 2047 "SNA";
VAL_ 258 BrakeBoostPressure 2047 "SNA";
VAL_ 258 TorqueReduct 0 "Not_Active" 1 "Active";
VAL_ 258 TorqueIncrease 0 "Not_Active" 1 "Active";
VAL_ 258 PrefillActive 0 "Not_Active" 1 "Active";
VAL_ 280 HIS_Req 0 "Not_Active" 1 "Active";
VAL_ 280 CIPV_Fused 0 "Not_Active" 1 "Active";
VAL_ 280 Brake_Jerk_Req 0 "Not_Active" 1 "Active";
VAL_ 280 LC_Jerk 0 "Not_Active" 1 "Active";
VAL_ 257 RHF_WheelSensorFailSts_B2 0 "Fail_Not_Present" 1 "Fail_Present";
VAL_ 257 LHF_WheelSensorFailSts_B2 0 "Fail_Not_Present" 1 "Fail_Present";
VAL_ 1156 ABSFailSts_B2 0 "Fail_Not_Present" 1 "Fail_Present";
VAL_ 258 YawRateFailSts_BSM 0 "Fail_Not_Present" 1 "Fail_Present";
VAL_ 258 LongAccelerationFailSts_BSM 0 "Fail_Not_Present" 1 "Fail_Present";
VAL_ 258 LatAccelerationFailSts_BSM 0 "Fail_Not_Present" 1 "Fail_Present";
VAL_ 280 DDD_SystemSts 0 "OFF" 1 "ON";
VAL_ 280 PEB_SystemSts 0 "OFF" 1 "ON";
VAL_ 280 CADM2_EPSSEC_FAIL 0 "False" 1 "True";
VAL_ 280 ESA_FailSts 0 "False" 1 "True";
VAL_ 727 PA_Right_Sensor_Det_Health 0 "Active" 1 "Not_Active_blocked" 2 "Not_Active_failure" 3 "SNA";
VAL_ 727 PA_Left_Sensor_Det_Health 0 "Active" 1 "Not_Active_blocked" 2 "Not_Active_failure" 3 "SNA";
VAL_ 727 PA_Lane_Dection_Health 0 "Active" 1 "Not_Active_blocked" 2 "Not_Active_failure" 3 "SNA";
VAL_ 726 PA_Front_Sensor_Det_Health 0 "Active" 1 "Not_Active_blocked" 2 "Not_Active_failure" 3 "SNA";
VAL_ 258 WheelRPM_FR 65535 "SNA";
VAL_ 258 WheelRPM_FL 65535 "SNA";
VAL_ 262 GasPedalPositionFailSts_W 0 "Fail_not_present" 1 "Fail_present";
VAL_ 262 EngineSpeed_W 16383 "SNA";
VAL_ 258 VehicleSpeedVSOSig 8191 "SNA";
VAL_ 257 VehicleSpeedVSOSig_B2 8191 "SNA";
VAL_ 257 RHFWheelSpeed_B2 8191 "SNA";
VAL_ 257 LHFWheelSpeed_B2 8191 "SNA";
VAL_ 262 EngineSts_W 0 "Engine_Off" 1 "Engine_Cranking" 2 "Engine_On" 3 "SNA";
VAL_ 257 R_DIFF_TRQ_RQ_B2 511 "SNA";
VAL_ 258 YawRate_BSM 4095 "SNA";
VAL_ 258 LatAcceleration_BSM 4095 "SNA";
VAL_ 258 LongAcceleration_BSM 4095 "SNA";
VAL_ 280 Intervention 4095 "SNA";
VAL_ 258 ABSActive 0 "Not_active" 1 "Active";
VAL_ 258 ESCActive 0 "Not_active" 1 "Active";
VAL_ 1156 BSM2_FaultSts 0 "Not_active" 1 "Active";
VAL_ 257 ABSActive_B2 0 "Not_active" 1 "Active";
VAL_ 257 Ft_RrTrqCoupling_ModeRq_B2 0 "FREE" 1 "HOLD" 2 "OPEN" 3 "SNA";
VAL_ 257 Rear_Diff_BSM_RQ_B2 0 "FREE" 1 "HOLD" 2 "OPEN" 3 "SNA";
VAL_ 258 Brk_Stat 0 "IDLE" 1 "BRAKING" 2 "NDEF2" 3 "SNA";
VAL_ 257 Brk_Stat_B2 0 "IDLE" 1 "BRAKING" 2 "NDEF2" 3 "SNA";
VAL_ 258 BrakeInterventionSts 0 "No_active_brake_intervention" 1 "Active_brake_intervention";
VAL_ 280 DDD_Setting_Avail 0 "Available" 1 "Not_Available";
VAL_ 258 ESP_Sys_Stat 0 "ABSERR_DIAG" 1 "NORM" 2 "HALF" 3 "ABGAS";
VAL_ 280 ACC_Engine_Torque_Enabled 0 "Not_Enabled" 1 "Enabled";
VAL_ 280 ACC_Drive_Cmd 0 "Not_Enabled" 1 "Enabled";
VAL_ 258 PPPA_Engine_Torque_Enabled_BSM 0 "Not_Enabled" 1 "Enabled";
VAL_ 262 LV12PwrFreeRq_W 0 "Level 1 or 2 Power free Mode NOT active" 1 "Level 1 or 2 Power free Mode Active";
VAL_ 262 ECM_LHOM_W 0 "Not_In_Limp_Home" 1 "In_Limp_Home";
VAL_ 258 InternalError_BSM 0 "No_int_processing_error_detected" 1 "Int_processing_error_detected";
VAL_ 257 RHF_Spin_B2 0 "Stand_Still" 1 "Forward" 2 "Backward" 3 "SNA";
VAL_ 257 LHF_Spin_B2 0 "Stand_Still" 1 "Forward" 2 "Backward" 3 "SNA";
VAL_ 258 Brake_MaxRegen_Ready 0 "Not_Ready" 1 "Ready";
VAL_ 262 ESS_ENG_ST_W 1 "ENS Stopped / ENS_STOPPED" 2 "ENS Request Start / ENS_RQ_ST" 3 "ENS Running / ENS_RUN" 4 "ENS Stop Pending / ENS_STOP_PEND" 5 "ENS Start protection / ENS_ST_PRTCT" 6 "ENS Start inhibit / ENS_ST_INH" 7 "ENS disabled / ENS_DSBL" 8 "ENS_IHB_LATCH" 9 "ENS Starting / ENS_Starting" 15 "SNA";
VAL_ 280 Prefill_Req 0 "No_Prefill_Requested" 1 "Prefill_Requested";
VAL_ 280 GrMax_Rq_ACC 0 "Passive" 1 "G1" 2 "G2" 3 "G3" 4 "G4" 5 "G5" 6 "G6" 7 "G7" 8 "G8" 9 "G9" 10 "G10" 11 "G11" 12 "G12" 13 "G13" 14 "G14" 15 "G15";
VAL_ 524 VehicleStandStillSts_B2 0 "True" 1 "False" 3 "SNA";
VAL_ 524 BrkTrq_B2 32767 "SNA";
VAL_ 257 Inlet_Pressure_Pos 0 "False" 1 "True" 3 "SNA";
VAL_ 2654486529 CBV_bit6_PartialNtwInfBit_1E384001 0 "NM_PDU_contains_no_Partial_Network_request_information" 1 "NM_PDU_contains_Partial_Network_request_information";
VAL_ 2654486552 CBV_bit6_PartialNtwInfBit_1E384018 0 "NM_PDU_contains_no_Partial_Network_request_information" 1 "NM_PDU_contains_Partial_Network_request_information";
VAL_ 2654486676 CBV_bit6_PartialNtwInfBit_1E384094 0 "NM_PDU_contains_no_Partial_Network_request_information" 1 "NM_PDU_contains_Partial_Network_request_information";
VAL_ 2654486669 CBV_bit6_PartialNtwInfBit_1E38408D 0 "NM_PDU_contains_no_Partial_Network_request_information" 1 "NM_PDU_contains_Partial_Network_request_information";
VAL_ 2654486530 CBV_bit6_PartialNtwInfBit_1E384002 0 "NM_PDU_contains_no_Partial_Network_request_information" 1 "NM_PDU_contains_Partial_Network_request_information";
VAL_ 2654486534 CBV_bit6_PartialNtwInfBit_1E384006 0 "NM_PDU_contains_no_Partial_Network_request_information" 1 "NM_PDU_contains_Partial_Network_request_information";
VAL_ 2654486676 CBV_bit4_ActiveWakeupBit_1E384094 0 "PassiveWakeup" 1 "ActiveWakeup";
VAL_ 2654486534 CBV_bit4_ActiveWakeupBit_1E384006 0 "PassiveWakeup" 1 "ActiveWakeup";
VAL_ 2654486530 CBV_bit4_ActiveWakeupBit_1E384002 0 "PassiveWakeup" 1 "ActiveWakeup";
VAL_ 2654486669 CBV_bit4_ActiveWakeupBit_1E38408D 0 "PassiveWakeup" 1 "ActiveWakeup";
VAL_ 2654486552 CBV_bit4_ActiveWakeupBit_1E384018 0 "PassiveWakeup" 1 "ActiveWakeup";
VAL_ 2654486529 CBV_bit4_ActiveWakeupBit_1E384001 0 "PassiveWakeup" 1 "ActiveWakeup";
VAL_ 2654486529 CBV_bit3_NMCoordinatorBit_1E384001 0 "Start_of_synchronized_shutdown_is_not_requested_by_main_coordinator" 1 "Start_of_synchronized_shutdown_is_requested_by_main_coordinator";
VAL_ 2654486552 CBV_bit3_NMCoordinatorBit_1E384018 0 "Start_of_synchronized_shutdown_is_not_requested_by_main_coordinator" 1 "Start_of_synchronized_shutdown_is_requested_by_main_coordinator";
VAL_ 2654486530 CBV_bit3_NMCoordinatorBit_1E384002 0 "Start_of_synchronized_shutdown_is_not_requested_by_main_coordinator" 1 "Start_of_synchronized_shutdown_is_requested_by_main_coordinator";
VAL_ 2654486669 CBV_bit3_NMCoordinatorBit_1E38408D 0 "Start_of_synchronized_shutdown_is_not_requested_by_main_coordinator" 1 "Start_of_synchronized_shutdown_is_requested_by_main_coordinator";
VAL_ 2654486676 CBV_bit3_NMCoordinatorBit_1E384094 0 "Start_of_synchronized_shutdown_is_not_requested_by_main_coordinator" 1 "Start_of_synchronized_shutdown_is_requested_by_main_coordinator";
VAL_ 2654486534 CBV_bit3_NMCoordinatorBit_1E384006 0 "Start_of_synchronized_shutdown_is_not_requested_by_main_coordinator" 1 "Start_of_synchronized_shutdown_is_requested_by_main_coordinator";
VAL_ 2654486534 CBV_bit0_RepeatMessageRequestBit_1E384006 0 "Repeat_Message_State_not_requested" 1 "Repeat_Message_State_requested";
VAL_ 2654486676 CBV_bit0_RepeatMessageRequestBit_1E384094 0 "Repeat_Message_State_not_requested" 1 "Repeat_Message_State_requested";
VAL_ 2654486669 CBV_bit0_RepeatMessageRequestBit_1E38408D 0 "Repeat_Message_State_not_requested" 1 "Repeat_Message_State_requested";
VAL_ 2654486530 CBV_bit0_RepeatMessageRequestBit_1E384002 0 "Repeat_Message_State_not_requested" 1 "Repeat_Message_State_requested";
VAL_ 2654486552 CBV_bit0_RepeatMessageRequestBit_1E384018 0 "Repeat_Message_State_not_requested" 1 "Repeat_Message_State_requested";
VAL_ 2654486529 CBV_bit0_RepeatMessageRequestBit_1E384001 0 "Repeat_Message_State_not_requested" 1 "Repeat_Message_State_requested";
VAL_ 258 BrakeBoostStat 0 "INIT_Bst" 1 "Normal_Bst" 2 "Limited_Bst" 3 "Shutdown_Bst" 4 "MOCO" 5 "Half_Sys_Bst" 6 "No_Bst" 15 "SNA";
VAL_ 262 PowertrainPrplsnActv 0 "Off" 1 "Active";
VAL_ 1156 RollsModeAct_B2 0 "No Fault" 1 "Fault";
VAL_ 280 SteeringVibration_Type 0 "TYPE_0" 1 "TYPE_1" 2 "TYPE_2" 3 "TYPE_3" 4 "TYPE_4" 5 "TYPE_5" 6 "TYPE_6" 7 "TYPE_7" 8 "TYPE_8" 9 "TYPE_9" 10 "TYPE_10" 11 "TYPE_11" 15 "SNA";
VAL_ 280 SteeringVibration_Rq 0 "NOT_REQUESTED" 1 "REQUESTED";
VAL_ 280 LKA_LAT_CTRL_RequestSts 0 "Idle" 1 "Faulted" 2 "LKA_Request";
VAL_ 280 HAS_LAT_CTRL_RequestSts 0 "Idle" 1 "Faulted" 2 "HAS_Request";
VAL_ 280 AEB_Systemsts 0 "FCW_Off" 1 "FCW_On_Only_Warning" 2 "FCW_On_Full";
VAL_ 280 ACC_StopStart 0 "DEFAULT" 1 "AutoStop_Allowed" 2 "AutoStart_Allowed" 3 "SNA";
VAL_ 280 CADM_OpStat 0 "Inactive" 1 "FullService" 2 "FailOperational" 3 "FailDegraded" 4 "Emergency" 5 "No_Function";
VAL_ 524 BSM2_OpStat 0 "Inactive" 1 "FullService" 2 "FailOperational" 3 "FailDegraded" 4 "Emergency" 5 "No_Function";
VAL_ 524 Brake_OpStat_Sec 0 "Inactive" 1 "FullService" 2 "FailOperational" 3 "FailDegraded" 4 "Emergency" 5 "No_Function";
VAL_ 280 HAS_OpStat_Prim 0 "Inactive" 1 "FullService" 2 "FailOperational" 3 "FailDegraded" 4 "Emergency" 5 "No_Function";
VAL_ 524 AEB_Type_Brk_B2 0 "NONE" 1 "ACC" 2 "CMS" 3 "CMS_XTD" 4 "ABA" 5 "LSCM" 6 "PEB" 7 "ICA_L" 8 "ICA_R" 9 "HAS_MRM" 15 "SNA";
VAL_ 280 MRM_STATUS 0 "Not_Active" 1 "MRM_in_Process" 2 "Vehicle_Secure_Request" 3 "Vehicle_Securement_Complete" 4 "Canceled" 7 "SNA";
VAL_ 280 HAS_Status 0 "Disabled" 1 "Enabled" 2 "Engaged" 3 "Faulted";
VAL_ 280 LANE_CHANGE_SIDE 0 "NO_CHNG" 1 "RIGHT" 2 "LEFT";
VAL_ 280 ESCALATION_TYPE 0 "None" 1 "Driver_Inattention" 2 "Low_Urgency" 3 "Med_Urgency" 4 "High_Urgency";
VAL_ 280 AEB_Sensitivity_Setting 0 "NEAR" 1 "MEDIUM" 2 "FAR";
VAL_ 258 ParkingGearShiftReq_BSM 0 "Idle" 1 "P" 2 "R" 3 "N" 4 "D" 7 "SNA";
VAL_ 726 PA_Obj1_Conf 0 "N/A" 1 "LOW" 2 "MED" 3 "HI";
VAL_ 727 PA_SideSensor_RearRight_Conf 0 "N/A" 1 "LOW" 2 "MED" 3 "HI";
VAL_ 727 PA_SideSensor_FrontRight_Conf 0 "N/A" 1 "LOW" 2 "MED" 3 "HI";
VAL_ 727 PA_SideSensor_RearLeft_Conf 0 "N/A" 1 "LOW" 2 "MED" 3 "HI";
VAL_ 726 PA_Obj6_Conf 0 "N/A" 1 "LOW" 2 "MED" 3 "HI";
VAL_ 727 PA_SideSensor_FrontLeft_Conf 0 "N/A" 1 "LOW" 2 "MED" 3 "HI";
VAL_ 726 PA_Obj2_Conf 0 "N/A" 1 "LOW" 2 "MED" 3 "HI";
VAL_ 726 PA_Obj3_Conf 0 "N/A" 1 "LOW" 2 "MED" 3 "HI";
VAL_ 726 PA_Obj4_Conf 0 "N/A" 1 "LOW" 2 "MED" 3 "HI";
VAL_ 726 PA_Obj5_Conf 0 "N/A" 1 "LOW" 2 "MED" 3 "HI";
VAL_ 727 PA_Line_RM_Style 0 "None" 1 "Solid" 2 "Dashed" 3 "Double" 4 "Road_Edge" 5 "Botts_Dot" 6 "Barrier" 7 "Other";
VAL_ 727 PA_Line_LM_Style 0 "None" 1 "Solid" 2 "Dashed" 3 "Double" 4 "Road_Edge" 5 "Botts_Dot" 6 "Barrier" 7 "Other";
VAL_ 727 PA_Line_LM_Color 0 "None" 1 "White" 2 "Yellow" 3 "Orange" 4 "Other";
VAL_ 727 PA_Line_RM_Color 0 "None" 1 "White" 2 "Yellow" 3 "Orange" 4 "Other";
VAL_ 726 PA_Obj6_Type 0 "None" 1 "Point" 2 "Straight_0_Corner" 3 "Straight_1_Corner" 4 "Straight_2_Corner";
VAL_ 726 PA_Obj5_Type 0 "None" 1 "Point" 2 "Straight_0_Corner" 3 "Straight_1_Corner" 4 "Straight_2_Corner";
VAL_ 726 PA_Obj4_Type 0 "None" 1 "Point" 2 "Straight_0_Corner" 3 "Straight_1_Corner" 4 "Straight_2_Corner";
VAL_ 726 PA_Obj3_Type 0 "None" 1 "Point" 2 "Straight_0_Corner" 3 "Straight_1_Corner" 4 "Straight_2_Corner";
VAL_ 726 PA_Obj2_Type 0 "None" 1 "Point" 2 "Straight_0_Corner" 3 "Straight_1_Corner" 4 "Straight_2_Corner";
VAL_ 726 PA_Obj1_Type 0 "None" 1 "Point" 2 "Straight_0_Corner" 3 "Straight_1_Corner" 4 "Straight_2_Corner";
VAL_ 258 ParkingInterventionSts 0 "Not_Active" 1 "Active" 2 "Faulted_External" 3 "Faulted_Internal";
VAL_ 280 ACC_Systemsts 0 "OFF" 1 "ACC_Enabled" 2 "ACC_Engaged" 3 "ACC_Engaged_BrakeOnly" 4 "ACC_Cancel" 5 "NCC_Enabled" 6 "NCC_Engaged" 7 "NCC_Cancel" 8 "HAS_BSoC" 9 "RRCC_Enabled_No_Set_Speed" 10 "RRCC_Enabled_With_Set_Speed" 11 "RRCC_Engaged" 15 "SNA";
VAL_ 280 AEB_Type 0 "NONE" 1 "ACC" 2 "CMS" 3 "CMS_XTD" 4 "ABA" 5 "LSCM" 6 "PEB" 7 "ICA_L" 8 "ICA_R" 9 "HAS_MRM" 10 "RRCC" 15 "SNA";
VAL_ 280 LANE_CHANGE_STATUS 0 "NO_CHNG" 1 "PEND" 2 "EARLY1" 3 "EARLY2" 4 "LATE" 5 "ABORTING" 6 "ABORTED" 7 "COMPL" 8 "LOCKOUT" 9 "CANCELLING" 10 "CANCELLED" 11 "Msg_11" 12 "Msg_12" 13 "Msg_13" 14 "Msg_14" 15 "SNA";
VAL_ 258 BSM_ESASystemSts 0 "Not_Enabled" 1 "Pending" 2 "Pre_Active" 3 "Active" 4 "Locked" 5 "Temporarily_Not_Avail" 6 "Permanently_Not_Avail" 7 "SNA";
VAL_ 280 ESASystemSts 0 "Not_Enabled" 1 "Pending" 2 "Pre_Active" 3 "Active" 4 "Locked" 5 "Temporarily_Not_Avail" 6 "Permanently_Not_Available" 7 "SNA";
VAL_ 280 ESA_LAT_CTRL_RequestSts 0 "No_Request" 1 "ESA_Request" 2 "Faulted" 3 "SNA";
VAL_ 280 ESA_LaneClear_Status 0 "NONE" 1 "Left_Clear" 2 "Right_Clear" 3 "Both_Clear" 4 "Neither-Clear" 5 "Undetermined" 7 "SNA";
VAL_ 727 PA_Line_RM_Heading_Conf 0 "None" 1 "Low" 2 "Medium" 3 "High";
VAL_ 727 PA_Line_RM_Distance_Conf 0 "None" 1 "Low" 2 "Medium" 3 "High";
VAL_ 727 PA_Line_LM_Heading_Conf 0 "None" 1 "Low" 2 "Medium" 3 "High";
VAL_ 727 PA_Line_LM_Distance_Conf 0 "None" 1 "Low" 2 "Medium" 3 "High";
SIG_GROUP_ 262 ENGINE_FD_2_Pkt 1 : PowertrainPrplsnActv MessageCounter_ENGINE2 LV12PwrFreeRq_W GasPedalPositionFailSts_W GasPedalPosition_W ESS_ENG_ST_W EngineSts_W EngineSpeed_W ECM_LHOM_W CRC_ENGINE2;
SIG_GROUP_ 258 BRAKE_FD_2_Pkt 1 : YawRateFailSts_BSM YawRate_BSM VehicleSpeedVSOSig TorqueRequest TorqueReduct TorqueIncrease Slope PrefillActive MessageCounter_BRAKE2 LongAccelerationFailSts_BSM LongAcceleration_BSM LatAccelerationFailSts_BSM LatAcceleration_BSM InternalError_BSM ESP_Sys_Stat ESCActive CRC_BRAKE2 BrakePedalPressure BrakeInterventionSts BrakeBoostStat BrakeBoostPressure Brake_MaxRegen_Ready ABSActive WheelRPM_FR WheelRPM_FL Brk_Stat PPPA_Engine_Torque_Enabled_BSM ParkingGearShiftReq_BSM ParkingInterventionSts BSM_ESASystemSts;
SIG_GROUP_ 524 BRAKE2_FD_2_Pkt 1 : VehicleStandStillSts_B2 BSM2_OpStat Brake_OpStat_Sec MessageCounter_BRAKE2_2 CRC_BRAKE2_2 BrkTrq_B2 BSM2_HEALTH_CHECK AEB_Type_Brk_B2;
SIG_GROUP_ 257 BRAKE2_FD_1_Pkt 1 : VehicleSpeedVSOSig_B2 RHFWheelSpeed_B2 RHF_FastPulseCounter_B2 LHFWheelSpeed_B2 LHF_FastPulseCounter_B2 RHF_WheelSensorFailSts_B2 RHF_Spin_B2 MessageCounter_BRAKE2_1 LHF_WheelSensorFailSts_B2 LHF_Spin_B2 Inlet_Pressure_Pos CRC_BRAKE2_1 Brk_Stat_B2 ABSActive_B2 Rear_Diff_BSM_RQ_B2 R_DIFF_TRQ_RQ_B2 Ft_RrTrqCoupling_ModeRq_B2 Ft_RrAxleCoupling_TrqRq_B2;
SIG_GROUP_ 727 CVPAM_FD_Data2_Pkt 1 : PA_SideSensor_RearRight_Dist PA_SideSensor_RearRight_Conf PA_SideSensor_RearLeft_Dist PA_SideSensor_RearLeft_Conf PA_SideSensor_FrontRight_Dist PA_SideSensor_FrontRight_Conf PA_SideSensor_FrontLeft_Dist PA_SideSensor_FrontLeft_Conf PA_Right_Sensor_Det_Health PA_Line_RM_Style PA_Line_RM_Heading PA_Line_RM_Color PA_Line_LM_Style PA_Line_LM_Heading PA_Line_LM_Color PA_Left_Sensor_Det_Health PA_Lane_Dection_Health MessageCounter_CVPAM_FD_Data2 MAC_CVPAM_FD_Data2 CRC_CVPAM_FD_Data2 Cntr_CVPAM_FD_Data2 PA_Line_RM_Heading_Conf PA_Line_RM_Distance_Conf PA_Line_RM_Distance PA_Line_LM_Heading_Conf PA_Line_LM_Distance_Conf PA_Line_LM_Distance Reserved_for_Functional_Safety_;
SIG_GROUP_ 726 CVPAM_FD_Data_Pkt 1 : PA_Obj6_Type PA_Obj6_Range_2 PA_Obj6_Range PA_Obj6_Conf PA_Obj6_Angle_2 PA_Obj6_Angle PA_Obj5_Type PA_Obj5_Range_2 PA_Obj5_Range PA_Obj5_Conf PA_Obj5_Angle_2 PA_Obj5_Angle PA_Obj4_Type PA_Obj4_Range_2 PA_Obj4_Range PA_Obj4_Conf PA_Obj4_Angle_2 PA_Obj4_Angle PA_Obj3_Type PA_Obj3_Range_2 PA_Obj3_Range PA_Obj3_Conf PA_Obj3_Angle_2 PA_Obj3_Angle PA_Obj2_Type PA_Obj2_Range_2 PA_Obj2_Range PA_Obj2_Conf PA_Obj2_Angle_2 PA_Obj2_Angle PA_Obj1_Type PA_Obj1_Range_2 PA_Obj1_Range PA_Obj1_Conf PA_Obj1_Angle_2 PA_Obj1_Angle PA_Front_Sensor_Det_Health MessageCounter_CVPAM_FD_Data MAC_CVPAM_FD_Data CRC_CVPAM_FD_Data Cntr_CVPAM_FD_Data Reserved_for_functional_safety_2D6;
SIG_GROUP_ 1156 BRAKE2_FD_3_Pkt 1 : RollsModeAct_B2 MessageCounter_BRAKE2_3 CRC_BRAKE2_3 BSM2_FaultSts ABSFailSts_B2;
SIG_GROUP_ 280 ADAS_FD_INFO_Pkt 1 : Object_Dist MessageCounter_ADAS_FD_INFO CRC_ADAS_FD_INFO ACC_DsrSpeedKPH Intervention HIS_Req GrMax_Rq_ACC CIPV_Fused Brake_Jerk_Req ACC_Engine_Torque_Enabled ACC_Drive_Cmd Prefill_Req PEB_SystemSts MRM_STATUS LANE_CHANGE_SIDE HAS_Status HAS_OpStat_Prim HAS_LAT_CTRL_RequestSts ESCALATION_TYPE DDD_SystemSts DDD_Setting_Avail CADM_OpStat AEB_Type AEB_Systemsts AEB_Sensitivity_Setting ACC_Systemsts ACC_StopStart SteeringVibration_Type SteeringVibration_Rq LKA_LAT_CTRL_RequestSts LANE_CHANGE_STATUS LC_Jerk CADM2_EPSSEC_FAIL TorqueOverlaySteeringReq ESASystemSts ESA_TorqueOverlaySteeringReq ESA_LAT_CTRL_RequestSts ESA_LaneClear_Status ESA_FailSts;
